VERSION "HNNBNNNYNNNNNNNNNNNNNNNNNNNNNNNNNNNNNNNNNN/4/%%%/4/'%**4NNN///"

NS_ :

BS_:

BU_: BAP_Tester CGS Gateway Gateway_PAG HUD Kombi Kombi_LB Kombi_PAG Waehlhebel_SB

BO_ 1607 Motor_09: 8 Gateway
 SG_ MO_ITM_Kuehlmittel_Temp : 0|8@1+ (0.75,-48) [-45.75|143.25] "Unit_DegreCelsi"  Kombi,Kombi_LB,Kombi_PAG
 SG_ MO_E85_Sensor : 8|4@1+ (10,0) [0|100] "Unit_PerCent"  Vector__XXX
 SG_ SCR_Anz_Motorstarts : 12|4@1+ (1.0,0.0) [0.0|15] ""  Vector__XXX
 SG_ SCR_Reichweite : 16|15@1+ (1,0) [0|32766] "Unit_KiloMeter"  Vector__XXX
 SG_ MO_Ethanol_Spuelhinweis : 31|1@1+ (1.0,0.0) [0.0|1] ""  Vector__XXX
 SG_ SCR_Warnstufe_1 : 32|1@1+ (1.0,0.0) [0.0|1] ""  Vector__XXX
 SG_ SCR_Warnstufe_2 : 33|1@1+ (1.0,0.0) [0.0|1] ""  Vector__XXX
 SG_ SCR_Text : 34|3@1+ (1.0,0.0) [0.0|7] ""  Kombi,Kombi_PAG
 SG_ SCR_Akustik : 37|2@1+ (1.0,0.0) [0.0|3] ""  Vector__XXX
 SG_ SCR_verbaut : 39|1@1+ (1.0,0.0) [0.0|1] ""  Kombi,Kombi_PAG
 SG_ MO_Kraftstofffilter_Wasser : 40|1@1+ (1.0,0.0) [0.0|1] ""  Kombi,Kombi_LB,Kombi_PAG
 SG_ SCR_Systemfehler : 41|1@1+ (1.0,0.0) [0.0|1] ""  Vector__XXX
 SG_ SCR_Inducement_Strategie : 42|2@1+ (1.0,0.0) [0.0|3] ""  Kombi,Kombi_PAG
 SG_ MO_CO2_Faktor : 44|12@1+ (1,0) [1|4094] "Unit_GramPerLiter"  Vector__XXX
 SG_ MO_MKB_MUX M  : 56|2@1+ (1.0,0.0) [0.0|3] ""  Kombi,Kombi_LB,Kombi_PAG
 SG_ MO_MKB_01 m0  : 59|5@1+ (1.0,0.0) [0.0|31] ""  Kombi,Kombi_LB,Kombi_PAG
 SG_ MO_MKB_02 m1  : 59|5@1+ (1.0,0.0) [0.0|31] ""  Kombi,Kombi_LB,Kombi_PAG
 SG_ MO_MKB_03 m2  : 59|5@1+ (1.0,0.0) [0.0|31] ""  Kombi,Kombi_LB,Kombi_PAG
 SG_ MO_MKB_04 m3  : 59|5@1+ (1.0,0.0) [0.0|31] ""  Kombi,Kombi_LB,Kombi_PAG

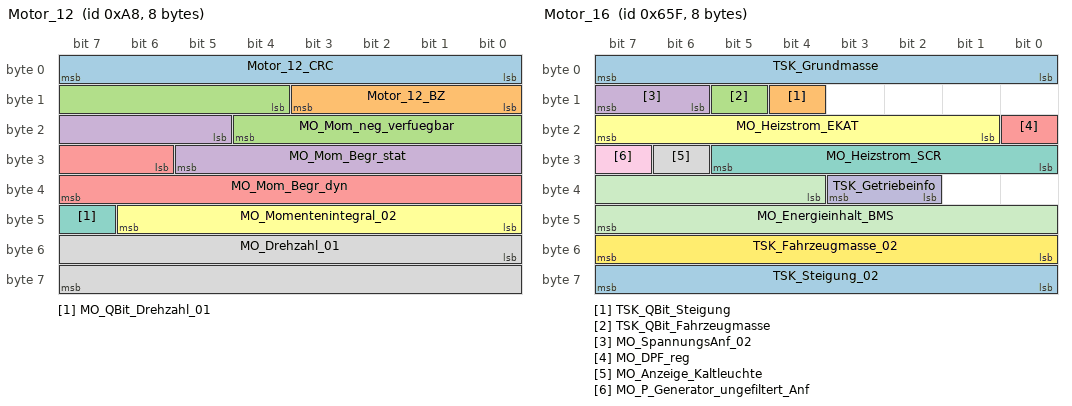
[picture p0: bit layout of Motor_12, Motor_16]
BO_ 168 Motor_12: 8 Gateway
 SG_ Motor_12_CRC : 0|8@1+ (1,0) [0|255] ""  Vector__XXX
 SG_ Motor_12_BZ : 8|4@1+ (1,0) [0|15] ""  Vector__XXX
 SG_ MO_Mom_neg_verfuegbar : 12|9@1+ (1,-509) [-509|0] ""  Vector__XXX
 SG_ MO_Mom_Begr_stat : 21|9@1+ (1,0) [0|509] ""  Vector__XXX
 SG_ MO_Mom_Begr_dyn : 30|10@1+ (1,-509) [-509|509] ""  Vector__XXX
 SG_ MO_Momentenintegral_02 : 40|7@1+ (1,0) [0|100] "Unit_PerCent"  Vector__XXX
 SG_ MO_QBit_Drehzahl_01 : 47|1@1+ (1.0,0.0) [0.0|1] ""  Vector__XXX
 SG_ MO_Drehzahl_01 : 48|16@1+ (0.25,0) [0.00|16383.00] "Unit_MinutInver"  Kombi,Kombi_LB,Kombi_PAG

BO_ 958 Motor_14: 8 Gateway
 SG_ Motor_14_CRC : 0|8@1+ (1,0) [0|255] ""  CGS,Kombi_PAG
 SG_ Motor_14_BZ : 8|4@1+ (1,0) [0|15] ""  CGS,Kombi_PAG
 SG_ MO_StartStopp_Status : 12|2@1+ (1.0,0.0) [0.0|3] ""  Vector__XXX
 SG_ MO_StartStopp_Wiederstart : 14|1@1+ (1.0,0.0) [0.0|1] ""  CGS,Kombi,Kombi_LB,Kombi_PAG,Waehlhebel_SB
 SG_ MO_StartStopp_Motorstopp : 15|1@1+ (1.0,0.0) [0.0|1] ""  Kombi,Kombi_LB,Kombi_PAG
 SG_ MO_Freig_Reku : 16|2@1+ (1.0,0.0) [0.0|3] ""  Vector__XXX
 SG_ MO_Kl_75 : 18|1@1+ (1.0,0.0) [0.0|1] ""  CGS,Kombi,Kombi_LB,Kombi_PAG,Waehlhebel_SB
 SG_ MO_Kl_50 : 19|1@1+ (1.0,0.0) [0.0|1] ""  Vector__XXX
 SG_ MO_Gangposition : 20|4@1+ (1.0,0.0) [0.0|15] ""  Kombi,Kombi_PAG
 SG_ MO_StartStopp_Fahrerwunsch : 24|2@1+ (1.0,0.0) [0.0|3] ""  Vector__XXX
 SG_ MO_HYB_Fahrbereitschaft : 26|1@1+ (1.0,0.0) [0.0|1] ""  Kombi,Kombi_LB,Kombi_PAG
 SG_ MO_Ext_E_Fahrt_aktiv : 27|1@1+ (1.0,0.0) [0.0|1] ""  Kombi,Kombi_LB,Kombi_PAG
 SG_ MO_Fahrer_bremst : 28|1@1+ (1.0,0.0) [0.0|1] ""  CGS
 SG_ MO_QBit_Fahrer_bremst : 29|1@1+ (1.0,0.0) [0.0|1] ""  CGS
 SG_ MO_BLS : 30|1@1+ (1.0,0.0) [0.0|1] ""  CGS
 SG_ MO_Konsistenz_Bremsped : 31|1@1+ (1.0,0.0) [0.0|1] ""  CGS
 SG_ MO_KomFehler_ESP : 32|1@1+ (1.0,0.0) [0.0|1] ""  Vector__XXX
 SG_ MO_Klima_Eingr : 33|2@1+ (1.0,0.0) [0.0|3] ""  Vector__XXX
 SG_ MO_Aussp_Anlass : 35|1@1+ (1.0,0.0) [0.0|1] ""  Vector__XXX
 SG_ MO_Freig_Anlass : 36|1@1+ (1.0,0.0) [0.0|1] ""  Vector__XXX
 SG_ MO_Kuppl_schalter : 37|1@1+ (1.0,0.0) [0.0|1] ""  Kombi,Kombi_LB
 SG_ MO_Interlock : 38|1@1+ (1.0,0.0) [0.0|1] ""  Vector__XXX
 SG_ MO_Motor_laeuft : 39|1@1+ (1.0,0.0) [0.0|1] ""  Kombi,Kombi_LB,Kombi_PAG
 SG_ MO_Kickdown : 40|1@1+ (1.0,0.0) [0.0|1] ""  Vector__XXX
 SG_ MO_QBit_KL_75 : 41|1@1+ (1.0,0.0) [0.0|1] ""  CGS,Waehlhebel_SB
 SG_ MO_EKlKomLeiRed : 42|2@1+ (1.0,0.0) [0.0|3] ""  Vector__XXX
 SG_ MO_Handshake_STH : 44|1@1+ (1.0,0.0) [0.0|1] ""  Vector__XXX
 SG_ MO_BKV_Unterdruckwarnung : 45|1@1+ (1.0,0.0) [0.0|1] ""  Vector__XXX
 SG_ MO_Freigabe_Segeln : 46|1@1+ (1.0,0.0) [0.0|1] ""  Vector__XXX
 SG_ MO_PTC_Status : 47|3@1+ (1.0,0.0) [0.0|7] ""  Vector__XXX
 SG_ MO_QBit_Gangposition : 50|1@1+ (1.0,0.0) [0.0|1] ""  Vector__XXX
 SG_ MO_Signalquelle_Gangposition : 51|1@1+ (1.0,0.0) [0.0|1] ""  Vector__XXX
 SG_ MO_Remotestart_Betrieb : 52|1@1+ (1.0,0.0) [0.0|1] ""  Vector__XXX
 SG_ MO_Remotestart_moeglich : 53|1@1+ (1.0,0.0) [0.0|1] ""  Vector__XXX
 SG_ MO_Text_Geschw_red : 54|1@1+ (1.0,0.0) [0.0|1] ""  Kombi,Kombi_LB,Kombi_PAG
 SG_ MO_FMAus_aktiv : 55|1@1+ (1.0,0.0) [0.0|1] ""  Vector__XXX
 SG_ MO_FMAus_Startvariante : 56|2@1+ (1.0,0.0) [0.0|3] ""  Vector__XXX
 SG_ MO_BMS_NV_Anf_stuetzen : 58|1@1+ (1.0,0.0) [0.0|1] ""  Vector__XXX
 SG_ MO_Zylinderabschaltung : 59|2@1+ (1.0,0.0) [0.0|3] ""  Vector__XXX
 SG_ MO_HYB_VM_aktiv : 61|1@1+ (1.0,0.0) [0.0|1] ""  Kombi,Kombi_LB,Kombi_PAG
 SG_ MO_StartVorauss_erfuellt : 62|2@1+ (1.0,0.0) [0.0|3] ""  Vector__XXX

BO_ 1631 Motor_16: 8 Gateway
 SG_ TSK_Grundmasse : 0|8@1+ (32,0) [0|8128] "Unit_KiloGram"  Vector__XXX
 SG_ TSK_QBit_Steigung : 12|1@1+ (1.0,0.0) [0.0|1] ""  Vector__XXX
 SG_ TSK_QBit_Fahrzeugmasse : 13|1@1+ (1.0,0.0) [0.0|1] ""  Vector__XXX
 SG_ MO_SpannungsAnf_02 : 14|2@1+ (1.0,0.0) [0.0|3] ""  Vector__XXX
 SG_ MO_DPF_reg : 16|1@1+ (1.0,0.0) [0.0|1] ""  Vector__XXX
 SG_ MO_Heizstrom_EKAT : 17|7@1+ (1,0) [0|126] "Unit_Amper"  Vector__XXX
 SG_ MO_Heizstrom_SCR : 24|6@1+ (1,0) [0|62] "Unit_Amper"  Vector__XXX
 SG_ MO_Anzeige_Kaltleuchte : 30|1@1+ (1.0,0.0) [0.0|1] ""  Kombi,Kombi_LB,Kombi_PAG
 SG_ MO_P_Generator_ungefiltert_Anf : 31|1@1+ (1.0,0.0) [0.0|1] ""  Vector__XXX
 SG_ TSK_Getriebeinfo : 34|2@1+ (1.0,0.0) [0.0|3] ""  Vector__XXX
 SG_ MO_Energieinhalt_BMS : 36|12@1+ (25,0) [0|102325] "Unit_WattHour"  Kombi,Kombi_LB,Kombi_PAG
 SG_ TSK_Fahrzeugmasse_02 : 48|8@1+ (32,0) [0|8128] "Unit_KiloGram"  Vector__XXX
 SG_ TSK_Steigung_02 : 56|8@1+ (0.8,-101.6) [-100.8|101.6] "Unit_PerCent"  Vector__XXX

BO_ 812 Motor_17: 8 Gateway
 SG_ MO_Sperrung_FahrPr_BZS : 0|8@1+ (1.0,0.0) [0.0|255] ""  Kombi_LB
 SG_ MO_Rampenzeit_Generator_Anf : 8|4@1+ (1.0,0.0) [0.0|15] ""  Vector__XXX
 SG_ MO_Prio_MAX_Wunschdrehzahl : 12|1@1+ (1.0,0.0) [0.0|1] ""  Kombi,Kombi_LB
 SG_ MO_Prio_MIN_Wunschdrehzahl : 13|1@1+ (1.0,0.0) [0.0|1] ""  Vector__XXX
 SG_ MO_Luftpfad_aktiv : 14|1@1+ (1.0,0.0) [0.0|1] ""  Vector__XXX
 SG_ MO_v_Begrenz_Aktivierbar : 15|1@1+ (1.0,0.0) [0.0|1] ""  Vector__XXX
 SG_ MO_Drehzahlbeeinflussung : 16|8@1+ (0.39,0) [0.00|99.45] "Unit_PerCent"  Vector__XXX
 SG_ MO_MIN_Wunschdrehzahl : 24|8@1+ (25,0) [0|6350] "Unit_MinutInver"  Vector__XXX
 SG_ MO_MAX_Wunschdrehzahl : 32|9@1+ (25,0) [0|12750] "Unit_MinutInver"  HUD,Kombi,Kombi_LB,Kombi_PAG
 SG_ MO_Charisma_FahrPr : 41|4@1+ (1.0,0.0) [0.0|15] ""  Vector__XXX
 SG_ MO_Charisma_Status : 45|2@1+ (1.0,0.0) [0.0|3] ""  Vector__XXX
 SG_ MO_StSt_Charisma_FahrPr : 47|4@1+ (1.0,0.0) [0.0|15] ""  Vector__XXX
 SG_ MO_StSt_Charisma_Status : 51|2@1+ (1.0,0.0) [0.0|3] ""  Vector__XXX
 SG_ MO_BZS_Charisma_FahrPr : 53|4@1+ (1.0,0.0) [0.0|15] ""  Vector__XXX
 SG_ MO_BZS_Charisma_Status : 57|2@1+ (1.0,0.0) [0.0|3] ""  Vector__XXX
 SG_ MO_NGS_Position : 59|1@1+ (1.0,0.0) [0.0|1] ""  Vector__XXX
 SG_ MO_NGS_Status : 60|2@1+ (1.0,0.0) [0.0|3] ""  Vector__XXX
 SG_ MO_v_Begrenzung_Niveau : 62|2@1+ (1.0,0.0) [0.0|3] ""  Vector__XXX

BO_ 1648 Motor_18: 8 Gateway
 SG_ MO_max_Ladedruck : 0|6@1+ (0.1,0) [0.0|6.3] "Unit_Bar"  Kombi,Kombi_PAG
 SG_ MO_ANC_Kennfeld_Anf : 6|2@1+ (1.0,0.0) [0.0|3] ""  Vector__XXX
 SG_ MO_Bremslicht_Reku : 8|1@1+ (1.0,0.0) [0.0|1] ""  Vector__XXX
 SG_ MO_StartStopp_PopUp : 9|2@1+ (1.0,0.0) [0.0|3] ""  Kombi,Kombi_LB,Kombi_PAG
 SG_ MO1_Sperr_Info_WFS : 11|1@1+ (1.0,0.0) [0.0|1] ""  Vector__XXX
 SG_ MO1_Freigabe_Info_WFS : 12|1@1+ (1.0,0.0) [0.0|1] ""  Vector__XXX
 SG_ MO_EPCL : 13|3@1+ (1.0,0.0) [0.0|7] ""  Kombi,Kombi_LB,Kombi_PAG
 SG_ MO_Zylabsch_Texte_02 : 16|4@1+ (1.0,0.0) [0.0|15] ""  Kombi,Kombi_LB
 SG_ MO_Fahrzeugtyp : 20|3@1+ (1.0,0.0) [0.0|7] ""  Kombi,Kombi_LB,Kombi_PAG
 SG_ MO_NMAX_Schaltanzeige : 23|9@1+ (25,0) [0|12775] "Unit_MinutInver"  Vector__XXX
 SG_ MO_Abstellzeit : 32|8@1+ (8,0) [0|2024] "Unit_Minut"  Vector__XXX
 SG_ MO_Abstellzeit_Status : 40|2@1+ (1.0,0.0) [0.0|3] ""  Vector__XXX
 SG_ MO1_Freigabe_Verfallsinfo_WFS : 42|1@1+ (1.0,0.0) [0.0|1] ""  Vector__XXX
 SG_ MO_Hybrid_StartStopp_LED : 43|2@1+ (1.0,0.0) [0.0|3] ""  Vector__XXX
 SG_ MO_Fehler_Zylabsch : 45|2@1+ (1.0,0.0) [0.0|3] ""  Vector__XXX
 SG_ MO_Anzahl_Abgesch_Zyl : 47|3@1+ (1.0,0.0) [0.0|7] ""  Vector__XXX
 SG_ MO_Zylabsch_Texte : 50|2@1+ (1.0,0.0) [0.0|3] ""  Vector__XXX
 SG_ MO_Ethanol_BS_Texte : 52|3@1+ (1.0,0.0) [0.0|7] ""  Kombi,Kombi_LB,Kombi_PAG
 SG_ MO_Drehzahl_Warnung : 55|1@1+ (1.0,0.0) [0.0|1] ""  Kombi,Kombi_LB,Kombi_PAG
 SG_ MO_obere_Drehzahlgrenze : 56|8@1+ (50,0) [50|12750] "Unit_MinutInver"  HUD,Kombi,Kombi_LB,Kombi_PAG

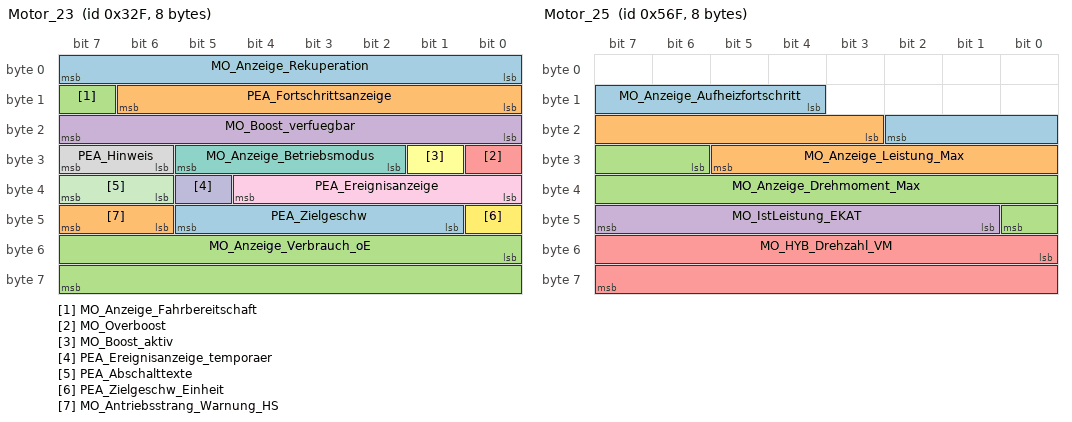
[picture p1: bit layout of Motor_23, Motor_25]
BO_ 815 Motor_23: 8 Gateway
 SG_ MO_Anzeige_Rekuperation : 0|8@1+ (0.5,-0.5) [0.0|100.0] "Unit_PerCent"  Kombi,Kombi_LB
 SG_ PEA_Fortschrittsanzeige : 8|7@1+ (1,0) [0|100] "Unit_PerCent"  HUD,Kombi,Kombi_LB
 SG_ MO_Anzeige_Fahrbereitschaft : 15|1@1+ (1.0,0.0) [0.0|1] ""  HUD,Kombi,Kombi_LB,Kombi_PAG
 SG_ MO_Boost_verfuegbar : 16|8@1+ (0.4,-0.4) [0.0|100.4] "Unit_PerCent"  HUD,Kombi,Kombi_LB,Kombi_PAG
 SG_ MO_Overboost : 24|1@1+ (1.0,0.0) [0.0|1] ""  Kombi,Kombi_LB,Kombi_PAG
 SG_ MO_Boost_aktiv : 25|1@1+ (1.0,0.0) [0.0|1] ""  HUD,Kombi,Kombi_LB,Kombi_PAG
 SG_ MO_Anzeige_Betriebsmodus : 26|4@1+ (1.0,0.0) [0.0|15] ""  Kombi,Kombi_LB,Kombi_PAG
 SG_ PEA_Hinweis : 30|2@1+ (1.0,0.0) [0.0|3] ""  HUD,Kombi,Kombi_LB,Kombi_PAG
 SG_ PEA_Ereignisanzeige : 32|5@1+ (1.0,0.0) [0.0|31] ""  HUD,Kombi,Kombi_LB,Kombi_PAG
 SG_ PEA_Ereignisanzeige_temporaer : 37|1@1+ (1.0,0.0) [0.0|1] ""  Kombi,Kombi_LB,Kombi_PAG
 SG_ PEA_Abschalttexte : 38|2@1+ (1.0,0.0) [0.0|3] ""  HUD,Kombi,Kombi_LB,Kombi_PAG
 SG_ PEA_Zielgeschw_Einheit : 40|1@1+ (1.0,0.0) [0.0|1] ""  HUD,Kombi,Kombi_LB,Kombi_PAG
 SG_ PEA_Zielgeschw : 41|5@1+ (1.0,0.0) [0.0|31] ""  HUD,Kombi,Kombi_LB,Kombi_PAG
 SG_ MO_Antriebsstrang_Warnung_HS : 46|2@1+ (1.0,0.0) [0.0|3] ""  Kombi,Kombi_LB,Kombi_PAG
 SG_ MO_Anzeige_Verbrauch_oE : 48|16@1+ (0.005,0) [0.000|327.675] "Unit_None"  Kombi,Kombi_LB,Kombi_PAG

BO_ 1391 Motor_25: 8 Gateway
 SG_ MO_Anzeige_Aufheizfortschritt : 12|7@1+ (1,0) [0|100] "Unit_PerCent"  Kombi_PAG
 SG_ MO_Anzeige_Leistung_Max : 19|11@1+ (0.6,0) [0.0|1227.0] "Unit_KiloWatt"  Kombi,Kombi_LB,Kombi_PAG
 SG_ MO_Anzeige_Drehmoment_Max : 30|11@1+ (1,0) [0|2045] "Unit_NewtoMeter"  Kombi,Kombi_LB,Kombi_PAG
 SG_ MO_IstLeistung_EKAT : 41|7@1+ (20,0) [0|2500] "Unit_Watt"  Vector__XXX
 SG_ MO_HYB_Drehzahl_VM : 48|16@1+ (0.25,0) [0.00|16256.00] "Unit_MinutInver"  Vector__XXX

BO_ 967 Motor_26: 8 Gateway
 SG_ MO_Kuehlerluefter_MUX M  : 0|1@1+ (1.0,0.0) [0.0|1] ""  Vector__XXX
 SG_ MO_Kuehlerluefter_1 m0  : 1|7@1+ (1,0) [0|100] "Unit_PerCent"  Vector__XXX
 SG_ MO_Kuehlerluefter_2 m1  : 1|7@1+ (1,0) [0|100] "Unit_PerCent"  Vector__XXX
 SG_ MO_EFLEX_Lampe : 8|2@1+ (1.0,0.0) [0.0|3] ""  Vector__XXX
 SG_ MO_KJS_nicht_bereit : 10|1@1+ (1.0,0.0) [0.0|1] ""  Kombi,Kombi_LB,Kombi_PAG
 SG_ MO_ITM_Warnung_Pumpe : 11|1@1+ (1.0,0.0) [0.0|1] ""  Kombi,Kombi_LB,Kombi_PAG
 SG_ WIV_Anzeige_aktiv : 12|1@1+ (1.0,0.0) [0.0|1] ""  Vector__XXX
 SG_ WIV_Oelmin_Warn : 13|1@1+ (1.0,0.0) [0.0|1] ""  Kombi,Kombi_LB,Kombi_PAG
 SG_ WIV_Sensorfehler : 14|1@1+ (1.0,0.0) [0.0|1] ""  Kombi,Kombi_LB,Kombi_PAG
 SG_ WIV_Schieflage : 15|1@1+ (1.0,0.0) [0.0|1] ""  Kombi,Kombi_PAG
 SG_ WIV_Oelstand : 16|4@1+ (12.5,0) [0.0|100.0] "Unit_PerCent"  Kombi,Kombi_LB,Kombi_PAG
 SG_ MO_Zustand_HWP : 20|2@1+ (1.0,0.0) [0.0|3] ""  Vector__XXX
 SG_ OLEV_Systemstoerung : 22|1@1+ (1.0,0.0) [0.0|1] ""  Kombi,Kombi_LB,Kombi_PAG
 SG_ MO_Oelwarnung_max : 23|1@1+ (1.0,0.0) [0.0|1] ""  Kombi,Kombi_LB,Kombi_PAG
 SG_ WIV_Oelsystem_aktiv : 24|1@1+ (1.0,0.0) [0.0|1] ""  Kombi,Kombi_LB,Kombi_PAG
 SG_ WIV_nicht_betriebswarm : 25|1@1+ (1.0,0.0) [0.0|1] ""  Kombi,Kombi_PAG
 SG_ WIV_Ueberfuell_Warn : 26|1@1+ (1.0,0.0) [0.0|1] ""  Kombi,Kombi_LB,Kombi_PAG
 SG_ WIV_laufender_Motor : 27|1@1+ (1.0,0.0) [0.0|1] ""  Vector__XXX
 SG_ MO_E_Warnungen : 28|4@1+ (1.0,0.0) [0.0|15] ""  Kombi,Kombi_LB,Kombi_PAG
 SG_ MO_Text_Motorstart : 32|4@1+ (1.0,0.0) [0.0|15] ""  Kombi,Kombi_LB,Kombi_PAG
 SG_ MO_E_Texte : 36|4@1+ (1.0,0.0) [0.0|15] ""  HUD,Kombi,Kombi_LB,Kombi_PAG
 SG_ WIV_Oeldyn_avl : 40|1@1+ (1.0,0.0) [0.0|1] ""  Vector__XXX
 SG_ MO_Text_Partikelfil_Reg : 41|1@1+ (1,0) [0|1] ""  Kombi,Kombi_LB,Kombi_PAG
 SG_ OLEV_Oelstand_nicht_vorhanden : 42|1@1+ (1.0,0.0) [0.0|1] ""  Kombi,Kombi_LB,Kombi_PAG
 SG_ WIV_Oelmenge : 43|5@1+ (125,0) [0|3875] "Unit_MilliLiter"  Kombi,Kombi_LB,Kombi_PAG
 SG_ MO_Systemlampe : 48|1@1+ (1.0,0.0) [0.0|1] ""  Vector__XXX
 SG_ MO_OBD2_Lampe : 49|1@1+ (1.0,0.0) [0.0|1] ""  Kombi,Kombi_LB,Kombi_PAG
 SG_ MO_Heissleuchte : 50|1@1+ (1.0,0.0) [0.0|1] ""  Kombi,Kombi_LB,Kombi_PAG
 SG_ MO_Partikel_Lampe : 51|1@1+ (1.0,0.0) [0.0|1] ""  Kombi,Kombi_LB,Kombi_PAG
 SG_ MO_RedFahrleistung_Lampe : 52|1@1+ (1.0,0.0) [0.0|1] ""  HUD,Kombi,Kombi_LB,Kombi_PAG
 SG_ WIV_Oelstand_nicht_vorhanden : 53|1@1+ (1.0,0.0) [0.0|1] ""  Kombi,Kombi_LB,Kombi_PAG
 SG_ WIV_nachfuellanzeige_ein : 54|1@1+ (1.0,0.0) [0.0|1] ""  Kombi,Kombi_LB,Kombi_PAG
 SG_ WIV_Ueberfuell_deaktiv : 55|1@1+ (1.0,0.0) [0.0|1] ""  Kombi,Kombi_LB,Kombi_PAG
 SG_ WIV_Unterfuell_Warn : 56|1@1+ (1.0,0.0) [0.0|1] ""  Kombi,Kombi_LB,Kombi_PAG
 SG_ MO_Tankdeckel_Lampe : 57|1@1+ (1.0,0.0) [0.0|1] ""  Vector__XXX
 SG_ MO_Text_Tankdeckelwarn : 58|1@1+ (1.0,0.0) [0.0|1] ""  Kombi,Kombi_LB
 SG_ MO_Vorglueh_Lampe : 59|1@1+ (1.0,0.0) [0.0|1] ""  Kombi,Kombi_LB,Kombi_PAG
 SG_ WIV_Oeldr_Warn_Motor : 60|1@1+ (1.0,0.0) [0.0|1] ""  Kombi,Kombi_LB,Kombi_PAG
 SG_ MO_E_Mode : 61|3@1+ (1.0,0.0) [0.0|7] ""  Kombi,Kombi_LB,Kombi_PAG

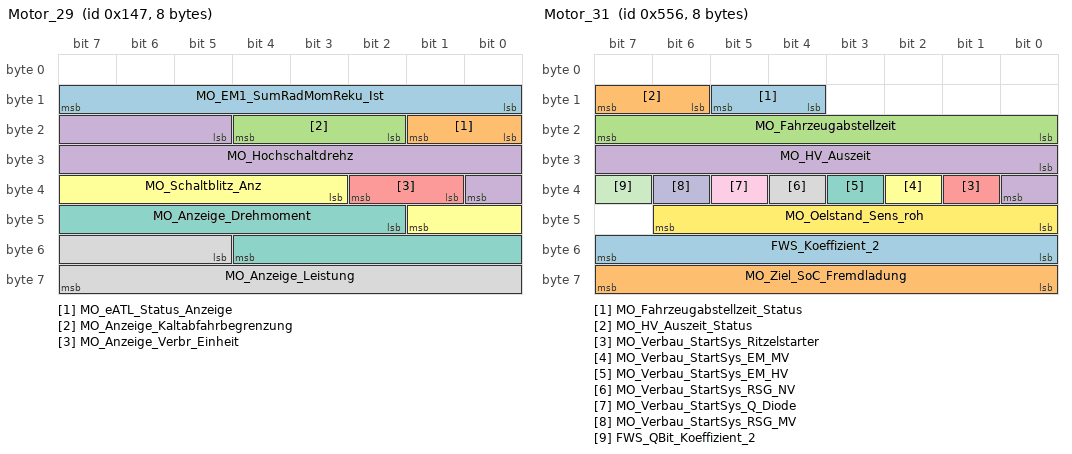
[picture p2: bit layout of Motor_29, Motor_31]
BO_ 327 Motor_29: 8 Gateway
 SG_ MO_EM1_SumRadMomReku_Ist : 8|8@1+ (10,0) [0|2530] "Unit_NewtoMeter"  Vector__XXX
 SG_ MO_eATL_Status_Anzeige : 16|2@1+ (1.0,0.0) [0.0|3] ""  Kombi_PAG
 SG_ MO_Anzeige_Kaltabfahrbegrenzung : 18|3@1+ (1.0,0.0) [0.0|7] ""  Kombi_PAG
 SG_ MO_Hochschaltdrehz : 21|12@1+ (3,0) [3|12282] "Unit_MinutInver"  HUD,Kombi,Kombi_LB
 SG_ MO_Anzeige_Verbr_Einheit : 33|2@1+ (1.0,0.0) [0.0|3] ""  Kombi,Kombi_LB
 SG_ MO_Schaltblitz_Anz : 35|7@1+ (1,0) [0|100] "Unit_PerCent"  HUD,Kombi,Kombi_LB,Kombi_PAG
 SG_ MO_Anzeige_Drehmoment : 42|11@1+ (1,0) [0|2045] "Unit_NewtoMeter"  Kombi,Kombi_LB,Kombi_PAG
 SG_ MO_Anzeige_Leistung : 53|11@1+ (0.6,0) [0.0|1227.0] "Unit_KiloWatt"  Kombi,Kombi_LB,Kombi_PAG

BO_ 1366 Motor_31: 8 Gateway
 SG_ MO_Fahrzeugabstellzeit_Status : 12|2@1+ (1.0,0.0) [0.0|3] ""  Vector__XXX
 SG_ MO_HV_Auszeit_Status : 14|2@1+ (1.0,0.0) [0.0|3] ""  Vector__XXX
 SG_ MO_Fahrzeugabstellzeit : 16|8@1+ (8,0) [0|2024] "Unit_Minut"  Vector__XXX
 SG_ MO_HV_Auszeit : 24|9@1+ (4,0) [0|2036] "Unit_Minut"  Vector__XXX
 SG_ MO_Verbau_StartSys_Ritzelstarter : 33|1@1+ (1.0,0.0) [0.0|1] ""  Kombi,Kombi_LB,Kombi_PAG
 SG_ MO_Verbau_StartSys_EM_MV : 34|1@1+ (1.0,0.0) [0.0|1] ""  Kombi,Kombi_LB,Kombi_PAG
 SG_ MO_Verbau_StartSys_EM_HV : 35|1@1+ (1.0,0.0) [0.0|1] ""  Kombi,Kombi_LB,Kombi_PAG
 SG_ MO_Verbau_StartSys_RSG_NV : 36|1@1+ (1.0,0.0) [0.0|1] ""  Kombi,Kombi_LB,Kombi_PAG
 SG_ MO_Verbau_StartSys_Q_Diode : 37|1@1+ (1.0,0.0) [0.0|1] ""  Kombi,Kombi_LB,Kombi_PAG
 SG_ MO_Verbau_StartSys_RSG_MV : 38|1@1+ (1.0,0.0) [0.0|1] ""  Kombi,Kombi_LB,Kombi_PAG
 SG_ FWS_QBit_Koeffizient_2 : 39|1@1+ (1.0,0.0) [0.0|1] ""  Vector__XXX
 SG_ MO_Oelstand_Sens_roh : 40|7@1+ (1,0) [0|127] "Unit_MilliMeter"  Kombi,Kombi_PAG
 SG_ FWS_Koeffizient_2 : 48|8@1+ (0.002,0) [0.000|0.506] "Unit_NewtonPer_Kmh_Squar"  Vector__XXX
 SG_ MO_Ziel_SoC_Fremdladung : 56|8@1+ (0.4,0) [0.0|100.0] "Unit_PerCent"  Vector__XXX

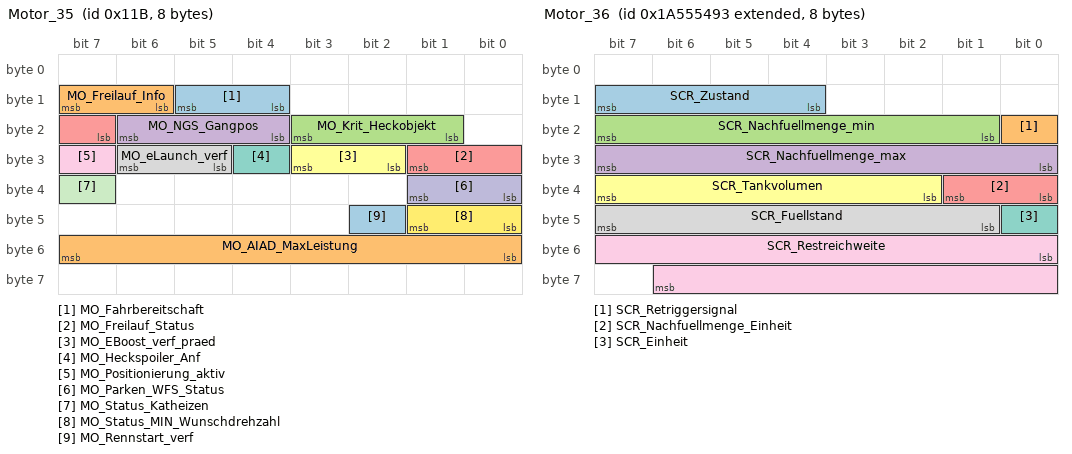
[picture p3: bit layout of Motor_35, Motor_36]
BO_ 283 Motor_35: 8 Gateway
 SG_ MO_Fahrbereitschaft : 12|2@1+ (1.0,0.0) [0.0|3] ""  Vector__XXX
 SG_ MO_Freilauf_Info : 14|2@1+ (1.0,0.0) [0.0|3] ""  Vector__XXX
 SG_ MO_Krit_Heckobjekt : 17|3@1+ (1.0,0.0) [0.0|7] ""  Vector__XXX
 SG_ MO_NGS_Gangpos : 20|3@1+ (1.0,0.0) [0.0|7] ""  Vector__XXX
 SG_ MO_Freilauf_Status : 23|3@1+ (1.0,0.0) [0.0|7] ""  Kombi,Kombi_LB
 SG_ MO_EBoost_verf_praed : 26|2@1+ (1.0,0.0) [0.0|3] ""  Vector__XXX
 SG_ MO_Heckspoiler_Anf : 28|1@1+ (1.0,0.0) [0.0|1] ""  Vector__XXX
 SG_ MO_eLaunch_verf : 29|2@1+ (1.0,0.0) [0.0|3] ""  Vector__XXX
 SG_ MO_Positionierung_aktiv : 31|1@1+ (1.0,0.0) [0.0|1] ""  Vector__XXX
 SG_ MO_Parken_WFS_Status : 32|2@1+ (1.0,0.0) [0.0|3] ""  Vector__XXX
 SG_ MO_Status_Katheizen : 39|1@1+ (1.0,0.0) [0.0|1] ""  Vector__XXX
 SG_ MO_Status_MIN_Wunschdrehzahl : 40|2@1+ (1.0,0.0) [0.0|3] ""  Vector__XXX
 SG_ MO_Rennstart_verf : 42|1@1+ (1.0,0.0) [0.0|1] ""  Kombi,Kombi_PAG
 SG_ MO_AIAD_MaxLeistung : 48|8@1+ (100,0) [0|25400] "Unit_Watt"  Vector__XXX

BO_ 2589283475 Motor_36: 8 Gateway
 SG_ SCR_Zustand : 12|4@1+ (1.0,0.0) [0.0|15] ""  Kombi,Kombi_LB,Kombi_PAG
 SG_ SCR_Retriggersignal : 16|1@1+ (1.0,0.0) [0.0|1] ""  Kombi,Kombi_PAG
 SG_ SCR_Nachfuellmenge_min : 17|7@1+ (0.25,0) [0.00|31.50] ""  Kombi,Kombi_PAG
 SG_ SCR_Nachfuellmenge_max : 24|8@1+ (0.25,0) [0.00|63.50] ""  Kombi,Kombi_PAG
 SG_ SCR_Nachfuellmenge_Einheit : 32|2@1+ (1.0,0.0) [0.0|3] ""  Kombi,Kombi_PAG
 SG_ SCR_Tankvolumen : 34|6@1+ (1,0) [0|63] ""  Kombi_PAG
 SG_ SCR_Einheit : 40|1@1+ (1.0,0.0) [0.0|1] ""  Kombi,Kombi_PAG
 SG_ SCR_Fuellstand : 41|7@1+ (1,0) [0|100] "Unit_PerCent"  Kombi_PAG
 SG_ SCR_Restreichweite : 48|15@1+ (1,0) [0|32767] ""  Kombi,Kombi_PAG

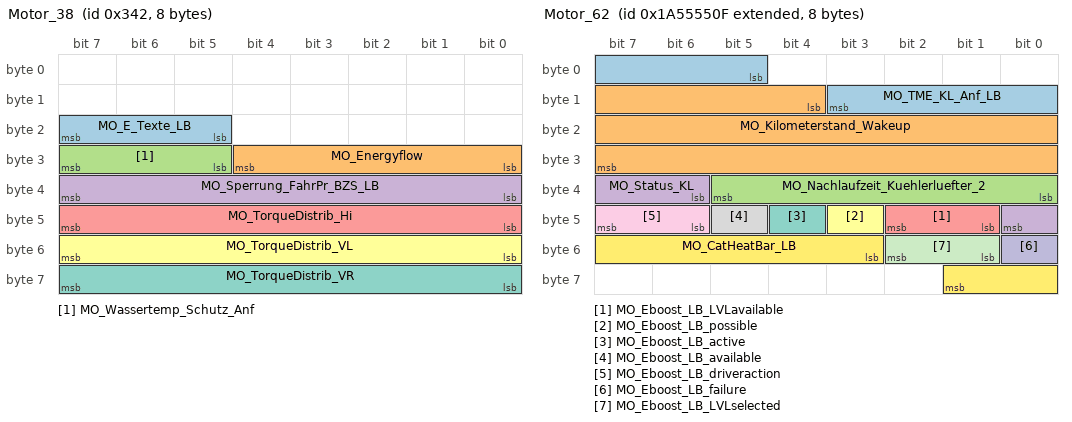
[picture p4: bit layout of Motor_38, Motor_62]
BO_ 834 Motor_38: 8 Gateway
 SG_ MO_E_Texte_LB : 21|3@1+ (1.0,0.0) [0.0|7] ""  Kombi_LB
 SG_ MO_Energyflow : 24|5@1+ (1.0,0.0) [0.0|31] ""  Kombi_LB
 SG_ MO_Wassertemp_Schutz_Anf : 29|3@1+ (1.0,0.0) [0.0|7] ""  Kombi_LB
 SG_ MO_Sperrung_FahrPr_BZS_LB : 32|8@1+ (1.0,0.0) [0.0|255] ""  Kombi_LB
 SG_ MO_TorqueDistrib_Hi : 40|8@1+ (1,-100) [-100|100] "Unit_PerCent"  Kombi_LB
 SG_ MO_TorqueDistrib_VL : 48|8@1+ (1,-100) [-100|100] "Unit_PerCent"  Kombi_LB
 SG_ MO_TorqueDistrib_VR : 56|8@1+ (1,-100) [-100|100] "Unit_PerCent"  Kombi_LB

BO_ 706 Motor_41: 8 Gateway
 SG_ MO_Anzeige_StSt_Text : 12|4@1+ (1.0,0.0) [0.0|15] ""  Kombi,Kombi_LB,Kombi_PAG
 SG_ MO_Anzeige_StSt_Symbol : 16|3@1+ (1.0,0.0) [0.0|7] ""  Kombi,Kombi_LB,Kombi_PAG
 SG_ MO_ADR_Status : 19|2@1+ (1.0,0.0) [0.0|3] ""  Vector__XXX
 SG_ MO_AGA_Sound_Texte : 21|2@1+ (1.0,0.0) [0.0|3] ""  Kombi,Kombi_LB
 SG_ MO_Anzeige_FMAus_Text : 23|1@1+ (1.0,0.0) [0.0|1] ""  Vector__XXX
 SG_ MO_Fehler_MSpG : 24|1@1+ (1.0,0.0) [0.0|1] ""  Kombi,Kombi_PAG
 SG_ PEA_Texte : 25|3@1+ (1.0,0.0) [0.0|7] ""  Kombi,Kombi_LB,Kombi_PAG
 SG_ TSK_Ueberstimmt_vMax_FahrerInfo : 28|2@1+ (1.0,0.0) [0.0|3] ""  Kombi,Kombi_LB,Kombi_PAG
 SG_ MO_Avus_Motorschutz : 30|2@1+ (1.0,0.0) [0.0|3] ""  Kombi,Kombi_PAG
 SG_ MO_Rekuperationsstufe : 32|3@1+ (1.0,0.0) [0.0|7] ""  Kombi,Kombi_LB,Kombi_PAG
 SG_ TSK_Einheit_vMax_FahrerInfo : 35|1@1+ (1.0,0.0) [0.0|1] ""  Kombi,Kombi_LB,Kombi_PAG
 SG_ TSK_Status_vMax_FahrerInfo : 36|2@1+ (1.0,0.0) [0.0|3] ""  Kombi,Kombi_LB,Kombi_PAG
 SG_ MO_Red_Fahrleistung : 38|3@1+ (1.0,0.0) [0.0|7] ""  Kombi,Kombi_LB,Kombi_PAG
 SG_ MO_Oel_Temp_Radsatz_Warn : 46|1@1+ (1.0,0.0) [0.0|1] ""  Kombi_PAG
 SG_ MO_Anz_Kuehlerluefter : 47|3@1+ (1.0,0.0) [0.0|7] ""  Vector__XXX
 SG_ MO_im_Leerlauf : 50|1@1+ (1.0,0.0) [0.0|1] ""  Kombi,Kombi_PAG
 SG_ WIV_Enable_Oeldr_Motor : 51|1@1+ (1.0,0.0) [0.0|1] ""  Kombi,Kombi_PAG
 SG_ MO_OelMessung_Dauer : 52|4@1+ (15,15) [15|225] "Unit_Secon"  Kombi,Kombi_PAG
 SG_ TSK_vMax_FahrerInfo : 56|8@1+ (1,15) [16|270] ""  Kombi,Kombi_LB,Kombi_PAG

BO_ 2589283599 Motor_62: 8 Gateway
 SG_ MO_TME_KL_Anf_LB : 5|7@1+ (1,0) [0|100] "Unit_PerCent"  Vector__XXX
 SG_ MO_Kilometerstand_Wakeup : 12|20@1+ (1,0) [0|1048573] "Unit_KiloMeter"  Kombi_LB
 SG_ MO_Nachlaufzeit_Kuehlerluefter_2 : 32|6@1+ (15,0) [0|945] "Unit_Secon"  Vector__XXX
 SG_ MO_Status_KL : 38|3@1+ (1.0,0.0) [0.0|7] ""  Vector__XXX
 SG_ MO_Eboost_LB_LVLavailable : 41|2@1+ (1.0,0.0) [0.0|3] ""  Kombi_LB
 SG_ MO_Eboost_LB_possible : 43|1@1+ (1.0,0.0) [0.0|1] ""  Kombi_LB
 SG_ MO_Eboost_LB_active : 44|1@1+ (1.0,0.0) [0.0|1] ""  Kombi_LB
 SG_ MO_Eboost_LB_available : 45|1@1+ (1.0,0.0) [0.0|1] ""  Kombi_LB
 SG_ MO_Eboost_LB_driveraction : 46|2@1+ (1.0,0.0) [0.0|3] ""  Kombi_LB
 SG_ MO_Eboost_LB_failure : 48|1@1+ (1.0,0.0) [0.0|1] ""  Kombi_LB
 SG_ MO_Eboost_LB_LVLselected : 49|2@1+ (1.0,0.0) [0.0|3] ""  Kombi_LB
 SG_ MO_CatHeatBar_LB : 51|7@1+ (1,0) [0|100] "Unit_PerCent"  Kombi_LB

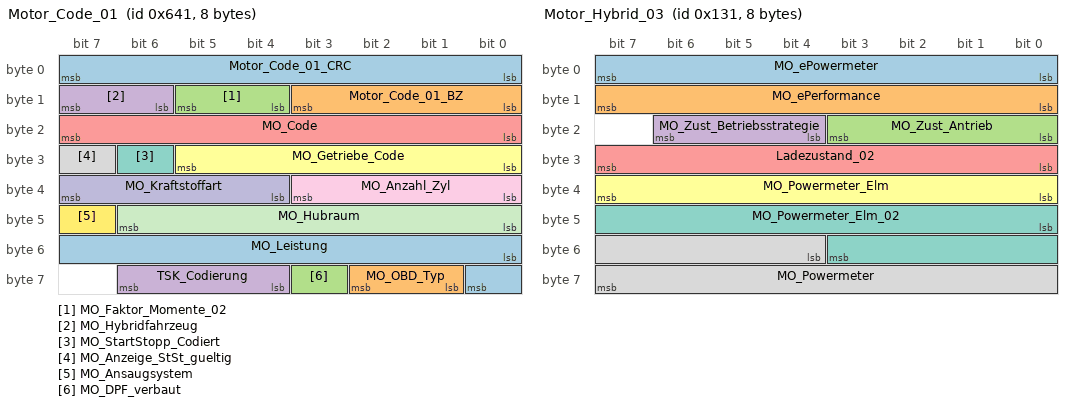
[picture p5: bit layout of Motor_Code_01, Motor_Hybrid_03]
BO_ 1601 Motor_Code_01: 8 Gateway
 SG_ Motor_Code_01_CRC : 0|8@1+ (1,0) [0|255] ""  Vector__XXX
 SG_ Motor_Code_01_BZ : 8|4@1+ (1,0) [0|15] ""  Vector__XXX
 SG_ MO_Faktor_Momente_02 : 12|2@1+ (1,0) [1|3] "Unit_NewtoMeter"  Vector__XXX
 SG_ MO_Hybridfahrzeug : 14|2@1+ (1.0,0.0) [0.0|3] ""  Kombi,Kombi_LB
 SG_ MO_Code : 16|8@1+ (1,0) [0|255] ""  Vector__XXX
 SG_ MO_Getriebe_Code : 24|6@1+ (1.0,0.0) [0.0|63] ""  Vector__XXX
 SG_ MO_StartStopp_Codiert : 30|1@1+ (1.0,0.0) [0.0|1] ""  Kombi,Kombi_LB,Kombi_PAG
 SG_ MO_Anzeige_StSt_gueltig : 31|1@1+ (1.0,0.0) [0.0|1] ""  Kombi,Kombi_LB,Kombi_PAG
 SG_ MO_Anzahl_Zyl : 32|4@1+ (1.0,0.0) [0.0|15] ""  Vector__XXX
 SG_ MO_Kraftstoffart : 36|4@1+ (1.0,0.0) [0.0|15] ""  Kombi,Kombi_LB,Kombi_PAG
 SG_ MO_Hubraum : 40|7@1+ (0.1,0) [0.0|12.7] "Unit_Liter"  Vector__XXX
 SG_ MO_Ansaugsystem : 47|1@1+ (1.0,0.0) [0.0|1] ""  Vector__XXX
 SG_ MO_Leistung : 48|9@1+ (1,0) [0|511] "Unit_KiloWatt"  Vector__XXX
 SG_ MO_OBD_Typ : 57|2@1+ (1.0,0.0) [0.0|3] ""  Vector__XXX
 SG_ MO_DPF_verbaut : 59|1@1+ (1.0,0.0) [0.0|1] ""  Vector__XXX
 SG_ TSK_Codierung : 60|3@1+ (1.0,0.0) [0.0|7] ""  Vector__XXX

BO_ 813 Motor_Gas_01: 8 Gateway
 SG_ MO_AnzeigeGasbetrieb : 0|4@1+ (1.0,0.0) [0.0|15] ""  Kombi
 SG_ MO_akt_Betrieb : 4|1@1+ (1.0,0.0) [0.0|1] ""  Kombi,Kombi_LB
 SG_ MO_Erdgasqualitaet : 5|3@1+ (1.0,0.0) [0.0|7] ""  Kombi,Kombi_LB
 SG_ MO_Verbrauchsaequivalent : 8|8@1+ (0.008,0) [0.008|2.000] "Unit_None"  Kombi,Kombi_LB
 SG_ MO_CNG_LPG M  : 16|1@1+ (1.0,0.0) [0.0|1] ""  Kombi
 SG_ MO_Fuellstand_LPG m1  : 21|10@1+ (0.125,0) [0.000|127.625] "Unit_Liter"  Kombi
 SG_ MO_CNG_Tankstopp m0  : 31|1@1+ (1.0,0.0) [0.0|1] ""  Kombi
 SG_ MO_LPG_Tankstopp m1  : 31|1@1+ (1.0,0.0) [0.0|1] ""  Kombi
 SG_ MO_Tankmasse_CNG m0  : 32|8@1+ (0.25,0) [0.25|63.50] "Unit_KiloGram"  Kombi
 SG_ MO_Tankvolumen_LPG m1  : 32|8@1+ (0.5,0) [0.5|127.0] "Unit_Liter"  Kombi
 SG_ MO_Fuellungsgrad_CNG m0  : 40|8@1+ (0.4,0) [0.0|101.2] "Unit_PerCent"  Kombi
 SG_ MO_Fuellungsgrad_LPG m1  : 40|8@1+ (0.4,0) [0.0|101.2] "Unit_PerCent"  Kombi
 SG_ MO_CNG_Ueberlauf m0  : 48|1@1+ (1.0,0.0) [0.0|1] ""  Kombi
 SG_ MO_LPG_Ueberlauf m1  : 48|1@1+ (1.0,0.0) [0.0|1] ""  Kombi
 SG_ MO_Verbrauch_CNG m0  : 49|15@1+ (1,0) [0|32767] "Unit_MilliGram"  Kombi
 SG_ MO_Verbrauch_LPG m1  : 49|15@1+ (1,0) [0|32767] "Unit_MicroLiter"  Kombi

BO_ 305 Motor_Hybrid_03: 8 Gateway
 SG_ MO_ePowermeter : 0|8@1+ (0.4,-0.4) [0.0|100.8] "Unit_PerCent"  Kombi,Kombi_LB,Kombi_PAG
 SG_ MO_ePerformance : 8|8@1+ (0.4,-0.4) [0.0|100.8] "Unit_PerCent"  Kombi,Kombi_LB,Kombi_PAG
 SG_ MO_Zust_Antrieb : 16|4@1+ (1.0,0.0) [0.0|15] ""  Kombi,Kombi_LB,Kombi_PAG
 SG_ MO_Zust_Betriebsstrategie : 20|3@1+ (1.0,0.0) [0.0|7] ""  Kombi,Kombi_LB,Kombi_PAG
 SG_ Ladezustand_02 : 24|8@1+ (0.5,0) [0.0|100.0] "Unit_PerCent"  Kombi,Kombi_LB,Kombi_PAG
 SG_ MO_Powermeter_Elm : 32|8@1+ (1,-128) [-100|100] "Unit_PerCent"  Kombi,Kombi_LB,Kombi_PAG
 SG_ MO_Powermeter_Elm_02 : 40|12@1+ (0.05,-102.4) [-100.00|100.00] "Unit_PerCent"  Kombi,Kombi_LB,Kombi_PAG
 SG_ MO_Powermeter : 52|12@1+ (1,0) [0|4092] ""  HUD,Kombi,Kombi_LB,Kombi_PAG

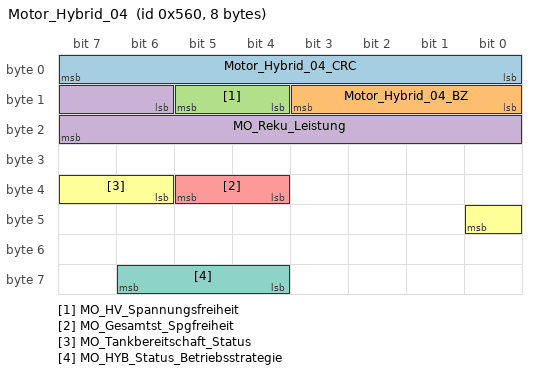
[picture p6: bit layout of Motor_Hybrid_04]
BO_ 1376 Motor_Hybrid_04: 8 Gateway
 SG_ Motor_Hybrid_04_CRC : 0|8@1+ (1,0) [0|255] ""  Vector__XXX
 SG_ Motor_Hybrid_04_BZ : 8|4@1+ (1,0) [0|15] ""  Vector__XXX
 SG_ MO_HV_Spannungsfreiheit : 12|2@1+ (1.0,0.0) [0.0|3] ""  Vector__XXX
 SG_ MO_Reku_Leistung : 14|10@1+ (10,0) [0|10230] "Unit_Watt"  Vector__XXX
 SG_ MO_Gesamtst_Spgfreiheit : 36|2@1+ (1.0,0.0) [0.0|3] ""  Vector__XXX
 SG_ MO_Tankbereitschaft_Status : 38|3@1+ (1.0,0.0) [0.0|7] ""  Kombi,Kombi_LB,Kombi_PAG
 SG_ MO_HYB_Status_Betriebsstrategie : 60|3@1+ (1.0,0.0) [0.0|7] ""  Vector__XXX

BO_TX_BU_ 1607 :Gateway,Gateway_PAG;
BO_TX_BU_ 168 :Gateway,Gateway_PAG;
BO_TX_BU_ 958 :Gateway,Gateway_PAG;
BO_TX_BU_ 1631 :Gateway,Gateway_PAG;
BO_TX_BU_ 812 :Gateway,Gateway_PAG;
BO_TX_BU_ 1648 :Gateway,Gateway_PAG;
BO_TX_BU_ 815 :Gateway,Gateway_PAG;
BO_TX_BU_ 1391 :Gateway,Gateway_PAG;
BO_TX_BU_ 967 :Gateway,Gateway_PAG;
BO_TX_BU_ 327 :Gateway,Gateway_PAG;
BO_TX_BU_ 1366 :Gateway,Gateway_PAG;
BO_TX_BU_ 283 :Gateway,Gateway_PAG;
BO_TX_BU_ 2589283475 :Gateway,Gateway_PAG;
BO_TX_BU_ 706 :Gateway,Gateway_PAG;
BO_TX_BU_ 1601 :Gateway,Gateway_PAG;
BO_TX_BU_ 813 :Gateway,Gateway_PAG;
BO_TX_BU_ 305 :Gateway,Gateway_PAG;
BO_TX_BU_ 1376 :Gateway,Gateway_PAG;
CM_ BO_ 168 "Teil 2 neue Momentenschnittstelle MLB";
CM_ BO_ 1648 "Kombischnittstelle";
CM_ BO_ 967 "MQB - vorher Motor_06 / Umbenennung wg. ID-Wechsel";
CM_ BO_ 1601 "ab MQB mit CRC-8";
CM_ BO_ 813 "AUTOSAR kompatible MLBevo Botschaft
Gesendet nur bei CNG/LPG-Motorprojekten";

CM_ SG_ 1607 MO_CO2_Faktor "dynamischer Umrechnungsfaktor von l in CO2";
CM_ SG_ 1607 MO_E85_Sensor "Information über den E85 Gehalt (%-mass.) im Ottokraftstoff";
CM_ SG_ 1607 MO_Ethanol_Spuelhinweis "Hinweis das der Fahrer beim nächsten Tanken Ethanol armen Sprit tanken soll.";
CM_ SG_ 1607 MO_ITM_Kuehlmittel_Temp "Kuehlmitteltemperatur: Ersatzkühlmitteltemperatur für Motoren mit ITM (Thermomanagement)

ACHTUNG: Ab MQB wird in diesem Signal das Anzeigeplateau durch das MSG dargestellt!";
CM_ SG_ 1607 MO_Kraftstofffilter_Wasser "Für Schlechtkraftstoffländer wird das Wasserabscheidevolumen im Dieselkraftstofffilter mit einem  Wassersensor überwacht. Ist das Volumen erschöpft, erfolgt im Kombi eine entsprechende Anzeige.";
CM_ SG_ 1607 MO_MKB_01 "Motorkennbuchstabe 1";
CM_ SG_ 1607 MO_MKB_02 "Motorkennbuchstabe 2";
CM_ SG_ 1607 MO_MKB_03 "Motorkennbuchstabe 3";
CM_ SG_ 1607 MO_MKB_04 "Motorkennbuchstabe 4";
CM_ SG_ 1607 MO_MKB_MUX "Die vier Motorkennbuchstaben werden gemultiplext in MO_MKB übertragen. Das Signal MO_MKB_MUX stellt das Steuersignal für diesen Multiplexer dar.";
CM_ SG_ 1607 SCR_Akustik "Ansteuerung von Summer/Gong bei Aktivieren der SCR-Warnungen.
Bedienung des Signals nur bei Dieseln mit SCR-System. Andere senden Initwert.";
CM_ SG_ 1607 SCR_Anz_Motorstarts "Anzahl noch möglicher Motorstarts, wenn Reichweite = 0 ist
0..13 = Anzeige 'x mögliche Restarts'
14 = Eingeschränkte Fahrfunktion (z. Zt. Audi)
15 = keine Einschränkung (Anzeige Reichweite)
Bedienung des Signals nur bei Dieseln mit SCR-System.";
CM_ SG_ 1607 SCR_Inducement_Strategie "Art des Motor-Inducement-Konzepts. Abhängig von diesem Signal sind die Warntexte zwischen 'Kein Motorstart (in...km)' und 'eingeschränkte Fahrbarkeit (in ...km)' auszuwählen.";
CM_ SG_ 1607 SCR_Reichweite "Gesamtreichweite in km der aktuellen SCR-Tankfüllung, sofern die Reichweite kleiner 2400 km ist. Bei einer Reichweite größer 2400 km wird grundsätzlich der Initwert (32767) übertragen. Bedienung des Signals nur bei Dieseln mit SCR-System.";
CM_ SG_ 1607 SCR_Systemfehler "Ansteuerung Anzeige für SCR-Systemfehler";
CM_ SG_ 1607 SCR_Text "Warntext (z. B. in Kombination mit SCR Warnstufe und SCR-Systemfehler).
Bedienung des Signals nur bei Dieseln mit SCR-System. Andere senden Initwert.";
CM_ SG_ 1607 SCR_verbaut "Die SCR-Signale deren Initwert ungleich 0 sind, werden nur dann ausgewertet, wenn SCR_verbaut == 1 den Verbau des SCR Systems zeigt.";
CM_ SG_ 1607 SCR_Warnstufe_1 "Ansteuerung der SCR Füllstandswarnlampe (Stufe 1) (gelbe Lampe) SCR_Warnstufe_1 (Prio 2).
Bedienung des Signals nur bei Dieseln mit SCR-System. Andere senden Initwert.";
CM_ SG_ 1607 SCR_Warnstufe_2 "Ansteuerung der SCR Füllstandswarnlampe (Stufe 2) (Blinkbit für gelbe Lampe oder rote Lampe) SCR_Warnstufe_2 (Prio 1).
Bedienung des Signals nur bei Dieseln mit SCR-System. Andere senden Initwert.";

CM_ SG_ 168 MO_Drehzahl_01 "Im Fehlerfall wird die Motordrehzahl über die Nockenwellendrehzahl als Ersatzgrösse ausgegeben

Bei Parallelhybrid: Getriebeeingangsdrehzahl (=E-Maschinen Drehzahl)

Hinweis: 
Ehemaliger Fehlerwert 0xFFFF wird senderseitig nicht unterstützt. 
Diesen";
CM_ SG_ 168 MO_Mom_Begr_dyn "Einheitenloser Wert! Faktor in MO_Faktor_Momente (CAN V6.x) bzw. MO_Faktor_Momente_02 (CAN V7.x/V8.x) in Motor_Code_01 beachten!

Bei aktueller Drehzahl kurzfristig (ca. 100..200 ms) max. mögliches Moment (Summe aus Verbrennungsmotor und E-Motor), wird ";
CM_ SG_ 168 MO_Mom_Begr_stat "Einheitenloser Wert! Faktor in MO_Faktor_Momente (CAN V6.x) bzw. MO_Faktor_Momente_02 (CAN V7.x) in Motor_Code_01 beachten!

Bei aktueller Drehzahl quasistationär (nach ca. 3..5 s) max. mögliches Moment (Summe aus max. Moment des Verbrennungsmotors aus ";
CM_ SG_ 168 MO_Mom_neg_verfuegbar "Einheitenloser Wert! Faktor in MO_Faktor_Momente (CAN V6.x) bzw. MO_Faktor_Momente_02 (CAN V7.x) in Motor_Code_01 beachten!

Bei aktueller Drehzahl im nächsten Task (bei CAN-Übertragung z.B. 10ms) tatsächlich verfügbares negatives Moment (Summe aus Verl";
CM_ SG_ 168 MO_Momentenintegral_02 "100  %  entspricht volle Verfügbarkeit aktuell vorhanden. 0 % entspricht Integral bis Limit gefüllt, erhöhender Eingriff kann aktuell nicht berücksichtigt werden oder aufgrund eines Fehlers nicht verfügbar
";
CM_ SG_ 168 MO_QBit_Drehzahl_01 "AUDI D4: Zykluszeit: 10ms (siehe Zykluszeit schnell/Cycletime Fast)

Achtung:
Reduktion der Zykluszeit Motor_03 auf 10ms geplant.
Projektabhängig soll künftig mit 10ms gesendet werden.
Empfänger die in weiteren Konzern-Projekten eingesetzt werden müs";
CM_ SG_ 168 Motor_12_BZ "Botschaft asynchron geroutet. Zählerwert kann springen.";
CM_ SG_ 168 Motor_12_CRC "Für MLB:
'Berechnung siehe Lastenheft 'Kommunikationsabsicherung für FlexRay und CAN''

Ab MQB und MLBevo:
'Berechnung siehe Lastenheft 'End-to-End Kommunikationsabsicherung'

Endwerte siehe Begleitdokument 'S-PDU Kennungsfolgen'";

CM_ SG_ 958 MO_Aussp_Anlass "Das Signal zeigt an, ob die Wiederholstartsperre aktiv ist. D. h. eine Ansteuerung des Anlassers wird auch bei erfüllten Startvoraussetzungen (HS: Interlock betätigt bzw. AT: P/N eingelegt und Bremse betätigt) nicht erfolgen.";
CM_ SG_ 958 MO_BKV_Unterdruckwarnung "Über die Unterdruckwarnung signalisiert das MSG dem ESP, dass kein ausreichender Unterdruck für den BKV zur Verfügung gestellt werden kann.";
CM_ SG_ 958 MO_BLS "Ungefiltertes Rohsignal des Bremslichtschalters, nur wenn HW-Eingang bestückt und ausgewertet wird. Bei Motoren ohne genutzten HW-Eingang wird kein Ersatzwert (bspw. SW-Signal über CAN) ausgegeben!
Bei AUDI muss das Signal wg. Bremslichtfunktion immer be";
CM_ SG_ 958 MO_BMS_NV_Anf_stuetzen "Garantierte Unterstützung des Zusatzspeichers ist erforderlich. Zusatzspeicher muss an das Versorgungsnezt angebunden werden. ";
CM_ SG_ 958 MO_EKlKomLeiRed "Anforderung an die Klimasteuerung, die Leistungsaufnahme des E-Kompressors bei schlechtem SOC und in bestimmten Fahrsituationen zu begrenzen. (Das bereits bestehende Signal 'Klimakompressor aus' als stets umzusetzende Anforderung bleibt unverändert besteh";
CM_ SG_ 958 MO_Ext_E_Fahrt_aktiv "Funktionsrückmeldung zum erw. E-Fahr-Betrieb über Lampe/LED im E-Mode-Taster";
CM_ SG_ 958 MO_Fahrer_bremst "Redundante Bremsinformation vom Motor.

MLB:
AUDI D4: Zykluszeit: 10ms (siehe Zykluszeit schnell/Cycletime Fast)
Im AUDI B8 wird in diesem Bit der Wert der ESP-CAN-Information 'ESP_Fahrer_bremst' ausgegeben.

Achtung:
Reduktion der Zykluszeit Motor";
CM_ SG_ 958 MO_FMAus_aktiv "Das Signal gibt Rückmeldung ob Freilauf Motor aus aktiv ist. Beleibt auch 0km/h (unterhalb der StartStopp Schwelle) weiterhin aktiv.";
CM_ SG_ 958 MO_FMAus_Startvariante "Startvariante beim Motorstart aus der Freilauf-Motor-AUS Phase";
CM_ SG_ 958 MO_Freig_Anlass "Bit wird gesetzt, wenn der Motor beim Automatikstart gestartet werden darf (Motorstillstand, Emissionsmaßnahmen sind erfüllt).";
CM_ SG_ 958 MO_Freig_Reku "Empfehlung des Motor-SG's zur Spannungsabsenkung/-anhebung für den Rekuperationsbetrieb";
CM_ SG_ 958 MO_Freigabe_Segeln "Freigabebit des Segelbetriebs im Getriebe. Bedingt durch bestimmte Diagnosen und Adaptionen des MSGs, die nur im Schub möglich sind, darf nicht jede Schubphase für einen Segelbetrieb genutzt werden. Eine Freigabe bleibt auch außerhalb einer Schubphase bes";
CM_ SG_ 958 MO_Gangposition "MLB:
Stellung des Wählhebels in der Schaltgasse des Handschaltgetriebes.
MLBevo: 
Ausweitung der Bedienung auch auf Automatikgetriebe;
Routing des Signals GE_Fahrstufe: 
1. Position_R (dez. 6) auf MO_Gangposition: Gang_R (dez. 13) wegen Entfall Signa";
CM_ SG_ 958 MO_Handshake_STH "Es gilt: Signalspec MO_Handshake v1.0

Handshake zwischen MSG und STH. Wenn das MSG die EKP aufgrund einer STH-Anforderung ansteuert und kein Fehlereintrag bzgl. EKP/KPE/NDR vorliegt, wird das Bit gesetzt.";
CM_ SG_ 958 MO_HYB_Fahrbereitschaft "Signal steuert u.a. in der Lenkhilfe zusammen mit weiteren Informationen den Modewechsel in den 'Drivemode'
Grüne Anzeige im Kombiinstrument zur Signalisierung der Bereitschaft des Hybridsystems.";
CM_ SG_ 958 MO_HYB_VM_aktiv "0 = VMotor wird nicht aktiv gehalten (nVM < n_min und keine LL-Regelung aktiv)
1 = VMotor aktiv (ab der ersten Einspritzung; gilt auch für Schubbetrieb, wenn VMotor spätestens durch LLRegelung befeuert würde)
Verwendet zur Bestimmung des Ist-Zustandes";
CM_ SG_ 958 MO_Interlock "Das Motorsteuergerät gibt die Information aus, ab wann der Kupplungsschalter durch das Motorsteuergerät als getreten gesehen wird.
Bei Systemen für Start Stopp muss das Interlocksignal für einen Start durch das MSG generiert werden, sobald der Schalthebe";
CM_ SG_ 958 MO_Kickdown "Es gilt: Signalspec MO_Kickdown v1.0";
CM_ SG_ 958 MO_Kl_50 "Klemme 50: Startausführung durch Ritzelstarter

MLB: nicht von allen Motoren gesendet
MQB/MLBevo: gesendet von allen Motoren";
CM_ SG_ 958 MO_Kl_75 "Klemme X
";
CM_ SG_ 958 MO_Klima_Eingr "Eingriffe des Motor bei der Klima";
CM_ SG_ 958 MO_KomFehler_ESP "Anzeige Kommunikationsfehler bei Empfang vom ESP";
CM_ SG_ 958 MO_Konsistenz_Bremsped "MLB:

AUDI D4: Zykluszeit: 10ms (siehe Zykluszeit schnell/Cycletime Fast)
Siehe 'Funktionsspezifikation Bremslichtinfo B8'

Achtung:
Reduktion der Zykluszeit Motor_03 auf 10ms geplant.
Projektabhängig soll künftig mit 10ms gesendet werden.
Empfäng";
CM_ SG_ 958 MO_Kuppl_schalter "MLB:
Das Motorsteuergerät gibt die Information aus, ab wann der Kupplungsschalter durch das Motorsteuergerät als getreten gesehen wird
0x0: Schalter sagt betätigt (Ausgekuppelt)
0x1: Schalter sagt nicht betätigt (Eingekuppelt)

MQB:
Nur Handschalter";
CM_ SG_ 958 MO_Motor_laeuft "Das Motorsteuergerät gibt die Information aus, ab wann der Motor verbrennungsbedingt autark läuft und durch zuschaltbare Nebenaggregate mechanisch belastbar ist (z.B. durch Generator, Klimakompressor, etc.).

Die 'Motor läuft' Information wird ausgegebe";
CM_ SG_ 958 MO_PTC_Status "Status-Rückmeldung vom MSG zum aktuellen PTC-Status (stufiges PTC, Relais am MSG). Bei Ansteuerung eines stufigen PTC durch ein anderes SG beschreibt das Signal die vom MSG freigegebene PTC-Stufe.";
CM_ SG_ 958 MO_QBit_Fahrer_bremst "MLB:
AUDI D4: Zykluszeit: 10ms (siehe Zykluszeit schnell/Cycletime Fast)

Achtung:
Reduktion der Zykluszeit Motor_03 auf 10ms geplant.
Projektabhängig soll künftig mit 10ms gesendet werden.
Empfänger die in weiteren Konzern-Projekten eingesetzt werd";
CM_ SG_ 958 MO_QBit_Gangposition "Qualitätsbit zum Signal MO_Gangposition";
CM_ SG_ 958 MO_QBit_KL_75 "Q - Bit für das KL 75 Signal zur Vermeidung der fehlerhaften Erkennung von Motorstarts. 
Wird auf 1 gesetzt, solange das Motorsteuergerät KL15 = AUS erkannt hat.";
CM_ SG_ 958 MO_Remotestart_Betrieb "Das MSG ist für den Remotestart-Betrieb bereit. Nach Empfang der Motorstartanforderung für RSt-Betrieb durch BCM wird der Fahrzeugmotor gestartet und solange der Motor läuft, bleibt dieses Bit aktiv. Dieses Signal ist nur zur Verwendung durch das BCM zur ";
CM_ SG_ 958 MO_Remotestart_moeglich "Wenn Bit gesetzt, würde das MSG bei entsprechender Anforderung durch das BCM den Remotestartbetrieb einleiten, d.h. das MSG ist remotestartfähig und es liegen aktuell keine relevanten Fehler oder andere Abbruchgründe vor.";
CM_ SG_ 958 MO_Signalquelle_Gangposition "Signalquelle des Signals MO_Gangposition
0: Signalquelle Gangpositionssensor
1: Signalquelle Modellwert (v/n)";
CM_ SG_ 958 MO_StartStopp_Fahrerwunsch "Fahreraktivität Start/Stop";
CM_ SG_ 958 MO_StartStopp_Motorstopp "Motor-Stopp durch Start/Stopp-Koordinator
HYBRID:
Wenn MO_Hybridfahrzeug = 1 gilt:
Verbrennungsmotor durch Hybrid-Koordinator im MSG ausgeschaltet. 
Die definierten Start/Stopp-Signale beziehen sich nur auf den Verbrennungsmotor!";
CM_ SG_ 958 MO_StartStopp_Status "Aktivitätsstatus Start/Stopp-Koordinator
HYBRID:
Wenn MO_Hybridfahrzeug = 1 gilt:
Signal bezieht sich nur auf den Verbrennungsmotor, nicht auf den Hybridantrieb
";
CM_ SG_ 958 MO_StartStopp_Wiederstart "Motorwiederstart durch Start/Stopp-Koordinator
HYBRID:
Wenn MO_Hybridfahrzeug =1 gilt:
Warnung vor Spannungseinbruch beim Zustart des Verbrennungsmotors. 
-nicht relevant, da derzeit kein Start über 12V-Starter geplant-
Dieses Signal wird nur vom Hyb";
CM_ SG_ 958 MO_StartVorauss_erfuellt "Dient der Fallunterscheidung bei ZAT-Betätigung im Zustand 'KL15 ein' (bei nicht gesetztem Signal folgt KL15 aus, bei gesetztem Signal folgt setzen KL50-Anf.)

0: Signal nicht bedient 
1: Voraussetzungen zur Antriebsstrangaktivierung / Startvoraussetzu";
CM_ SG_ 958 MO_Text_Geschw_red "Anforderung an das Kombi die Textmeldung 'Geschwindigkeitsreduzierung' anzuzeigen";
CM_ SG_ 958 MO_Zylinderabschaltung "Status Zylinderabschaltung Motor";
CM_ SG_ 958 Motor_14_CRC "Ab MQB und MLBevo:
'Berechnung siehe Lastenheft 'End-to-End Kommunikationsabsicherung'

Endwerte siehe Begleitdokument 'S-PDU Kennungsfolgen'";

CM_ SG_ 1631 MO_Anzeige_Kaltleuchte "Fahrleistungseinschänkungen aus dem Motor-Abgasmanagement zur Anzeige als Lampe ohne Hinweistext im Kombiinstrument";
CM_ SG_ 1631 MO_DPF_reg "Regeneration Diesel-Partikel-Filter";
CM_ SG_ 1631 MO_Energieinhalt_BMS "Restenergieinhalt der Traktionsbatterie, beeinflusst durch Fahrstrategie und weiteren Faktoren der Antriebssteuerung.";
CM_ SG_ 1631 MO_Heizstrom_EKAT "Aktuelle Gesamtstromaufnahme des E-Katalysators";
CM_ SG_ 1631 MO_Heizstrom_SCR "Aktuelle Gesamtstromaufnahme der Tank-, Fördermodul- und Leitungsheizung des SCR-Systems";
CM_ SG_ 1631 MO_P_Generator_ungefiltert_Anf "Bei Empfang der Anforderung soll der Sender BEM_P_Generator ungefiltert befüllen.";
CM_ SG_ 1631 MO_SpannungsAnf_02 "Forderung des Motor-SG's zur Spannungsanhebung";
CM_ SG_ 1631 TSK_Fahrzeugmasse_02 "Neue Definition ab D4
Fahrzeugmasse in kg. Das Signal dient der Anpassung der Sollbeschleunigung vom ACC


";
CM_ SG_ 1631 TSK_Grundmasse "Fahrzeuggrundmasse in kg. Das Signal dient der Anpassung der Sollbeschleunigung vom ACC

Hinweis: Ehemaliger Fehlerwert 0x7F wird senderseitig nicht unterstützt. Diesen Wert aus Kompatibilitätsgründen nicht neu belegen!";
CM_ SG_ 1631 TSK_Steigung_02 "Steigung in % Berg. Das Signal dient der Anpassung der Sollbeschleunigung vom ACC

Positive Werte > bergauf; 
Negative Werte < bergab

Fehler: Die Steigung aufgrund eines Fehlers (mit KD-Fehlereintrag) nicht mehr berechnet werden";

CM_ SG_ 812 MO_BZS_Charisma_FahrPr "Rückmeldung des aktuellen Charisma-Fahrprogramms der MSG Betriebsstrategie

MLBevo: Aktuelles Fahrprogramm des Charisma-Teilnehmers (siehe Systemlastenheft Drive Select)
MQB: Istwert der Kennlinie (siehe Systemlastenheft MQB FPA)";
CM_ SG_ 812 MO_BZS_Charisma_Status "Charisma Systemstatus des Charisma-Teilnehmers MSG (Betriebszustände)

Wert 0x3 ist nur für Fahrzeuge ab MQB relevant";
CM_ SG_ 812 MO_Charisma_FahrPr "MLBevo: Aktuelles Fahrprogramm des Charisma-Teilnehmers (siehe Systemlastenheft Drive Select)
MQB: Istwert der Kennlinie (siehe Systemlastenheft MQB FPA)";
CM_ SG_ 812 MO_Charisma_Status "Charisma Systemstatus des Charisma-Teilnehmers

Wert 0x3 ist nur für Fahrzeuge ab MQB relevant";
CM_ SG_ 812 MO_Drehzahlbeeinflussung "Faktor zur Anhebung der Fahrdrehzahl im Warmlauf";
CM_ SG_ 812 MO_Luftpfad_aktiv "Getriebeeingriff wird zusätzlich zum Zündungspfad auch über den Luftpfad umgesetzt, kommt zu MLB neu in die PL48-Getriebe";
CM_ SG_ 812 MO_MAX_Wunschdrehzahl "maximale Motorwunschdrehzahl, die vom Getriebe nicht überschritten werden darf

Signal darf GE_Synchro_Wunschdrehzahl nicht spiegeln";
CM_ SG_ 812 MO_MIN_Wunschdrehzahl "minimale Motorwunschdrehzahl aufgrund Regeneration, die vom Getriebe nicht unterschritten werden darf

Hinweis: 
Ehemaliger Fehlerwert 0xFF wird senderseitig nicht unterstützt. 
Diesen Wert aus Kompatibilitätsgründen nicht neu belegen!";
CM_ SG_ 812 MO_NGS_Position "Messwert des Neutralgangsensors
(nur Handschalter)";
CM_ SG_ 812 MO_NGS_Status "Status des Signals MO_NGS_Position. Das MSG prüft die Plausibilität nur hinsichtlich sicher geöffnetem Triebstrang.";
CM_ SG_ 812 MO_Prio_MAX_Wunschdrehzahl "Prioritätsbit der Motorwunschdrehzahl  als MAX";
CM_ SG_ 812 MO_Prio_MIN_Wunschdrehzahl "Prioritätsbit der Motorwunschdrehzahl als MIN";
CM_ SG_ 812 MO_Rampenzeit_Generator_Anf "Das Motorsteuergerät kann eine Load-Response-Zeit des Generators vom Niedervoltenergiemanagement (NVEM) anfordern. Die Load-Response-Zeit wird vom NVEM umgesetzt, wenn dies bordnetzverträglich möglich ist.";
CM_ SG_ 812 MO_Sperrung_FahrPr_BZS "Sperrung einzelner Betriebszustände bzgl. Kommunikation zwischen Motor-SG und Charisma-SG (Gateway)";
CM_ SG_ 812 MO_StSt_Charisma_FahrPr "MLBevo: Aktuelles Fahrprogramm des Charisma-Teilnehmers (siehe Systemlastenheft Drive Select)
MQB: Istwert der Kennlinie (siehe Systemlastenheft MQB FPA)";
CM_ SG_ 812 MO_StSt_Charisma_Status "Charisma Systemstatus des Charisma-Teilnehmers

Wert 0x3 ist nur für Fahrzeuge ab MQB relevant";
CM_ SG_ 812 MO_v_Begrenz_Aktivierbar "Fehlerbit wird vom Motor-SG gesetzt, wenn dieses nicht in dieGeschwindigkeits-begrenzung gehen kann, ein Fehler während der v-Begrenzung auftritt oder v > v_Begrenzung - v_Delta";
CM_ SG_ 812 MO_v_Begrenzung_Niveau "Zeigt an, ob eine v-Begrenzung aufgrund Anforderung der Niveauregelung  im MSG aktiv ist oder nicht (Signal für Niveau zum Steuern der Kombianzeige).";

CM_ SG_ 1648 MO1_Freigabe_Info_WFS "WFS-Freigabeinformation";
CM_ SG_ 1648 MO1_Freigabe_Verfallsinfo_WFS "WFS-Freigabeverfallsinformation";
CM_ SG_ 1648 MO1_Sperr_Info_WFS "WFS-Sperrinformation";
CM_ SG_ 1648 MO_Abstellzeit "Abstelldauer nach letztem KL15 aus

Hinweis: 
Ehemaliger Fehlerwert 0xFF wird senderseitig nicht unterstützt. 
Diesen Wert aus Kompatibilitätsgründen nicht neu belegen!";
CM_ SG_ 1648 MO_Abstellzeit_Status "Statusinformation zur Abstellzeit
0: Die dem Status zugeordnete Variable konnte noch nicht berechnet werden. 
1: Die dem Status zugehörige Variable wurde korrekt berechnet. 
2: Der Wert der zugehörigen Variablen ist nur ein Minimalwert. 
3: Der Wert d";
CM_ SG_ 1648 MO_ANC_Kennfeld_Anf "Anforderung ANC Kennfeldumschaltung";
CM_ SG_ 1648 MO_Anzahl_Abgesch_Zyl "Gibt die Anzahl der abgeschalteten Zylinder an. In Übergangszuständen wird der Zielbetriebszustand angezeigt.";
CM_ SG_ 1648 MO_Bremslicht_Reku "Bremslicht (ggf. bei Rekuperation durch E-Motor) wird angesteuert";
CM_ SG_ 1648 MO_Drehzahl_Warnung "Warnhinweis zum Kombi im Fall einer fehlerbehafteten Drehzahlbegrenzung";
CM_ SG_ 1648 MO_EPCL "Die Anforderung der EPC-Lampe vom MSG ans Kombi soll durch das Bus-Signal MO_EPCL gemäß folgender Logik erfolgen:
MO_EPCL = 0 dez -> EPC Lampe aus, kein Text
MO_EPCL = 1 dez -> gelbe EPC-Symbolik, Text „Antrieb: Störung! Bitte Service aufsuchen“
MO_EPC";
CM_ SG_ 1648 MO_Ethanol_BS_Texte "Ethanol Brennstoff-Texte im Kombi

0 = kein Text
1 = E85 Warm_Up
2 = FlexFuel Warnung 3.Stufe (Too cold for ethanol)
3 = Warmfahrempfehlung MQB / FlexFuel Warnung 1.Stufe (Refuel with gasoline)
4 = FlexFuel Warnung 2. Stufe (Refuel with gasoline)
5";
CM_ SG_ 1648 MO_Fahrzeugtyp "Unterscheidet die Fahrzeugtypen bzgl. der Antriebsart";
CM_ SG_ 1648 MO_Fehler_Zylabsch "Fehlerstatus der Funktion Zylinderabschaltung ";
CM_ SG_ 1648 MO_Hybrid_StartStopp_LED "Ansteuerung der Funktions-LED der Hybrid Taste bzw. Start/Stop Deaktivierungstaste.
Der Start/Stopp-Master (derzeit im MSG) (oder ein künftiger Hybrid-Master) soll die Ansteuerung senden.";
CM_ SG_ 1648 MO_max_Ladedruck "maximal möglicher Ladedruck (zur Anpassung des Anzeigebereichs bei absoluter Ladedruckanzeige)";
CM_ SG_ 1648 MO_NMAX_Schaltanzeige "Maximaldrehzahl für Schaltanzeige";
CM_ SG_ 1648 MO_obere_Drehzahlgrenze "obere Drehzahlgrenze des Motors";
CM_ SG_ 1648 MO_StartStopp_PopUp "Das Signal zeigt an, ob der StSt-Status mittels Deaktivierungstaster geändert wurde. Ein Wechsel auf die Werte 01 oder 10 löst im Kombi ein entsprechendes PopUp aus. Bei einem Statuswechsel durch andere Signalquellen (z.B. Charisma, fehlerbedingte Abschal";
CM_ SG_ 1648 MO_Zylabsch_Texte "Zylinderabschaltung mode in Kombi, fuer Zylinderabschaltung";
CM_ SG_ 1648 MO_Zylabsch_Texte_02 "ZAS-Anzeige für den Fahrer im Kombi
0: kein ZAS (generell keinerlei ZAS-Anzeigen)  (Init für nicht ZAS-Motor)
1: ZAS im Vollmotorbetrieb  (Init für ZAS-Motor)
2: ZAS im Abschaltbetrieb: 1 Zyl aktiv
3: ZAS im Abschaltbetrieb: 2 Zyl aktiv
4: ZAS im Abs";

CM_ SG_ 815 MO_Antriebsstrang_Warnung_HS "Status der Fehlerlampen-Ansteuerung und Textausgabe für Fehlerspeichereinträge aus der Kupplungsschutz-Funktion für Handschaltgetriebe.";
CM_ SG_ 815 MO_Anzeige_Betriebsmodus "Info an das Kombi zur Anzeige verschiedener Betriebsmodi";
CM_ SG_ 815 MO_Anzeige_Fahrbereitschaft "Signalisiert dauerhaft an das Kombi, ob die Fahrbereitschaft vorhanden ist (Drehzahlmesser auf READY)";
CM_ SG_ 815 MO_Anzeige_Rekuperation "Signal steht im Kontext zu MO_Anzeige_Verbrauch und wird für die Anzeige des Reku-Bereiches im grafischen Momentanverbrauch verwendet";
CM_ SG_ 815 MO_Anzeige_Verbrauch_oE "Anzeige Verbrauchssignal fürs Kombi. Im Bezug auf Verbrennerbeteiligung. Das Signal ist einheitenlos. Die zugehörige Einheit wird in MO_Anzeige_Verbr_Einheit übertragen.";
CM_ SG_ 815 MO_Boost_aktiv "Anzeige im Kombi ob Boost aktiv ist.
Die Anzeige wird zusätzlich über das Signal MO_Boost_verfuegbar gesteuert.
";
CM_ SG_ 815 MO_Boost_verfuegbar "Anzeige des aktuell verfügbaren Boostpotentials im Kombiinstrument.";
CM_ SG_ 815 MO_Overboost "Nur Turbo. Anzeige eines Overboostpfeils im Kombi während Overboostzustand der Ladedruckregelung.";
CM_ SG_ 815 PEA_Abschalttexte "Das Signal dient dem Anzeigen von Abschalttexten, wenn PEA nicht verfügbar ist";
CM_ SG_ 815 PEA_Ereignisanzeige "Das Signal dient der Anzeige des Hinweisgrundes";
CM_ SG_ 815 PEA_Ereignisanzeige_temporaer "Signal dient zur Steuerung einer TPA Anzeige im Kombi";
CM_ SG_ 815 PEA_Fortschrittsanzeige "Ablaufbalken für PEA-Hinweise";
CM_ SG_ 815 PEA_Hinweis "Aufforderung für Fahrerhandlung durch PEA";
CM_ SG_ 815 PEA_Zielgeschw "Das Signal dient der Anzeige einer Geschwindigkeit eines Geschwindigkeitsereignisses für PEA";
CM_ SG_ 815 PEA_Zielgeschw_Einheit "Einheit der anzuzeigenden Zielgeschwindigkeit für PEA (Prädiktiver Effizienz Assistent)";

CM_ SG_ 1391 MO_Anzeige_Aufheizfortschritt "Anzeigesignal des Aufheizfortschritts des Abgastrakts im Rahmen der Kaltabfahrbegrenzung";
CM_ SG_ 1391 MO_Anzeige_Drehmoment_Max "Signal gibt das max. verfügbare Drehmoment wieder. Bedient die Drehmomentanzeige im Kombiinstrument. ";
CM_ SG_ 1391 MO_Anzeige_Leistung_Max "Signal gibt die max. verfügbare Motorleistung wieder. Bedient die Leistungsanzeige im Kombiinstrument. ";
CM_ SG_ 1391 MO_HYB_Drehzahl_VM "für OBD freeze frame";
CM_ SG_ 1391 MO_IstLeistung_EKAT "Gesamt IST-Leistung der elektrischen Heizscheibe(n)";

CM_ SG_ 967 MO_E_Mode "Anforderung der E-Mode Statusanzeige";
CM_ SG_ 967 MO_E_Texte "Anforderung von Hinweistexten des E-Systems separat für HEV/BEV bzw. erweiterbar für PHEV";
CM_ SG_ 967 MO_E_Warnungen "Anforderung von Warnanzeigen des E-Systems separat für HEV/BEV bzw. erweiterbar für PHEV";
CM_ SG_ 967 MO_EFLEX_Lampe "Um ein Starten mit E100 zu ermöglichen, wird Kraftstoff ggf. vorgeheizt. Das Signal dient der Anzeige des Heizungsstatus.

Heizung aus -> Lampe aus
Heizung ein -> Lampe ein
Heizung ein und Startversuch -> Lampe blinkend
Heizung nicht möglich -> Lampe";
CM_ SG_ 967 MO_Heissleuchte "Ansteuerung der Kühlwassertemperatur-Heißleuchte (Sensor nur noch am Motorsteuergerät): Temperaturschaltschwellen mit Hysterese (bei VW D1/Colorado Kombi derzeit noch nicht genutzt).";
CM_ SG_ 967 MO_ITM_Warnung_Pumpe "Textanzeige: 'Motor sofort abstellen, geschaltete Wasserpumpe defekt / klemmt'";
CM_ SG_ 967 MO_KJS_nicht_bereit "Dieses Signal zeigen einen Fehler der Kühlerjalousie mit unbekannter Stellung der Lamellen. ";
CM_ SG_ 967 MO_Kuehlerluefter_1 "Ansteuertastverhaeltnis (PWM) der Kuehlerluefterendstufe 1";
CM_ SG_ 967 MO_Kuehlerluefter_2 "Ansteuertastverhaeltnis (PWM) der Kuehlerluefterendstufe 2";
CM_ SG_ 967 MO_Kuehlerluefter_MUX "Multiplexer für das Signal 'MO_Kuehlerlüfter'";
CM_ SG_ 967 MO_OBD2_Lampe "OBD bzw. MIL-Lampe wird vom Motorsteuergerät angesteuert, die Information im Signal GE_OBD_Status wird vom Motorsteuergerät an das Kombi weitergereicht";
CM_ SG_ 967 MO_Oelwarnung_max "Ölstandswarnung mit der Aufforderung zum Ölwechsel.
Hintergrund: Bei Kraftstoffeintrag (B20) ins Öl verbleibt der RME-Anteil irreversibel im Öl.";
CM_ SG_ 967 MO_Partikel_Lampe "Partikelfilter-Lampe wird eingeschaltet";
CM_ SG_ 967 MO_RedFahrleistung_Lampe "Ansteuerung der Turtle-Mode Lampe für E-Traktion Fahrzeuge";
CM_ SG_ 967 MO_Systemlampe "EGas Systemlampe (EPC) oder Vorglühlampe im Kombi, Kombi steuert immer gleiche
LED an, nur über Ziffernblatt wird die EPC von der Vorglühlampe differenziert";
CM_ SG_ 967 MO_Tankdeckel_Lampe "Ansteuerung Tankdeckel-Warnlampe Kombiinstrument (nur Ottomotoren) z.Zt. Vorhalt VW";
CM_ SG_ 967 MO_Text_Motorstart "Anzeigetexte für Start/Stopp und Motor-Start
0xB Fehler_Kupplungsschalter nur für PAG-MLB";
CM_ SG_ 967 MO_Text_Partikelfil_Reg "Über dieses Bit im Kombi wird ein Klartextanzeige erzeugt werden: 'Partikelfilter benötigt Regeneration'.
";
CM_ SG_ 967 MO_Text_Tankdeckelwarn "Textbit der Tankdeckelwarnung, z.Zt. Vorhalt VW";
CM_ SG_ 967 MO_Vorglueh_Lampe "Vorglühlampe im Kombi, Kombi steuert immer gleiche LED an. 
Mit Einführung des Einheits-Kombis sind getrennte Signalwege für Vorglühlampe und EPCL notwendig.";
CM_ SG_ 967 MO_Zustand_HWP "Rückmeldung des  Ansteuerzustand der Hauptwasserpumpe an das Klima-SG .
Der Zustand 'HWP fördert' wird übermittelt, wenn die Schaufeln der Hauptwasserpumpe frei drehen können und die Motordrehzahl und damit die Wasserpumpendrehzahl größer als Null ist. B";
CM_ SG_ 967 OLEV_Oelstand_nicht_vorhanden "Kein aktueller Ölstand vorhanden";
CM_ SG_ 967 OLEV_Systemstoerung "Systemstörung im Ölsystem";
CM_ SG_ 967 WIV_Anzeige_aktiv "Peilstabsanzeigefunktion aktiv";
CM_ SG_ 967 WIV_laufender_Motor "Messung bei laufendem Motor nicht möglich";
CM_ SG_ 967 WIV_nachfuellanzeige_ein "Steuert das Aufblenden der Nachfüllanzeige im Kombi, nach Klemme 15 ein und geöffneter Motorhaube";
CM_ SG_ 967 WIV_nicht_betriebswarm "Motor nicht betriebswarm, Messung ungenau";
CM_ SG_ 967 WIV_Oeldr_Warn_Motor "Löst im Kombiinstrument die rote Prio1-Öldruckwarnung (inkl. 3xBeep) aus.
nur MLB: die Warnauslösung erfolgt nur bei gleichzeitig gesetztem 'WIV_Enable_Oeldr_Motor'";
CM_ SG_ 967 WIV_Oeldyn_avl "Ölstand aus dynamischer Messung vorhanden";
CM_ SG_ 967 WIV_Oelmenge "Ölmenge zwischen Min und Max";
CM_ SG_ 967 WIV_Oelmin_Warn "Signal gibt an wenn der Ölstand die Min-Schwelle unterschritten hat";
CM_ SG_ 967 WIV_Oelstand "8 Segmente zur Balkenanzeige des Ölstands";
CM_ SG_ 967 WIV_Oelstand_nicht_vorhanden "Kein aktueller Ölstand vorhanden";
CM_ SG_ 967 WIV_Oelsystem_aktiv "Gesamtölsystem aktiv (entspricht Ölsensor verbaut) und das Ölstand-Untermenu im MMI aktiv";
CM_ SG_ 967 WIV_Schieflage "Fahrzeug steht nicht waagerecht, Messung ungenau";
CM_ SG_ 967 WIV_Sensorfehler "Ölstand/Öltemperatursensor (TOG) defekt";
CM_ SG_ 967 WIV_Ueberfuell_deaktiv "Unterdrückung der Warnung im Kombi die durch Signal WIV_Ueberfuel_Warn ausgelöst wird";
CM_ SG_ 967 WIV_Ueberfuell_Warn "Ölstand hat die Überfüllschwelle überschritten";
CM_ SG_ 967 WIV_Unterfuell_Warn "Ölstand hat die Unterfüllschwelle unterschritten";

CM_ SG_ 327 MO_Anzeige_Drehmoment "Drehmomentssignal für Sport-HMI im Kombi.";
CM_ SG_ 327 MO_Anzeige_Kaltabfahrbegrenzung "Anzeigesignal der Kaltabfahrbegrenzung";
CM_ SG_ 327 MO_Anzeige_Leistung "Leistungssignal für Sport-HMI im Kombi.";
CM_ SG_ 327 MO_Anzeige_Verbr_Einheit "Signal steht im Kontext MO_Anzeige_Verbrauch und überträgt die Verbrauchseinheit der aktuellen Antriebsart. Signal muss in der gleichen Botschaft wie MO_Anzeige_Verbrauch übertragen werden";
CM_ SG_ 327 MO_eATL_Status_Anzeige "Signal zur Anzeige des aktuellen Betriebszustandes vom elektrischen Turbolader";
CM_ SG_ 327 MO_EM1_SumRadMomReku_Ist "Gibt die Summe der Radbremsmomente an, die von der E-Maschine gestellt werden (Rekuperationsmomente).";
CM_ SG_ 327 MO_Hochschaltdrehz "Hochschaltdrehzahl bei manuellem Gangwechsel über Lenkrad Tip-Up oder Gangwahlhebel falls dieser in Tippgasse.
Nur AUDI RS-Modelle!";
CM_ SG_ 327 MO_Schaltblitz_Anz "Signalisierung der drehzahlabhängigen Schaltblitzanzeige im Kombiinstrument (0-100%)";

CM_ SG_ 1366 FWS_Koeffizient_2 "Von der quadratischen Geschwindigkeit abhängiger Fahrwiderstandsanteil. Details zum Signal siehe Dokument zur Signalbeschreibung";
CM_ SG_ 1366 FWS_QBit_Koeffizient_2 "Qualitätsbit zu FWS_Koeffizient_2.
Nähere Beschreibung siehe Dokument zur Signalbeschreibung";
CM_ SG_ 1366 MO_Fahrzeugabstellzeit "Zeit seit letzter Fahrbereitschaft.";
CM_ SG_ 1366 MO_Fahrzeugabstellzeit_Status "Status Fahrzeugabstellzeit";
CM_ SG_ 1366 MO_HV_Auszeit "Zeit seit letzter Hochvoltaktivität.";
CM_ SG_ 1366 MO_HV_Auszeit_Status "Status HV-Auszeit.";
CM_ SG_ 1366 MO_Oelstand_Sens_roh "Rohwert des Ölstands-Sensors in mm";
CM_ SG_ 1366 MO_Verbau_StartSys_EM_HV "Signal zeigt an, welche Komponenten des Startsystemes verbaut sind.
Verbau E-Maschine HV";
CM_ SG_ 1366 MO_Verbau_StartSys_EM_MV "Signal zeigt an, welche Komponenten des Startsystemes verbaut sind.
Verbau E-Maschine MV z.B. 48V";
CM_ SG_ 1366 MO_Verbau_StartSys_Q_Diode "Signal zeigt an, welche Komponenten des Startsystemes verbaut sind.
Verbau Q_Diode";
CM_ SG_ 1366 MO_Verbau_StartSys_Ritzelstarter "Signal zeigt an, welche Komponenten des Startsystemes verbaut sind.
Verbau Ritzel Starter";
CM_ SG_ 1366 MO_Verbau_StartSys_RSG_MV "Signal zeigt an, welche Komponenten des Startsystemes verbaut sind.
Verbau Riemen Starter Generator MV z.B. 48V";
CM_ SG_ 1366 MO_Verbau_StartSys_RSG_NV "Signal zeigt an, welche Komponenten des Startsystemes verbaut sind.
Verbau Riemen Starter Generator NV z.B. 12V";
CM_ SG_ 1366 MO_Ziel_SoC_Fremdladung "Auf diesen SoC soll MHEV-Speicher geladen werden, wenn ein Ladegerät erkannt ist.";

CM_ SG_ 283 MO_AIAD_MaxLeistung "Maximal zulässige Leistung, die das PDCC einzustellen hat.";
CM_ SG_ 283 MO_EBoost_verf_praed "Zeigt an, ob für eine im Projekt definierte Zeit (max. 10s) E-Boost in Höhe von EM1_maxPred_Moment verfügbar sein wird.

0 - Init_oder_nicht_verfügbar
1 - EBoost_kurzzeit_verfügbar (~3Sek.)
2 - EBoost_langzeit_verfügbar (~10Sek)";
CM_ SG_ 283 MO_eLaunch_verf "Zeigt an, ob aus Antriebssicht E-Launch verfügbar ist.";
CM_ SG_ 283 MO_Fahrbereitschaft "Das Signal MO_Fahrbereitschaft zeigt in mehreren Stufen an, ob der Motor in einem anfahrbereiten Zustand ist.";
CM_ SG_ 283 MO_Freilauf_Info "Freilauf Informationssignal vom Motorsteuergerät zum Getriebesteuergerät. Das Motorsteuergerät kann über dieses Signal den Freilauf freigeben, verhindern bzw. explizit anfordern.";
CM_ SG_ 283 MO_Freilauf_Status "Freilauf-Status-Signal vom Frailauf-Master an aktive Freilauf-Teilnehmer. In diesem Signal zeigt der Freilauf-Master an, welchen aktuellen Status die Freilauf-Betriebsstrategie hat.";
CM_ SG_ 283 MO_Heckspoiler_Anf "Anforderung den Heckspoiler zur Ladeluft- bzw. Motorraumkühlung auszufahren.";
CM_ SG_ 283 MO_Krit_Heckobjekt "Beschreibt die Kritikalität des hinter einem in der Spur fahrenden Fahrzeuges";
CM_ SG_ 283 MO_NGS_Gangpos "Gang- bzw. Neutralinformation des erweiterten Neutralgangsensors. Bedingt durch den eingeschränkten Erfassungssbereich des Sensors sind die Ganginformationen als eingelegt bzw. fast eingelegt/vorausgewählt zu interpretieren (nur Handschalter)";
CM_ SG_ 283 MO_Parken_WFS_Status "Gesammelte Rückmeldung des Limitierungsstatus aller EM in einem vom ZFAS angeforderten Parkvorgang.";
CM_ SG_ 283 MO_Positionierung_aktiv "Zeigt an, dass die Motorpositionierung mit Hilfe des Riemenstartergenerator momentan aktiv ist.";
CM_ SG_ 283 MO_Rennstart_verf "Zeigt an, ob aus Antriebssicht ein Rennstart verfügbar ist.";
CM_ SG_ 283 MO_Status_Katheizen "Status des Katheizen.

0 = Katheizen nicht aktiv
1 = Katheizen aktiv";
CM_ SG_ 283 MO_Status_MIN_Wunschdrehzahl "In 2.0 TFSI Motorprojekten EA888 Gen3 und EA888 EVO4 im MLBevo (AU536 und AU49x, in allen anderen Projekten ist das Signal nicht zu implementieren) wird das Bus Signal MO_MIN_Wunschdrehzahl verwendet, um durch eine damit angepasste Gangwahl des Getriebes ";

CM_ SG_ 2589283475 SCR_Einheit "Länderspezifische Einheit der Restreichweite (km oder mi)";
CM_ SG_ 2589283475 SCR_Fuellstand "Füllstand des SCR-Tanks in % bezogen auf das tatsächliche Tankvolumen";
CM_ SG_ 2589283475 SCR_Nachfuellmenge_Einheit "Länderspezifische Einheit der min/max Nachfüllmenge (Liter/Gallone US/Gallone UK)";
CM_ SG_ 2589283475 SCR_Nachfuellmenge_max "Maximales Volumen, mit dem der SCR Tank nachbefüllt werden kann.";
CM_ SG_ 2589283475 SCR_Nachfuellmenge_min "Minimal erforderliche Nachfüllmenge, damit eine Betankung erkannt wird";
CM_ SG_ 2589283475 SCR_Restreichweite "Verbleibende Restreichweite mit aktuellem SCR-Tankinhalt (ohne Dimension)";
CM_ SG_ 2589283475 SCR_Retriggersignal "Trigger zur Erneuerung der SCR Kombibotschaft";
CM_ SG_ 2589283475 SCR_Tankvolumen "Volumen des verbauten SCR Tanks. Dimension abhängig von Signal SCR_Nachfüllmenge_Einheit.";
CM_ SG_ 2589283475 SCR_Zustand "Zustand des SCR Systems, der an das Kombi/MMI übermittelt wird";

CM_ SG_ 834 MO_E_Texte_LB "Add-on text information LB PHEV";
CM_ SG_ 834 MO_Energyflow "Energy flow among HV battery, ICE and EMs";
CM_ SG_ 834 MO_Sperrung_FahrPr_BZS_LB "LB Performance Strategies allowed";
CM_ SG_ 834 MO_TorqueDistrib_Hi "Torque distribution Rear Left/Rear Right";
CM_ SG_ 834 MO_TorqueDistrib_VL "Torque distribution Front Left";
CM_ SG_ 834 MO_TorqueDistrib_VR "Torque distribution Front Right";
CM_ SG_ 834 MO_Wassertemp_Schutz_Anf "Level of the TH2O protection functionality";

CM_ SG_ 706 MO_ADR_Status "Status der Arbeitsdrehzahlregelung";
CM_ SG_ 706 MO_AGA_Sound_Texte "Textausgabe des aktuellen Sound-Zustandes der Abgasklappensteuerung";
CM_ SG_ 706 MO_Anz_Kuehlerluefter "Signal bei aktivem Kühlerlüfternachlauf (Motor aus) im Allgemeinen für die Anzeige im Kombi-Instument zur Information des Kunden über diesen Lüfterlauf";
CM_ SG_ 706 MO_Anzeige_FMAus_Text "Fehlerstatus des FMAus-Systems (z.B. Fehler im Zusatzspeicher)";
CM_ SG_ 706 MO_Anzeige_StSt_Symbol "Steuert die Anzeige der StSt-Symbolik im Kombi";
CM_ SG_ 706 MO_Anzeige_StSt_Text "Steuert die Anzeige der StSt-Texte im Kombi";
CM_ SG_ 706 MO_Avus_Motorschutz "Warntexten zum Kombi für den Fall des Avus-Notlauf. Priowarnung, kann parallel mit anderen Warnungen 
im Mitteldisplay angezeigt werden.";
CM_ SG_ 706 MO_Fehler_MSpG "Wenn das Motorraumspülgebläse defekt ist, oder die Motorraumtemperatur zu hoch sendet die DME Info ans Kombiinstrument. Dieses gibt Textmeldung aus. Und blinkende Heissleuchte.";
CM_ SG_ 706 MO_im_Leerlauf "Motor ist im Leerlauf";
CM_ SG_ 706 MO_Oel_Temp_Radsatz_Warn "Öltemperatur im Getriebe Radsatz Warnung";
CM_ SG_ 706 MO_OelMessung_Dauer "Ölstandsmessung deaktiv/ Restdauer der Messung";
CM_ SG_ 706 MO_Red_Fahrleistung "Signal zur Anzeige von den verschiedenen Leistungsreduzierungsstufen.";
CM_ SG_ 706 MO_Rekuperationsstufe "In Projekten mit variablen oder anwählbaren Rekuperationsstufen soll dem Fahrer die aktuell ausgewählte Stufe über ein Icon in den Anzeigeinstrumenten visualisiert werden können. Dies dient der Nachvollziehbarkeit für den Kunden in Bezug auf eine zukünfti";
CM_ SG_ 706 PEA_Texte "Status der Funktion PEA";
CM_ SG_ 706 TSK_Einheit_vMax_FahrerInfo "Einheit zu TSK_vMax_FahrerInfo. Das MSG spiegelt hier KBI_MFA_v_Einheit und stellt den Anzeigewert in dieser Einheit zur Verfügung (kein zyklisches Mux)";
CM_ SG_ 706 TSK_Status_vMax_FahrerInfo "Status der TSK_vMax_FahrerInfo zur Steuerung von PopUps, Fahrzeugstatus und ggf. einer LED. Bei Wert 0 in TSK_vMax_Fahrerinfo soll auf eine unspezifische Begrenzung hingewiesen werden (z.B. wegen Momentenbegrenzung), bei allen anderen Werten soll dieser a";
CM_ SG_ 706 TSK_Ueberstimmt_vMax_FahrerInfo "Information ueber den Zustand wann die vMax-Limitierung vom Fahrer ueberstimmt wird.";
CM_ SG_ 706 TSK_vMax_FahrerInfo "anzuzeigende Begrenzungsgeschwindigkeit bei aktiver HGB";
CM_ SG_ 706 WIV_Enable_Oeldr_Motor "Schaltet die interne Öldruckauswertung im Kombiinstrument ab und aktiviert die Auswertung des Bits 'WIV_Oeldr_Warn_Motor'";

CM_ SG_ 2589283599 MO_CatHeatBar_LB "Cat heating progress bar";
CM_ SG_ 2589283599 MO_Eboost_LB_active "LB eboost activation status";
CM_ SG_ 2589283599 MO_Eboost_LB_available "LB eboost is available in the actual DM/PS";
CM_ SG_ 2589283599 MO_Eboost_LB_driveraction "LB eboost driver advice";
CM_ SG_ 2589283599 MO_Eboost_LB_failure "LB eboost functionality failure";
CM_ SG_ 2589283599 MO_Eboost_LB_LVLavailable "LB eboost levels available";
CM_ SG_ 2589283599 MO_Eboost_LB_LVLselected "LB eboost level selected";
CM_ SG_ 2589283599 MO_Eboost_LB_possible "LB eboost is avaialbe in the actual DM/PS and possible based on system status";
CM_ SG_ 2589283599 MO_Kilometerstand_Wakeup "Odometer value sent at wake-up";
CM_ SG_ 2589283599 MO_Nachlaufzeit_Kuehlerluefter_2 "Nachlaufzeit Kühlerlüfter 2 MSG für Verwendung im TME SG";
CM_ SG_ 2589283599 MO_Status_KL "Diagnose_nicht_durchgefuehrt
Lüfter_iO
Diagnose_laeuft
Lüfter_iO_Diagnose_laeuft
Lüfter_Notlauf
Lüfter_Fehler";
CM_ SG_ 2589283599 MO_TME_KL_Anf_LB "Intercooler cooling request";

CM_ SG_ 1601 MO_Ansaugsystem "Art des Ansaugsystems des Verbrennungsmotors";
CM_ SG_ 1601 MO_Anzahl_Zyl "Zylinderzahl des Verbrennungsmotors";
CM_ SG_ 1601 MO_Anzeige_StSt_gueltig "Zeigt die Gültigkeit der neuen StSt-Anzeigesignale an, MO_Anzeige_StSt_Text und  MO_Anzeige_Symbol. Mo_Text_Motorstart 1..5 sind zu ignorieren.";
CM_ SG_ 1601 MO_Code "Motorcodierinformation Version 16 (Details siehe Anhang)";
CM_ SG_ 1601 MO_DPF_verbaut "Verbauinformation Diesel-Partikel-Filter
";
CM_ SG_ 1601 MO_Faktor_Momente_02 "Dieses Signal schaltet den Wertebereich aller Momente vom Motor, Getriebe, TSK, Bremse ... um! Die Momente besitzen somit einen variablen Wertebereich, weil sich durch den Faktor die Momente sowohl in Auflösung als auch Maximalwerten ändert.

0x0 nicht ";
CM_ SG_ 1601 MO_Getriebe_Code "Getriebecodierung des Motors";
CM_ SG_ 1601 MO_Hubraum "Hubraum des Verbrennungsmotors";
CM_ SG_ 1601 MO_Hybridfahrzeug "Anhand dieses Signals plausibilisiert die Lenkhilfe das Bit Fahrbereitschaft.

Im Projekt Cayenne PHEV (und ggf. auch VW526 PHEV) ist aus Gründen der Abwärtskompatibilität der Wert '2' zu senden.";
CM_ SG_ 1601 MO_Kraftstoffart "Primärkraftstoff zum Antrieb des Fahrzeugs";
CM_ SG_ 1601 MO_Leistung "Nennleistung des Verbrennungsmotors

Im reinen E-Fahrzeug (BEV): Ausgabe der elektrischen Systemleistung";
CM_ SG_ 1601 MO_OBD_Typ "Abgastyp OBD
Hinweis: In Fahrzeugen mit dem Zielmarkt China und einer Zertifizierung ab China 6 muss auf dem Signal 'MO_OBD_Typ' der Wert 'US_OBD' gesendet werden.";
CM_ SG_ 1601 MO_StartStopp_Codiert "Funktion StartStopp im aktuellen Klemmenzyklus verbaut";
CM_ SG_ 1601 Motor_Code_01_CRC "Für MLB:
'Berechnung siehe Lastenheft 'Kommunikationsabsicherung für FlexRay und CAN''

Ab MQB und MLBevo:
'Berechnung siehe Lastenheft 'End-to-End Kommunikationsabsicherung''

Endwerte siehe Begleitdokument 'S-PDU Kennungsfolgen'";
CM_ SG_ 1601 TSK_Codierung "Information über den plausibilisierten Codierungszustand des Triebstrangskoordinators auf ACC oder GRA.";

CM_ SG_ 813 MO_akt_Betrieb "Motor läuft aktuell im Benzin- oder Gasbetrieb";
CM_ SG_ 813 MO_AnzeigeGasbetrieb "Anzeige des Betriebszustands bei Umschaltung zwischen Gas- und Benzinbetrieb";
CM_ SG_ 813 MO_CNG_Tankstopp "Der CNG-Tankalgorithmus hat einen Tankstopp (CNG-Tank) erkannt.
Bei separatem CNG-SG gatet das MSG die Information.";
CM_ SG_ 813 MO_CNG_Ueberlauf "Der motorsteuergeräteinterne Verbrauchszähler ist mindestens einmal übergelaufen. Dieses Bit wird genutzt, um erkennen zu können, dass das Motorsteuergerät aus dem Reset-Zustand hochläuft.";
CM_ SG_ 813 MO_Erdgasqualitaet "Erdgas-Qualität abgestuft in 70%, 80%, 90% und 100% (bei CNG bezogen auf 100% Methan). Berechnung erfolgt einmalig nach jeder Betankungserkennung.";
CM_ SG_ 813 MO_Fuellstand_LPG "Tankfüllstand LPG (Sensor am MSG/LPG-SG)";
CM_ SG_ 813 MO_Fuellungsgrad_CNG "Gefilterter temperaturkompensierter Gasdruckwert als Prozentwert vom Maximalwert wird im Kombi als Zeiger dargestellt.";
CM_ SG_ 813 MO_Fuellungsgrad_LPG "Füllungsgrad des LPG-Tanks in %";
CM_ SG_ 813 MO_LPG_Tankstopp "Der LPG-Tankalgorithmus hat einen Tankstopp (LPG-Tank) erkannt.
Bei separatem LPG-SG gatet das MSG die Information.";
CM_ SG_ 813 MO_LPG_Ueberlauf "Der motorsteuergeräteinterne Verbrauchszähler ist mindestens einmal übergelaufen. Dieses Bit wird genutzt, um erkennen zu können, dass das Motorsteuergerät aus dem Reset-Zustand hochläuft.";
CM_ SG_ 813 MO_Tankmasse_CNG "Max. Tankmasse in kg bei einem Tankdruck von 200bar, in Abhängigkeit vom max. Tankvolumen und der CNG-Tanktemperatur beim Befüllen (Verwendung im Kombi zur Reichweitenberechnung)";
CM_ SG_ 813 MO_Tankvolumen_LPG "Volumen des LPG-Tanks";
CM_ SG_ 813 MO_Verbrauch_CNG "Motorsteuergeräteinterner Verbrauchszähler, der vom Kombi zyklisch ausgelesen wird, um die Gasmenge zur Verbrauchsberechnung aufzusummieren; aus diesem Zählerstand werden Momentan- und Durchschnittsverbrauch berechnet; das Überlauf-Bit ist zu berücksichti";
CM_ SG_ 813 MO_Verbrauch_LPG "Motorsteuergeräteinterner Verbrauchszähler, der vom Kombi zyklisch ausgelesen wird, um die Gasmenge zur Verbrauchsberechnung aufzusummieren; aus diesem Zählerstand werden Momentan- und Durchschnittsverbrauch berechnet; das Überlauf-Bit ist zu berücksichti";
CM_ SG_ 813 MO_Verbrauchsaequivalent "Faktor zur Umrechnung des aktuellen/letzten Verbrauchs im LPG/CNG-Betrieb auf einen äquivalenten Benzin-Verbrauch (zur Ermittlung der Gesamtreichweite)";

CM_ SG_ 305 Ladezustand_02 "Aktueller relativer Ladezustand der HV-Batterie
";
CM_ SG_ 305 MO_ePerformance "Zeigt die elektrische Leistungreserve bei BEV und PHEV Projekten an.
Bei Init und Fehler soll keine Anzeige erfolgen. ";
CM_ SG_ 305 MO_ePowermeter "Anzeige ePowermeter (Fahrreserve elektrisch bis Start Verbrennungsmotor (Verbrenner startet bei 100%))";
CM_ SG_ 305 MO_Powermeter "Anzeigewerte im Kombi
0       = Unteres Ende Bremsen/grau;
340   = Unteres Ende CHARGE;
1020 = READY;
1870 = Oberes Ende EFFICIENCY;
3400 = 100%;
4080 = MAX;";
CM_ SG_ 305 MO_Powermeter_Elm "Die Prozentwerte ergeben sich aus dem momentanen Moment der E-Maschine bezogen auf das im aktuellen Arbeitspunkt maximal mögliche Moment der E-Maschine (generatorisch = negativ / motorisch = positiv )";
CM_ SG_ 305 MO_Powermeter_Elm_02 "relatives Moment / relative Leistung der elektrischen Maschine";
CM_ SG_ 305 MO_Zust_Antrieb "Signalisiert die Zuordnung der Antriebsverbräuche zu den Antriebsmaschinen für die Restreichweitenberechnung, nicht gleichbedeutend mit Motorlauf EM oder VM bzw. Brennstoffzelle";
CM_ SG_ 305 MO_Zust_Betriebsstrategie "Signalisiert den aktuellen Zustand der Betriebsstrategie";

CM_ SG_ 1376 MO_Gesamtst_Spgfreiheit "0x0 (00)   Funktion Init (ohne Funktion)
0x1 (01)   HV-System spannungsfrei 
0x2 (10)   HV-System nicht spannungsfrei 
0x3 (11)   Fehler";
CM_ SG_ 1376 MO_HV_Spannungsfreiheit "Anzeige der Spannungsfreiheit des HV-Systems im Kombi (Service und Produktion). 

Abhängigkeiten zu anderen Signalen:
BMS_Status_Spannungsfreiheit und EM_Status_Spannungsfreiheit und BMS_Status_ServiceDisconnect";
CM_ SG_ 1376 MO_HYB_Status_Betriebsstrategie "Zustände der Betriebsstrategie im MSG";
CM_ SG_ 1376 MO_Reku_Leistung "Durchschnittliche Rekuperationsleistung zur Umrechnung im Kombi";
CM_ SG_ 1376 MO_Tankbereitschaft_Status "Meldung der Tankbereitschaft";
CM_ SG_ 1376 Motor_Hybrid_04_BZ "4bit-Botschaftszaehler, wird in jeder Sendebotschaft inkrementiert";
CM_ SG_ 1376 Motor_Hybrid_04_CRC "'Berechnung siehe Lastenheft 'End-to-End Kommunikationsabsicherung'

Endwerte siehe Begleitdokument 'S-PDU Kennungsfolgen'";
BA_DEF_REL_ BU_SG_REL_  "GenSigTimeoutTime" INT 0 65535;
BA_DEF_ BO_  "DiagRequest" ENUM "No", "Yes";
BA_DEF_ BO_  "DiagResponse" ENUM "No", "Yes";
BA_DEF_ BO_  "DiagState" ENUM "No", "Yes";
BA_DEF_ BO_  "GenMsgChkConstant" HEX 0 4095;
BA_DEF_ BO_  "GenMsgCycleTime" INT 0 65535;
BA_DEF_ BO_  "GenMsgCycleTimeFast" INT 0 65535;
BA_DEF_ BO_  "GenMsgDelayTime" INT 0 100000;
BA_DEF_ BO_  "GenMsgILSupport" ENUM "No", "Yes";
BA_DEF_ BO_  "GenMsgNrOfRepetition" INT 0 100;
BA_DEF_ BO_  "GenMsgPDUConstants" STRING;
BA_DEF_ BO_  "GenMsgSendType" ENUM "Cyclic", "not_used", "not_used", "not_used", "not_used", "not_used", "not_used", "IfActive", "NoMsgSendType";
BA_DEF_ BO_  "GenMsgStartDelayTime" INT 0 100000;
BA_DEF_ BO_  "NmMessage" ENUM "No", "Yes";
BA_DEF_ BO_  "NmhMessage" ENUM "No", "Yes";
BA_DEF_ BO_  "MsgType" ENUM "Application", "NM ", "NMH", "TP2.0", "ISO-TP ", "BAP", "EID", "KS", "XCP_PRE_CONFIGURED", "XCP_RUNTIME_CONFIGURED";
BA_DEF_ BO_  "VAGTP20_API" HEX 0 255;
BA_DEF_ BO_  "VAGTP20_DynConnection" ENUM "No", "Yes";
BA_DEF_ BO_  "VAGTP20_DynSetup" ENUM "No", "Yes";
BA_DEF_ BO_  "VAGTP20_StatConnection" ENUM "No", "Yes";
BA_DEF_ SG_  "GenSigActiveRepetitions" INT -2147483648 2147483647;
BA_DEF_ SG_  "GenSigInactiveValue" INT -2147483648 2147483647;
BA_DEF_ SG_  "GenSigSendType" ENUM "Cyclic", "OnWrite", "OnWriteWithRepetition", "OnChange", "OnChangeWithRepetition", "IfActive", "IfActiveWithRepetition", "NoSigSendType", "OnChangeAndIfActive", "OnChangeAndIfActiveWithRepetition";
BA_DEF_ SG_  "GenSigStartValue" INT -2147483648 2147483647;
BA_DEF_ SG_  "NWM-WakeupAllowed" ENUM "No", "Yes";
BA_DEF_ SG_  "GenSigFuncType" ENUM "NoFunction", "MsgCounter", "CRC-8", "XOR", "XOR-2", "DatedBit", "SW-Kl15", "CHK", "Constant", "Protocol", "CRC-8-SAE_J1850", "CRC-32", "DataLength", "DataID", "MsgCounter16", "SOK-Signatur", "Cluster";
BA_DEF_ SG_  "GenSigSwitchedByIgnition" ENUM "No", "Yes";
BA_DEF_ SG_  "Fehlerwert" HEX 0 2147483647;
BA_DEF_ SG_  "GenSigMissingSourceValue" HEX 0 2147483647;
BA_DEF_DEF_REL_  "GenSigTimeoutTime" 0;
BA_DEF_DEF_  "DiagRequest" "No";
BA_DEF_DEF_  "DiagResponse" "No";
BA_DEF_DEF_  "DiagState" "No";
BA_DEF_DEF_  "GenMsgChkConstant" 0;
BA_DEF_DEF_  "GenMsgCycleTime" 0;
BA_DEF_DEF_  "GenMsgCycleTimeFast" 0;
BA_DEF_DEF_  "GenMsgDelayTime" 0;
BA_DEF_DEF_  "GenMsgILSupport" "No";
BA_DEF_DEF_  "GenMsgNrOfRepetition" 0;
BA_DEF_DEF_  "GenMsgPDUConstants" "";
BA_DEF_DEF_  "GenMsgSendType" "NoMsgSendType";
BA_DEF_DEF_  "GenMsgStartDelayTime" 0;
BA_DEF_DEF_  "NmMessage" "No";
BA_DEF_DEF_  "NmhMessage" "No";
BA_DEF_DEF_  "MsgType" "Application";
BA_DEF_DEF_  "VAGTP20_API" 0;
BA_DEF_DEF_  "VAGTP20_DynConnection" "No";
BA_DEF_DEF_  "VAGTP20_DynSetup" "No";
BA_DEF_DEF_  "VAGTP20_StatConnection" "No";
BA_DEF_DEF_  "GenSigActiveRepetitions" 0;
BA_DEF_DEF_  "GenSigInactiveValue" 0;
BA_DEF_DEF_  "GenSigSendType" "NoSigSendType";
BA_DEF_DEF_  "GenSigStartValue" 0;
BA_DEF_DEF_  "NWM-WakeupAllowed" "No";
BA_DEF_DEF_  "GenSigFuncType" "NoFunction";
BA_DEF_DEF_  "GenSigSwitchedByIgnition" "Yes";
BA_DEF_DEF_  "Fehlerwert" 0;
BA_DEF_DEF_  "GenSigMissingSourceValue" 0;
BA_ "GenMsgCycleTime" BO_ 1607 320;
BA_ "GenMsgILSupport" BO_ 1607 1;
BA_ "GenMsgSendType" BO_ 1607 0;
BA_ "GenMsgCycleTime" BO_ 168 50;
BA_ "GenMsgILSupport" BO_ 168 1;
BA_ "GenMsgPDUConstants" BO_ 168 "0x52,0x8c,0x50,0xee,0x4f,0xa6,0xcc,0xcf,0x7d,0x2f,0x98,0x6b,0x27,0x41,0x9f,0x93";
BA_ "GenMsgSendType" BO_ 168 0;
BA_ "GenMsgCycleTime" BO_ 958 100;
BA_ "GenMsgDelayTime" BO_ 958 10;
BA_ "GenMsgILSupport" BO_ 958 1;
BA_ "GenMsgPDUConstants" BO_ 958 "0x1f,0x28,0xc6,0x85,0xe6,0xf8,0xb0,0x19,0x5b,0x64,0x35,0x21,0xe4,0xf7,0x9c,0x24";
BA_ "GenMsgSendType" BO_ 958 0;
BA_ "GenMsgCycleTime" BO_ 1631 320;
BA_ "GenMsgILSupport" BO_ 1631 1;
BA_ "GenMsgSendType" BO_ 1631 0;
BA_ "GenMsgCycleTime" BO_ 812 200;
BA_ "GenMsgDelayTime" BO_ 812 40;
BA_ "GenMsgILSupport" BO_ 812 1;
BA_ "GenMsgSendType" BO_ 812 0;
BA_ "GenMsgCycleTime" BO_ 1648 500;
BA_ "GenMsgDelayTime" BO_ 1648 20;
BA_ "GenMsgILSupport" BO_ 1648 1;
BA_ "GenMsgSendType" BO_ 1648 0;
BA_ "GenMsgCycleTime" BO_ 815 40;
BA_ "GenMsgILSupport" BO_ 815 1;
BA_ "GenMsgSendType" BO_ 815 0;
BA_ "GenMsgCycleTime" BO_ 1391 500;
BA_ "GenMsgILSupport" BO_ 1391 1;
BA_ "GenMsgSendType" BO_ 1391 0;
BA_ "GenMsgCycleTime" BO_ 967 80;
BA_ "GenMsgILSupport" BO_ 967 1;
BA_ "GenMsgSendType" BO_ 967 0;
BA_ "GenMsgCycleTime" BO_ 327 50;
BA_ "GenMsgILSupport" BO_ 327 1;
BA_ "GenMsgSendType" BO_ 327 0;
BA_ "GenMsgCycleTime" BO_ 1366 960;
BA_ "GenMsgILSupport" BO_ 1366 1;
BA_ "GenMsgSendType" BO_ 1366 0;
BA_ "GenMsgCycleTime" BO_ 283 500;
BA_ "GenMsgDelayTime" BO_ 283 10;
BA_ "GenMsgILSupport" BO_ 283 1;
BA_ "GenMsgSendType" BO_ 283 0;
BA_ "GenMsgCycleTime" BO_ 2589283475 960;
BA_ "GenMsgILSupport" BO_ 2589283475 1;
BA_ "GenMsgSendType" BO_ 2589283475 0;
BA_ "GenMsgCycleTime" BO_ 834 80;
BA_ "GenMsgILSupport" BO_ 834 1;
BA_ "GenMsgSendType" BO_ 834 0;
BA_ "GenMsgCycleTime" BO_ 706 400;
BA_ "GenMsgDelayTime" BO_ 706 80;
BA_ "GenMsgILSupport" BO_ 706 1;
BA_ "GenMsgSendType" BO_ 706 0;
BA_ "GenMsgCycleTime" BO_ 2589283599 960;
BA_ "GenMsgDelayTime" BO_ 2589283599 160;
BA_ "GenMsgILSupport" BO_ 2589283599 1;
BA_ "GenMsgSendType" BO_ 2589283599 0;
BA_ "GenMsgChkConstant" BO_ 1601 71;
BA_ "GenMsgCycleTime" BO_ 1601 960;
BA_ "GenMsgILSupport" BO_ 1601 1;
BA_ "GenMsgPDUConstants" BO_ 1601 "0x47,0x47,0x47,0x47,0x47,0x47,0x47,0x47,0x47,0x47,0x47,0x47,0x47,0x47,0x47,0x47";
BA_ "GenMsgSendType" BO_ 1601 0;
BA_ "GenMsgCycleTime" BO_ 813 40;
BA_ "GenMsgILSupport" BO_ 813 1;
BA_ "GenMsgSendType" BO_ 813 0;
BA_ "GenMsgCycleTime" BO_ 305 20;
BA_ "GenMsgILSupport" BO_ 305 1;
BA_ "GenMsgSendType" BO_ 305 0;
BA_ "GenMsgChkConstant" BO_ 1376 101;
BA_ "GenMsgCycleTime" BO_ 1376 160;
BA_ "GenMsgILSupport" BO_ 1376 1;
BA_ "GenMsgPDUConstants" BO_ 1376 "0x65,0x65,0x65,0x65,0x65,0x65,0x65,0x65,0x65,0x65,0x65,0x65,0x65,0x65,0x65,0x65";
BA_ "GenMsgSendType" BO_ 1376 0;
BA_ "GenSigSendType" SG_ 1607 MO_CO2_Faktor 0;
BA_ "GenSigSwitchedByIgnition" SG_ 1607 MO_CO2_Faktor 0;
BA_ "Fehlerwert" SG_ 1607 MO_CO2_Faktor 4095;
BA_ "GenSigSendType" SG_ 1607 MO_E85_Sensor 0;
BA_ "GenSigStartValue" SG_ 1607 MO_E85_Sensor 14;
BA_ "GenSigSwitchedByIgnition" SG_ 1607 MO_E85_Sensor 0;
BA_ "Fehlerwert" SG_ 1607 MO_E85_Sensor 15;
BA_ "GenSigSendType" SG_ 1607 MO_Ethanol_Spuelhinweis 0;
BA_ "GenSigSwitchedByIgnition" SG_ 1607 MO_Ethanol_Spuelhinweis 0;
BA_ "GenSigSendType" SG_ 1607 MO_ITM_Kuehlmittel_Temp 0;
BA_ "GenSigStartValue" SG_ 1607 MO_ITM_Kuehlmittel_Temp 1;
BA_ "GenSigSwitchedByIgnition" SG_ 1607 MO_ITM_Kuehlmittel_Temp 0;
BA_ "Fehlerwert" SG_ 1607 MO_ITM_Kuehlmittel_Temp 2;
BA_ "GenSigSendType" SG_ 1607 MO_Kraftstofffilter_Wasser 0;
BA_ "GenSigSwitchedByIgnition" SG_ 1607 MO_Kraftstofffilter_Wasser 0;
BA_ "GenSigSwitchedByIgnition" SG_ 1607 MO_MKB_01 0;
BA_ "GenSigSwitchedByIgnition" SG_ 1607 MO_MKB_02 0;
BA_ "GenSigSwitchedByIgnition" SG_ 1607 MO_MKB_03 0;
BA_ "GenSigSwitchedByIgnition" SG_ 1607 MO_MKB_04 0;
BA_ "GenSigSendType" SG_ 1607 MO_MKB_MUX 0;
BA_ "GenSigSwitchedByIgnition" SG_ 1607 MO_MKB_MUX 0;
BA_ "GenSigSendType" SG_ 1607 SCR_Akustik 0;
BA_ "GenSigSwitchedByIgnition" SG_ 1607 SCR_Akustik 0;
BA_ "GenSigSendType" SG_ 1607 SCR_Anz_Motorstarts 0;
BA_ "GenSigStartValue" SG_ 1607 SCR_Anz_Motorstarts 15;
BA_ "GenSigSwitchedByIgnition" SG_ 1607 SCR_Anz_Motorstarts 0;
BA_ "GenSigSendType" SG_ 1607 SCR_Inducement_Strategie 0;
BA_ "GenSigSwitchedByIgnition" SG_ 1607 SCR_Inducement_Strategie 0;
BA_ "GenSigSendType" SG_ 1607 SCR_Reichweite 0;
BA_ "GenSigStartValue" SG_ 1607 SCR_Reichweite 32767;
BA_ "GenSigSwitchedByIgnition" SG_ 1607 SCR_Reichweite 0;
BA_ "GenSigSendType" SG_ 1607 SCR_Systemfehler 0;
BA_ "GenSigSwitchedByIgnition" SG_ 1607 SCR_Systemfehler 0;
BA_ "GenSigSendType" SG_ 1607 SCR_Text 0;
BA_ "GenSigSwitchedByIgnition" SG_ 1607 SCR_Text 0;
BA_ "GenSigSendType" SG_ 1607 SCR_verbaut 0;
BA_ "GenSigFuncType" SG_ 1607 SCR_verbaut 8;
BA_ "GenSigSwitchedByIgnition" SG_ 1607 SCR_verbaut 0;
BA_ "GenSigSendType" SG_ 1607 SCR_Warnstufe_1 0;
BA_ "GenSigSwitchedByIgnition" SG_ 1607 SCR_Warnstufe_1 0;
BA_ "GenSigSendType" SG_ 1607 SCR_Warnstufe_2 0;
BA_ "GenSigSwitchedByIgnition" SG_ 1607 SCR_Warnstufe_2 0;
BA_ "GenSigSendType" SG_ 168 MO_Drehzahl_01 0;
BA_ "GenSigSwitchedByIgnition" SG_ 168 MO_Drehzahl_01 0;
BA_ "GenSigSendType" SG_ 168 MO_Mom_Begr_dyn 0;
BA_ "GenSigStartValue" SG_ 168 MO_Mom_Begr_dyn 1022;
BA_ "GenSigSwitchedByIgnition" SG_ 168 MO_Mom_Begr_dyn 0;
BA_ "GenSigSendType" SG_ 168 MO_Mom_Begr_stat 0;
BA_ "GenSigStartValue" SG_ 168 MO_Mom_Begr_stat 510;
BA_ "GenSigSwitchedByIgnition" SG_ 168 MO_Mom_Begr_stat 0;
BA_ "GenSigSendType" SG_ 168 MO_Mom_neg_verfuegbar 0;
BA_ "GenSigStartValue" SG_ 168 MO_Mom_neg_verfuegbar 510;
BA_ "GenSigSwitchedByIgnition" SG_ 168 MO_Mom_neg_verfuegbar 0;
BA_ "Fehlerwert" SG_ 168 MO_Mom_neg_verfuegbar 511;
BA_ "GenSigSendType" SG_ 168 MO_Momentenintegral_02 0;
BA_ "GenSigSwitchedByIgnition" SG_ 168 MO_Momentenintegral_02 0;
BA_ "GenSigSendType" SG_ 168 MO_QBit_Drehzahl_01 0;
BA_ "GenSigStartValue" SG_ 168 MO_QBit_Drehzahl_01 1;
BA_ "GenSigSwitchedByIgnition" SG_ 168 MO_QBit_Drehzahl_01 0;
BA_ "GenSigSendType" SG_ 168 Motor_12_BZ 0;
BA_ "GenSigFuncType" SG_ 168 Motor_12_BZ 1;
BA_ "GenSigSwitchedByIgnition" SG_ 168 Motor_12_BZ 0;
BA_ "GenSigSendType" SG_ 168 Motor_12_CRC 0;
BA_ "GenSigFuncType" SG_ 168 Motor_12_CRC 2;
BA_ "GenSigSwitchedByIgnition" SG_ 168 Motor_12_CRC 0;
BA_ "GenSigSendType" SG_ 958 MO_Aussp_Anlass 3;
BA_ "GenSigSwitchedByIgnition" SG_ 958 MO_Aussp_Anlass 0;
BA_ "GenSigSendType" SG_ 958 MO_BKV_Unterdruckwarnung 0;
BA_ "GenSigSwitchedByIgnition" SG_ 958 MO_BKV_Unterdruckwarnung 0;
BA_ "GenSigSendType" SG_ 958 MO_BLS 3;
BA_ "GenSigSwitchedByIgnition" SG_ 958 MO_BLS 0;
BA_ "GenSigSendType" SG_ 958 MO_BMS_NV_Anf_stuetzen 3;
BA_ "GenSigSwitchedByIgnition" SG_ 958 MO_BMS_NV_Anf_stuetzen 0;
BA_ "GenSigSendType" SG_ 958 MO_EKlKomLeiRed 0;
BA_ "GenSigSwitchedByIgnition" SG_ 958 MO_EKlKomLeiRed 0;
BA_ "GenSigSendType" SG_ 958 MO_Ext_E_Fahrt_aktiv 3;
BA_ "NWM-WakeupAllowed" SG_ 958 MO_Ext_E_Fahrt_aktiv 1;
BA_ "GenSigSwitchedByIgnition" SG_ 958 MO_Ext_E_Fahrt_aktiv 0;
BA_ "GenSigSendType" SG_ 958 MO_Fahrer_bremst 3;
BA_ "GenSigSwitchedByIgnition" SG_ 958 MO_Fahrer_bremst 0;
BA_ "GenSigSendType" SG_ 958 MO_FMAus_aktiv 3;
BA_ "GenSigSwitchedByIgnition" SG_ 958 MO_FMAus_aktiv 0;
BA_ "GenSigSendType" SG_ 958 MO_FMAus_Startvariante 3;
BA_ "GenSigSwitchedByIgnition" SG_ 958 MO_FMAus_Startvariante 0;
BA_ "GenSigSendType" SG_ 958 MO_Freig_Anlass 3;
BA_ "GenSigSwitchedByIgnition" SG_ 958 MO_Freig_Anlass 0;
BA_ "GenSigSendType" SG_ 958 MO_Freig_Reku 0;
BA_ "GenSigSwitchedByIgnition" SG_ 958 MO_Freig_Reku 0;
BA_ "GenSigSendType" SG_ 958 MO_Freigabe_Segeln 0;
BA_ "GenSigSwitchedByIgnition" SG_ 958 MO_Freigabe_Segeln 0;
BA_ "GenSigSendType" SG_ 958 MO_Gangposition 3;
BA_ "GenSigStartValue" SG_ 958 MO_Gangposition 14;
BA_ "GenSigSwitchedByIgnition" SG_ 958 MO_Gangposition 0;
BA_ "Fehlerwert" SG_ 958 MO_Gangposition 15;
BA_ "GenSigSendType" SG_ 958 MO_Handshake_STH 0;
BA_ "GenSigSwitchedByIgnition" SG_ 958 MO_Handshake_STH 0;
BA_ "GenSigSendType" SG_ 958 MO_HYB_Fahrbereitschaft 0;
BA_ "GenSigSwitchedByIgnition" SG_ 958 MO_HYB_Fahrbereitschaft 0;
BA_ "GenSigSendType" SG_ 958 MO_HYB_VM_aktiv 3;
BA_ "GenSigSwitchedByIgnition" SG_ 958 MO_HYB_VM_aktiv 0;
BA_ "GenSigSendType" SG_ 958 MO_Interlock 3;
BA_ "GenSigSwitchedByIgnition" SG_ 958 MO_Interlock 0;
BA_ "GenSigSendType" SG_ 958 MO_Kickdown 3;
BA_ "GenSigSwitchedByIgnition" SG_ 958 MO_Kickdown 0;
BA_ "GenSigSendType" SG_ 958 MO_Kl_50 3;
BA_ "GenSigSwitchedByIgnition" SG_ 958 MO_Kl_50 0;
BA_ "GenSigSendType" SG_ 958 MO_Kl_75 3;
BA_ "GenSigSwitchedByIgnition" SG_ 958 MO_Kl_75 0;
BA_ "GenSigSendType" SG_ 958 MO_Klima_Eingr 0;
BA_ "GenSigSwitchedByIgnition" SG_ 958 MO_Klima_Eingr 0;
BA_ "GenSigSendType" SG_ 958 MO_KomFehler_ESP 3;
BA_ "GenSigSwitchedByIgnition" SG_ 958 MO_KomFehler_ESP 0;
BA_ "Fehlerwert" SG_ 958 MO_KomFehler_ESP 1;
BA_ "GenSigSendType" SG_ 958 MO_Konsistenz_Bremsped 3;
BA_ "GenSigSwitchedByIgnition" SG_ 958 MO_Konsistenz_Bremsped 0;
BA_ "GenSigSendType" SG_ 958 MO_Kuppl_schalter 3;
BA_ "GenSigSwitchedByIgnition" SG_ 958 MO_Kuppl_schalter 0;
BA_ "GenSigSendType" SG_ 958 MO_Motor_laeuft 3;
BA_ "GenSigSwitchedByIgnition" SG_ 958 MO_Motor_laeuft 0;
BA_ "GenSigSendType" SG_ 958 MO_PTC_Status 0;
BA_ "GenSigSwitchedByIgnition" SG_ 958 MO_PTC_Status 0;
BA_ "GenSigSendType" SG_ 958 MO_QBit_Fahrer_bremst 3;
BA_ "GenSigStartValue" SG_ 958 MO_QBit_Fahrer_bremst 1;
BA_ "GenSigSwitchedByIgnition" SG_ 958 MO_QBit_Fahrer_bremst 0;
BA_ "GenSigSendType" SG_ 958 MO_QBit_Gangposition 3;
BA_ "GenSigStartValue" SG_ 958 MO_QBit_Gangposition 1;
BA_ "GenSigSwitchedByIgnition" SG_ 958 MO_QBit_Gangposition 0;
BA_ "GenSigSendType" SG_ 958 MO_QBit_KL_75 3;
BA_ "GenSigStartValue" SG_ 958 MO_QBit_KL_75 1;
BA_ "GenSigSwitchedByIgnition" SG_ 958 MO_QBit_KL_75 0;
BA_ "GenSigSendType" SG_ 958 MO_Remotestart_Betrieb 3;
BA_ "GenSigSwitchedByIgnition" SG_ 958 MO_Remotestart_Betrieb 0;
BA_ "GenSigSendType" SG_ 958 MO_Remotestart_moeglich 0;
BA_ "GenSigSwitchedByIgnition" SG_ 958 MO_Remotestart_moeglich 0;
BA_ "GenSigSendType" SG_ 958 MO_Signalquelle_Gangposition 0;
BA_ "GenSigSwitchedByIgnition" SG_ 958 MO_Signalquelle_Gangposition 0;
BA_ "GenSigSendType" SG_ 958 MO_StartStopp_Fahrerwunsch 0;
BA_ "GenSigSwitchedByIgnition" SG_ 958 MO_StartStopp_Fahrerwunsch 0;
BA_ "GenSigSendType" SG_ 958 MO_StartStopp_Motorstopp 3;
BA_ "GenSigSwitchedByIgnition" SG_ 958 MO_StartStopp_Motorstopp 0;
BA_ "GenSigSendType" SG_ 958 MO_StartStopp_Status 3;
BA_ "GenSigSwitchedByIgnition" SG_ 958 MO_StartStopp_Status 0;
BA_ "GenSigSendType" SG_ 958 MO_StartStopp_Wiederstart 3;
BA_ "GenSigSwitchedByIgnition" SG_ 958 MO_StartStopp_Wiederstart 0;
BA_ "GenSigSendType" SG_ 958 MO_StartVorauss_erfuellt 3;
BA_ "GenSigStartValue" SG_ 958 MO_StartVorauss_erfuellt 1;
BA_ "GenSigSwitchedByIgnition" SG_ 958 MO_StartVorauss_erfuellt 0;
BA_ "GenSigSendType" SG_ 958 MO_Text_Geschw_red 0;
BA_ "GenSigSwitchedByIgnition" SG_ 958 MO_Text_Geschw_red 0;
BA_ "GenSigSendType" SG_ 958 MO_Zylinderabschaltung 3;
BA_ "GenSigSwitchedByIgnition" SG_ 958 MO_Zylinderabschaltung 0;
BA_ "GenSigSendType" SG_ 958 Motor_14_BZ 0;
BA_ "GenSigFuncType" SG_ 958 Motor_14_BZ 1;
BA_ "GenSigSwitchedByIgnition" SG_ 958 Motor_14_BZ 0;
BA_ "GenSigSendType" SG_ 958 Motor_14_CRC 0;
BA_ "GenSigFuncType" SG_ 958 Motor_14_CRC 2;
BA_ "GenSigSwitchedByIgnition" SG_ 958 Motor_14_CRC 0;
BA_ "GenSigSendType" SG_ 1631 MO_Anzeige_Kaltleuchte 0;
BA_ "GenSigSwitchedByIgnition" SG_ 1631 MO_Anzeige_Kaltleuchte 0;
BA_ "GenSigSendType" SG_ 1631 MO_DPF_reg 0;
BA_ "GenSigSwitchedByIgnition" SG_ 1631 MO_DPF_reg 0;
BA_ "GenSigSendType" SG_ 1631 MO_Energieinhalt_BMS 0;
BA_ "GenSigStartValue" SG_ 1631 MO_Energieinhalt_BMS 4094;
BA_ "GenSigSwitchedByIgnition" SG_ 1631 MO_Energieinhalt_BMS 0;
BA_ "Fehlerwert" SG_ 1631 MO_Energieinhalt_BMS 4095;
BA_ "GenSigSendType" SG_ 1631 MO_Heizstrom_EKAT 0;
BA_ "GenSigSwitchedByIgnition" SG_ 1631 MO_Heizstrom_EKAT 0;
BA_ "Fehlerwert" SG_ 1631 MO_Heizstrom_EKAT 127;
BA_ "GenSigSendType" SG_ 1631 MO_Heizstrom_SCR 0;
BA_ "GenSigSwitchedByIgnition" SG_ 1631 MO_Heizstrom_SCR 0;
BA_ "Fehlerwert" SG_ 1631 MO_Heizstrom_SCR 63;
BA_ "GenSigSendType" SG_ 1631 MO_P_Generator_ungefiltert_Anf 0;
BA_ "GenSigSwitchedByIgnition" SG_ 1631 MO_P_Generator_ungefiltert_Anf 0;
BA_ "GenSigSendType" SG_ 1631 MO_SpannungsAnf_02 0;
BA_ "GenSigSwitchedByIgnition" SG_ 1631 MO_SpannungsAnf_02 0;
BA_ "GenSigSendType" SG_ 1631 TSK_Fahrzeugmasse_02 0;
BA_ "GenSigSwitchedByIgnition" SG_ 1631 TSK_Fahrzeugmasse_02 0;
BA_ "Fehlerwert" SG_ 1631 TSK_Fahrzeugmasse_02 255;
BA_ "GenSigSendType" SG_ 1631 TSK_Getriebeinfo 0;
BA_ "GenSigSwitchedByIgnition" SG_ 1631 TSK_Getriebeinfo 0;
BA_ "GenSigSendType" SG_ 1631 TSK_Grundmasse 0;
BA_ "GenSigSwitchedByIgnition" SG_ 1631 TSK_Grundmasse 0;
BA_ "GenSigSendType" SG_ 1631 TSK_QBit_Fahrzeugmasse 0;
BA_ "GenSigStartValue" SG_ 1631 TSK_QBit_Fahrzeugmasse 1;
BA_ "GenSigSwitchedByIgnition" SG_ 1631 TSK_QBit_Fahrzeugmasse 0;
BA_ "GenSigSendType" SG_ 1631 TSK_QBit_Steigung 0;
BA_ "GenSigStartValue" SG_ 1631 TSK_QBit_Steigung 1;
BA_ "GenSigSwitchedByIgnition" SG_ 1631 TSK_QBit_Steigung 0;
BA_ "GenSigSendType" SG_ 1631 TSK_Steigung_02 0;
BA_ "GenSigSwitchedByIgnition" SG_ 1631 TSK_Steigung_02 0;
BA_ "Fehlerwert" SG_ 1631 TSK_Steigung_02 255;
BA_ "GenSigSendType" SG_ 812 MO_BZS_Charisma_FahrPr 3;
BA_ "GenSigSwitchedByIgnition" SG_ 812 MO_BZS_Charisma_FahrPr 0;
BA_ "GenSigSendType" SG_ 812 MO_BZS_Charisma_Status 0;
BA_ "GenSigSwitchedByIgnition" SG_ 812 MO_BZS_Charisma_Status 0;
BA_ "GenSigSendType" SG_ 812 MO_Charisma_FahrPr 0;
BA_ "GenSigSwitchedByIgnition" SG_ 812 MO_Charisma_FahrPr 0;
BA_ "GenSigSendType" SG_ 812 MO_Charisma_Status 0;
BA_ "GenSigSwitchedByIgnition" SG_ 812 MO_Charisma_Status 0;
BA_ "GenSigSendType" SG_ 812 MO_Drehzahlbeeinflussung 0;
BA_ "GenSigSwitchedByIgnition" SG_ 812 MO_Drehzahlbeeinflussung 0;
BA_ "GenSigSendType" SG_ 812 MO_Luftpfad_aktiv 0;
BA_ "GenSigSwitchedByIgnition" SG_ 812 MO_Luftpfad_aktiv 0;
BA_ "GenSigSendType" SG_ 812 MO_MAX_Wunschdrehzahl 3;
BA_ "GenSigSwitchedByIgnition" SG_ 812 MO_MAX_Wunschdrehzahl 0;
BA_ "GenSigSendType" SG_ 812 MO_MIN_Wunschdrehzahl 0;
BA_ "GenSigSwitchedByIgnition" SG_ 812 MO_MIN_Wunschdrehzahl 0;
BA_ "GenSigSendType" SG_ 812 MO_NGS_Position 0;
BA_ "GenSigSwitchedByIgnition" SG_ 812 MO_NGS_Position 0;
BA_ "GenSigSendType" SG_ 812 MO_NGS_Status 0;
BA_ "GenSigSwitchedByIgnition" SG_ 812 MO_NGS_Status 0;
BA_ "Fehlerwert" SG_ 812 MO_NGS_Status 3;
BA_ "GenSigSendType" SG_ 812 MO_Prio_MAX_Wunschdrehzahl 3;
BA_ "GenSigSwitchedByIgnition" SG_ 812 MO_Prio_MAX_Wunschdrehzahl 0;
BA_ "GenSigSendType" SG_ 812 MO_Prio_MIN_Wunschdrehzahl 0;
BA_ "GenSigSwitchedByIgnition" SG_ 812 MO_Prio_MIN_Wunschdrehzahl 0;
BA_ "GenSigSendType" SG_ 812 MO_Rampenzeit_Generator_Anf 0;
BA_ "GenSigStartValue" SG_ 812 MO_Rampenzeit_Generator_Anf 15;
BA_ "GenSigSwitchedByIgnition" SG_ 812 MO_Rampenzeit_Generator_Anf 0;
BA_ "GenSigSendType" SG_ 812 MO_Sperrung_FahrPr_BZS 0;
BA_ "GenSigSwitchedByIgnition" SG_ 812 MO_Sperrung_FahrPr_BZS 0;
BA_ "GenSigSendType" SG_ 812 MO_StSt_Charisma_FahrPr 0;
BA_ "GenSigSwitchedByIgnition" SG_ 812 MO_StSt_Charisma_FahrPr 0;
BA_ "GenSigSendType" SG_ 812 MO_StSt_Charisma_Status 0;
BA_ "GenSigSwitchedByIgnition" SG_ 812 MO_StSt_Charisma_Status 0;
BA_ "GenSigSendType" SG_ 812 MO_v_Begrenz_Aktivierbar 0;
BA_ "GenSigSwitchedByIgnition" SG_ 812 MO_v_Begrenz_Aktivierbar 0;
BA_ "GenSigSendType" SG_ 812 MO_v_Begrenzung_Niveau 0;
BA_ "GenSigSwitchedByIgnition" SG_ 812 MO_v_Begrenzung_Niveau 0;
BA_ "GenSigSendType" SG_ 1648 MO1_Freigabe_Info_WFS 3;
BA_ "GenSigSwitchedByIgnition" SG_ 1648 MO1_Freigabe_Info_WFS 0;
BA_ "GenSigSendType" SG_ 1648 MO1_Freigabe_Verfallsinfo_WFS 3;
BA_ "GenSigSwitchedByIgnition" SG_ 1648 MO1_Freigabe_Verfallsinfo_WFS 0;
BA_ "GenSigSendType" SG_ 1648 MO1_Sperr_Info_WFS 3;
BA_ "GenSigSwitchedByIgnition" SG_ 1648 MO1_Sperr_Info_WFS 0;
BA_ "GenSigSendType" SG_ 1648 MO_Abstellzeit 0;
BA_ "GenSigStartValue" SG_ 1648 MO_Abstellzeit 254;
BA_ "GenSigSwitchedByIgnition" SG_ 1648 MO_Abstellzeit 0;
BA_ "GenSigSendType" SG_ 1648 MO_Abstellzeit_Status 0;
BA_ "GenSigSwitchedByIgnition" SG_ 1648 MO_Abstellzeit_Status 0;
BA_ "GenSigSendType" SG_ 1648 MO_ANC_Kennfeld_Anf 3;
BA_ "GenSigSwitchedByIgnition" SG_ 1648 MO_ANC_Kennfeld_Anf 0;
BA_ "GenSigSendType" SG_ 1648 MO_Anzahl_Abgesch_Zyl 3;
BA_ "GenSigSwitchedByIgnition" SG_ 1648 MO_Anzahl_Abgesch_Zyl 0;
BA_ "GenSigSendType" SG_ 1648 MO_Bremslicht_Reku 3;
BA_ "GenSigSwitchedByIgnition" SG_ 1648 MO_Bremslicht_Reku 0;
BA_ "GenSigSendType" SG_ 1648 MO_Drehzahl_Warnung 0;
BA_ "GenSigSwitchedByIgnition" SG_ 1648 MO_Drehzahl_Warnung 0;
BA_ "GenSigSendType" SG_ 1648 MO_EPCL 0;
BA_ "GenSigSwitchedByIgnition" SG_ 1648 MO_EPCL 0;
BA_ "GenSigSendType" SG_ 1648 MO_Ethanol_BS_Texte 0;
BA_ "GenSigSwitchedByIgnition" SG_ 1648 MO_Ethanol_BS_Texte 0;
BA_ "GenSigSendType" SG_ 1648 MO_Fahrzeugtyp 0;
BA_ "GenSigFuncType" SG_ 1648 MO_Fahrzeugtyp 8;
BA_ "GenSigSwitchedByIgnition" SG_ 1648 MO_Fahrzeugtyp 0;
BA_ "GenSigSendType" SG_ 1648 MO_Fehler_Zylabsch 0;
BA_ "GenSigSwitchedByIgnition" SG_ 1648 MO_Fehler_Zylabsch 0;
BA_ "GenSigSendType" SG_ 1648 MO_Hybrid_StartStopp_LED 3;
BA_ "GenSigSwitchedByIgnition" SG_ 1648 MO_Hybrid_StartStopp_LED 0;
BA_ "GenSigSendType" SG_ 1648 MO_max_Ladedruck 0;
BA_ "GenSigFuncType" SG_ 1648 MO_max_Ladedruck 8;
BA_ "GenSigSwitchedByIgnition" SG_ 1648 MO_max_Ladedruck 0;
BA_ "GenSigSendType" SG_ 1648 MO_NMAX_Schaltanzeige 3;
BA_ "GenSigSwitchedByIgnition" SG_ 1648 MO_NMAX_Schaltanzeige 0;
BA_ "GenSigSendType" SG_ 1648 MO_obere_Drehzahlgrenze 0;
BA_ "GenSigSwitchedByIgnition" SG_ 1648 MO_obere_Drehzahlgrenze 0;
BA_ "GenSigSendType" SG_ 1648 MO_StartStopp_PopUp 3;
BA_ "GenSigSwitchedByIgnition" SG_ 1648 MO_StartStopp_PopUp 0;
BA_ "GenSigSendType" SG_ 1648 MO_Zylabsch_Texte 0;
BA_ "GenSigSwitchedByIgnition" SG_ 1648 MO_Zylabsch_Texte 0;
BA_ "GenSigSendType" SG_ 1648 MO_Zylabsch_Texte_02 3;
BA_ "GenSigSwitchedByIgnition" SG_ 1648 MO_Zylabsch_Texte_02 0;
BA_ "GenSigSendType" SG_ 815 MO_Antriebsstrang_Warnung_HS 0;
BA_ "GenSigSwitchedByIgnition" SG_ 815 MO_Antriebsstrang_Warnung_HS 0;
BA_ "GenSigSendType" SG_ 815 MO_Anzeige_Betriebsmodus 0;
BA_ "GenSigSwitchedByIgnition" SG_ 815 MO_Anzeige_Betriebsmodus 0;
BA_ "GenSigSendType" SG_ 815 MO_Anzeige_Fahrbereitschaft 0;
BA_ "GenSigSwitchedByIgnition" SG_ 815 MO_Anzeige_Fahrbereitschaft 0;
BA_ "GenSigSendType" SG_ 815 MO_Anzeige_Rekuperation 0;
BA_ "GenSigSwitchedByIgnition" SG_ 815 MO_Anzeige_Rekuperation 0;
BA_ "GenSigSendType" SG_ 815 MO_Anzeige_Verbrauch_oE 0;
BA_ "GenSigSwitchedByIgnition" SG_ 815 MO_Anzeige_Verbrauch_oE 0;
BA_ "GenSigSendType" SG_ 815 MO_Boost_aktiv 0;
BA_ "GenSigSwitchedByIgnition" SG_ 815 MO_Boost_aktiv 0;
BA_ "GenSigSendType" SG_ 815 MO_Boost_verfuegbar 0;
BA_ "GenSigSwitchedByIgnition" SG_ 815 MO_Boost_verfuegbar 0;
BA_ "Fehlerwert" SG_ 815 MO_Boost_verfuegbar 255;
BA_ "GenSigSendType" SG_ 815 MO_Overboost 0;
BA_ "GenSigSwitchedByIgnition" SG_ 815 MO_Overboost 0;
BA_ "GenSigSendType" SG_ 815 PEA_Abschalttexte 0;
BA_ "GenSigSwitchedByIgnition" SG_ 815 PEA_Abschalttexte 0;
BA_ "GenSigSendType" SG_ 815 PEA_Ereignisanzeige 0;
BA_ "GenSigSwitchedByIgnition" SG_ 815 PEA_Ereignisanzeige 0;
BA_ "GenSigSendType" SG_ 815 PEA_Ereignisanzeige_temporaer 0;
BA_ "GenSigSwitchedByIgnition" SG_ 815 PEA_Ereignisanzeige_temporaer 0;
BA_ "GenSigSendType" SG_ 815 PEA_Fortschrittsanzeige 0;
BA_ "GenSigStartValue" SG_ 815 PEA_Fortschrittsanzeige 127;
BA_ "GenSigSwitchedByIgnition" SG_ 815 PEA_Fortschrittsanzeige 0;
BA_ "GenSigSendType" SG_ 815 PEA_Hinweis 0;
BA_ "GenSigSwitchedByIgnition" SG_ 815 PEA_Hinweis 0;
BA_ "GenSigSendType" SG_ 815 PEA_Zielgeschw 0;
BA_ "GenSigSwitchedByIgnition" SG_ 815 PEA_Zielgeschw 0;
BA_ "GenSigSendType" SG_ 815 PEA_Zielgeschw_Einheit 0;
BA_ "GenSigSwitchedByIgnition" SG_ 815 PEA_Zielgeschw_Einheit 0;
BA_ "GenSigSendType" SG_ 1391 MO_Anzeige_Aufheizfortschritt 0;
BA_ "GenSigStartValue" SG_ 1391 MO_Anzeige_Aufheizfortschritt 126;
BA_ "GenSigSwitchedByIgnition" SG_ 1391 MO_Anzeige_Aufheizfortschritt 0;
BA_ "Fehlerwert" SG_ 1391 MO_Anzeige_Aufheizfortschritt 127;
BA_ "GenSigSendType" SG_ 1391 MO_Anzeige_Drehmoment_Max 0;
BA_ "GenSigSwitchedByIgnition" SG_ 1391 MO_Anzeige_Drehmoment_Max 0;
BA_ "GenSigSendType" SG_ 1391 MO_Anzeige_Leistung_Max 0;
BA_ "GenSigSwitchedByIgnition" SG_ 1391 MO_Anzeige_Leistung_Max 0;
BA_ "GenSigSendType" SG_ 1391 MO_HYB_Drehzahl_VM 0;
BA_ "GenSigSwitchedByIgnition" SG_ 1391 MO_HYB_Drehzahl_VM 0;
BA_ "Fehlerwert" SG_ 1391 MO_HYB_Drehzahl_VM 65280;
BA_ "GenSigSendType" SG_ 1391 MO_IstLeistung_EKAT 0;
BA_ "GenSigStartValue" SG_ 1391 MO_IstLeistung_EKAT 126;
BA_ "GenSigSwitchedByIgnition" SG_ 1391 MO_IstLeistung_EKAT 0;
BA_ "Fehlerwert" SG_ 1391 MO_IstLeistung_EKAT 127;
BA_ "GenSigSendType" SG_ 967 MO_E_Mode 0;
BA_ "GenSigSwitchedByIgnition" SG_ 967 MO_E_Mode 0;
BA_ "GenSigSendType" SG_ 967 MO_E_Texte 0;
BA_ "GenSigSwitchedByIgnition" SG_ 967 MO_E_Texte 0;
BA_ "GenSigSendType" SG_ 967 MO_E_Warnungen 0;
BA_ "GenSigSwitchedByIgnition" SG_ 967 MO_E_Warnungen 0;
BA_ "GenSigSendType" SG_ 967 MO_EFLEX_Lampe 0;
BA_ "GenSigSwitchedByIgnition" SG_ 967 MO_EFLEX_Lampe 0;
BA_ "GenSigSendType" SG_ 967 MO_Heissleuchte 0;
BA_ "GenSigSwitchedByIgnition" SG_ 967 MO_Heissleuchte 0;
BA_ "GenSigSendType" SG_ 967 MO_ITM_Warnung_Pumpe 0;
BA_ "GenSigSwitchedByIgnition" SG_ 967 MO_ITM_Warnung_Pumpe 0;
BA_ "GenSigSendType" SG_ 967 MO_KJS_nicht_bereit 0;
BA_ "GenSigSwitchedByIgnition" SG_ 967 MO_KJS_nicht_bereit 0;
BA_ "Fehlerwert" SG_ 967 MO_KJS_nicht_bereit 1;
BA_ "GenSigStartValue" SG_ 967 MO_Kuehlerluefter_1 126;
BA_ "GenSigSwitchedByIgnition" SG_ 967 MO_Kuehlerluefter_1 0;
BA_ "Fehlerwert" SG_ 967 MO_Kuehlerluefter_1 127;
BA_ "GenSigStartValue" SG_ 967 MO_Kuehlerluefter_2 126;
BA_ "GenSigSwitchedByIgnition" SG_ 967 MO_Kuehlerluefter_2 0;
BA_ "Fehlerwert" SG_ 967 MO_Kuehlerluefter_2 127;
BA_ "GenSigSendType" SG_ 967 MO_Kuehlerluefter_MUX 0;
BA_ "GenSigSwitchedByIgnition" SG_ 967 MO_Kuehlerluefter_MUX 0;
BA_ "GenSigSendType" SG_ 967 MO_OBD2_Lampe 0;
BA_ "GenSigSwitchedByIgnition" SG_ 967 MO_OBD2_Lampe 0;
BA_ "GenSigSendType" SG_ 967 MO_Oelwarnung_max 0;
BA_ "GenSigSwitchedByIgnition" SG_ 967 MO_Oelwarnung_max 0;
BA_ "GenSigSendType" SG_ 967 MO_Partikel_Lampe 0;
BA_ "GenSigSwitchedByIgnition" SG_ 967 MO_Partikel_Lampe 0;
BA_ "GenSigSendType" SG_ 967 MO_RedFahrleistung_Lampe 0;
BA_ "GenSigSwitchedByIgnition" SG_ 967 MO_RedFahrleistung_Lampe 0;
BA_ "GenSigSendType" SG_ 967 MO_Systemlampe 0;
BA_ "GenSigSwitchedByIgnition" SG_ 967 MO_Systemlampe 0;
BA_ "GenSigSendType" SG_ 967 MO_Tankdeckel_Lampe 0;
BA_ "GenSigSwitchedByIgnition" SG_ 967 MO_Tankdeckel_Lampe 0;
BA_ "GenSigSendType" SG_ 967 MO_Text_Motorstart 0;
BA_ "GenSigSwitchedByIgnition" SG_ 967 MO_Text_Motorstart 0;
BA_ "GenSigSendType" SG_ 967 MO_Text_Partikelfil_Reg 0;
BA_ "GenSigSwitchedByIgnition" SG_ 967 MO_Text_Partikelfil_Reg 0;
BA_ "GenSigSendType" SG_ 967 MO_Text_Tankdeckelwarn 0;
BA_ "GenSigSwitchedByIgnition" SG_ 967 MO_Text_Tankdeckelwarn 0;
BA_ "GenSigSendType" SG_ 967 MO_Vorglueh_Lampe 0;
BA_ "GenSigSwitchedByIgnition" SG_ 967 MO_Vorglueh_Lampe 0;
BA_ "GenSigSendType" SG_ 967 MO_Zustand_HWP 0;
BA_ "GenSigStartValue" SG_ 967 MO_Zustand_HWP 1;
BA_ "GenSigSwitchedByIgnition" SG_ 967 MO_Zustand_HWP 0;
BA_ "GenSigSendType" SG_ 967 OLEV_Oelstand_nicht_vorhanden 0;
BA_ "GenSigSwitchedByIgnition" SG_ 967 OLEV_Oelstand_nicht_vorhanden 0;
BA_ "GenSigSendType" SG_ 967 OLEV_Systemstoerung 0;
BA_ "GenSigSwitchedByIgnition" SG_ 967 OLEV_Systemstoerung 0;
BA_ "GenSigSendType" SG_ 967 WIV_Anzeige_aktiv 0;
BA_ "GenSigSwitchedByIgnition" SG_ 967 WIV_Anzeige_aktiv 0;
BA_ "GenSigSendType" SG_ 967 WIV_laufender_Motor 0;
BA_ "GenSigSwitchedByIgnition" SG_ 967 WIV_laufender_Motor 0;
BA_ "GenSigSendType" SG_ 967 WIV_nachfuellanzeige_ein 0;
BA_ "GenSigSwitchedByIgnition" SG_ 967 WIV_nachfuellanzeige_ein 0;
BA_ "GenSigSendType" SG_ 967 WIV_nicht_betriebswarm 0;
BA_ "GenSigSwitchedByIgnition" SG_ 967 WIV_nicht_betriebswarm 0;
BA_ "GenSigSendType" SG_ 967 WIV_Oeldr_Warn_Motor 0;
BA_ "GenSigSwitchedByIgnition" SG_ 967 WIV_Oeldr_Warn_Motor 0;
BA_ "GenSigSendType" SG_ 967 WIV_Oeldyn_avl 0;
BA_ "GenSigSwitchedByIgnition" SG_ 967 WIV_Oeldyn_avl 0;
BA_ "GenSigSendType" SG_ 967 WIV_Oelmenge 0;
BA_ "GenSigSwitchedByIgnition" SG_ 967 WIV_Oelmenge 0;
BA_ "GenSigSendType" SG_ 967 WIV_Oelmin_Warn 0;
BA_ "GenSigSwitchedByIgnition" SG_ 967 WIV_Oelmin_Warn 0;
BA_ "GenSigSendType" SG_ 967 WIV_Oelstand 0;
BA_ "GenSigSwitchedByIgnition" SG_ 967 WIV_Oelstand 0;
BA_ "GenSigSendType" SG_ 967 WIV_Oelstand_nicht_vorhanden 0;
BA_ "GenSigSwitchedByIgnition" SG_ 967 WIV_Oelstand_nicht_vorhanden 0;
BA_ "GenSigSendType" SG_ 967 WIV_Oelsystem_aktiv 0;
BA_ "GenSigSwitchedByIgnition" SG_ 967 WIV_Oelsystem_aktiv 0;
BA_ "GenSigSendType" SG_ 967 WIV_Schieflage 0;
BA_ "GenSigSwitchedByIgnition" SG_ 967 WIV_Schieflage 0;
BA_ "GenSigSendType" SG_ 967 WIV_Sensorfehler 0;
BA_ "GenSigSwitchedByIgnition" SG_ 967 WIV_Sensorfehler 0;
BA_ "GenSigSendType" SG_ 967 WIV_Ueberfuell_deaktiv 0;
BA_ "GenSigSwitchedByIgnition" SG_ 967 WIV_Ueberfuell_deaktiv 0;
BA_ "GenSigSendType" SG_ 967 WIV_Ueberfuell_Warn 0;
BA_ "GenSigSwitchedByIgnition" SG_ 967 WIV_Ueberfuell_Warn 0;
BA_ "GenSigSendType" SG_ 967 WIV_Unterfuell_Warn 0;
BA_ "GenSigSwitchedByIgnition" SG_ 967 WIV_Unterfuell_Warn 0;
BA_ "GenSigSendType" SG_ 327 MO_Anzeige_Drehmoment 0;
BA_ "GenSigSwitchedByIgnition" SG_ 327 MO_Anzeige_Drehmoment 0;
BA_ "Fehlerwert" SG_ 327 MO_Anzeige_Drehmoment 2047;
BA_ "GenSigSendType" SG_ 327 MO_Anzeige_Kaltabfahrbegrenzung 0;
BA_ "GenSigStartValue" SG_ 327 MO_Anzeige_Kaltabfahrbegrenzung 6;
BA_ "GenSigSwitchedByIgnition" SG_ 327 MO_Anzeige_Kaltabfahrbegrenzung 0;
BA_ "GenSigSendType" SG_ 327 MO_Anzeige_Leistung 0;
BA_ "GenSigSwitchedByIgnition" SG_ 327 MO_Anzeige_Leistung 0;
BA_ "Fehlerwert" SG_ 327 MO_Anzeige_Leistung 2047;
BA_ "GenSigSendType" SG_ 327 MO_Anzeige_Verbr_Einheit 0;
BA_ "GenSigSwitchedByIgnition" SG_ 327 MO_Anzeige_Verbr_Einheit 0;
BA_ "GenSigSendType" SG_ 327 MO_eATL_Status_Anzeige 0;
BA_ "GenSigSwitchedByIgnition" SG_ 327 MO_eATL_Status_Anzeige 0;
BA_ "Fehlerwert" SG_ 327 MO_eATL_Status_Anzeige 3;
BA_ "GenSigSendType" SG_ 327 MO_EM1_SumRadMomReku_Ist 0;
BA_ "GenSigSwitchedByIgnition" SG_ 327 MO_EM1_SumRadMomReku_Ist 0;
BA_ "Fehlerwert" SG_ 327 MO_EM1_SumRadMomReku_Ist 255;
BA_ "GenSigSendType" SG_ 327 MO_Hochschaltdrehz 0;
BA_ "GenSigSwitchedByIgnition" SG_ 327 MO_Hochschaltdrehz 0;
BA_ "Fehlerwert" SG_ 327 MO_Hochschaltdrehz 4095;
BA_ "GenSigSendType" SG_ 327 MO_Schaltblitz_Anz 0;
BA_ "GenSigStartValue" SG_ 327 MO_Schaltblitz_Anz 126;
BA_ "GenSigSwitchedByIgnition" SG_ 327 MO_Schaltblitz_Anz 0;
BA_ "Fehlerwert" SG_ 327 MO_Schaltblitz_Anz 127;
BA_ "GenSigSendType" SG_ 1366 FWS_Koeffizient_2 0;
BA_ "GenSigStartValue" SG_ 1366 FWS_Koeffizient_2 254;
BA_ "GenSigSwitchedByIgnition" SG_ 1366 FWS_Koeffizient_2 0;
BA_ "Fehlerwert" SG_ 1366 FWS_Koeffizient_2 255;
BA_ "GenSigSendType" SG_ 1366 FWS_QBit_Koeffizient_2 0;
BA_ "GenSigStartValue" SG_ 1366 FWS_QBit_Koeffizient_2 1;
BA_ "GenSigSwitchedByIgnition" SG_ 1366 FWS_QBit_Koeffizient_2 0;
BA_ "GenSigSendType" SG_ 1366 MO_Fahrzeugabstellzeit 0;
BA_ "GenSigStartValue" SG_ 1366 MO_Fahrzeugabstellzeit 254;
BA_ "GenSigSwitchedByIgnition" SG_ 1366 MO_Fahrzeugabstellzeit 0;
BA_ "Fehlerwert" SG_ 1366 MO_Fahrzeugabstellzeit 255;
BA_ "GenSigSendType" SG_ 1366 MO_Fahrzeugabstellzeit_Status 0;
BA_ "GenSigSwitchedByIgnition" SG_ 1366 MO_Fahrzeugabstellzeit_Status 0;
BA_ "GenSigSendType" SG_ 1366 MO_HV_Auszeit 0;
BA_ "GenSigStartValue" SG_ 1366 MO_HV_Auszeit 510;
BA_ "GenSigSwitchedByIgnition" SG_ 1366 MO_HV_Auszeit 0;
BA_ "Fehlerwert" SG_ 1366 MO_HV_Auszeit 511;
BA_ "GenSigSendType" SG_ 1366 MO_HV_Auszeit_Status 0;
BA_ "GenSigSwitchedByIgnition" SG_ 1366 MO_HV_Auszeit_Status 0;
BA_ "GenSigSendType" SG_ 1366 MO_Oelstand_Sens_roh 0;
BA_ "GenSigSwitchedByIgnition" SG_ 1366 MO_Oelstand_Sens_roh 0;
BA_ "GenSigSendType" SG_ 1366 MO_Verbau_StartSys_EM_HV 0;
BA_ "GenSigSwitchedByIgnition" SG_ 1366 MO_Verbau_StartSys_EM_HV 0;
BA_ "GenSigSendType" SG_ 1366 MO_Verbau_StartSys_EM_MV 0;
BA_ "GenSigSwitchedByIgnition" SG_ 1366 MO_Verbau_StartSys_EM_MV 0;
BA_ "GenSigSendType" SG_ 1366 MO_Verbau_StartSys_Q_Diode 0;
BA_ "GenSigSwitchedByIgnition" SG_ 1366 MO_Verbau_StartSys_Q_Diode 0;
BA_ "GenSigSendType" SG_ 1366 MO_Verbau_StartSys_Ritzelstarter 0;
BA_ "GenSigSwitchedByIgnition" SG_ 1366 MO_Verbau_StartSys_Ritzelstarter 0;
BA_ "GenSigSendType" SG_ 1366 MO_Verbau_StartSys_RSG_MV 0;
BA_ "GenSigSwitchedByIgnition" SG_ 1366 MO_Verbau_StartSys_RSG_MV 0;
BA_ "GenSigSendType" SG_ 1366 MO_Verbau_StartSys_RSG_NV 0;
BA_ "GenSigSwitchedByIgnition" SG_ 1366 MO_Verbau_StartSys_RSG_NV 0;
BA_ "GenSigSendType" SG_ 1366 MO_Ziel_SoC_Fremdladung 0;
BA_ "GenSigStartValue" SG_ 1366 MO_Ziel_SoC_Fremdladung 254;
BA_ "GenSigSwitchedByIgnition" SG_ 1366 MO_Ziel_SoC_Fremdladung 0;
BA_ "GenSigSendType" SG_ 283 MO_AIAD_MaxLeistung 0;
BA_ "GenSigStartValue" SG_ 283 MO_AIAD_MaxLeistung 255;
BA_ "GenSigSwitchedByIgnition" SG_ 283 MO_AIAD_MaxLeistung 0;
BA_ "GenSigSendType" SG_ 283 MO_EBoost_verf_praed 0;
BA_ "GenSigSwitchedByIgnition" SG_ 283 MO_EBoost_verf_praed 0;
BA_ "GenSigSendType" SG_ 283 MO_eLaunch_verf 0;
BA_ "GenSigSwitchedByIgnition" SG_ 283 MO_eLaunch_verf 0;
BA_ "GenSigSendType" SG_ 283 MO_Fahrbereitschaft 3;
BA_ "GenSigSwitchedByIgnition" SG_ 283 MO_Fahrbereitschaft 0;
BA_ "GenSigSendType" SG_ 283 MO_Freilauf_Info 0;
BA_ "GenSigSwitchedByIgnition" SG_ 283 MO_Freilauf_Info 0;
BA_ "GenSigSendType" SG_ 283 MO_Freilauf_Status 3;
BA_ "GenSigSwitchedByIgnition" SG_ 283 MO_Freilauf_Status 0;
BA_ "Fehlerwert" SG_ 283 MO_Freilauf_Status 7;
BA_ "GenSigSendType" SG_ 283 MO_Heckspoiler_Anf 3;
BA_ "GenSigSwitchedByIgnition" SG_ 283 MO_Heckspoiler_Anf 0;
BA_ "GenSigSendType" SG_ 283 MO_Krit_Heckobjekt 0;
BA_ "GenSigSwitchedByIgnition" SG_ 283 MO_Krit_Heckobjekt 0;
BA_ "Fehlerwert" SG_ 283 MO_Krit_Heckobjekt 7;
BA_ "GenSigSendType" SG_ 283 MO_NGS_Gangpos 0;
BA_ "GenSigSwitchedByIgnition" SG_ 283 MO_NGS_Gangpos 0;
BA_ "Fehlerwert" SG_ 283 MO_NGS_Gangpos 7;
BA_ "GenSigSendType" SG_ 283 MO_Parken_WFS_Status 0;
BA_ "GenSigSwitchedByIgnition" SG_ 283 MO_Parken_WFS_Status 0;
BA_ "GenSigSendType" SG_ 283 MO_Positionierung_aktiv 0;
BA_ "GenSigSwitchedByIgnition" SG_ 283 MO_Positionierung_aktiv 0;
BA_ "GenSigSendType" SG_ 283 MO_Rennstart_verf 3;
BA_ "GenSigSwitchedByIgnition" SG_ 283 MO_Rennstart_verf 0;
BA_ "GenSigSendType" SG_ 283 MO_Status_Katheizen 0;
BA_ "GenSigSwitchedByIgnition" SG_ 283 MO_Status_Katheizen 0;
BA_ "GenSigSendType" SG_ 283 MO_Status_MIN_Wunschdrehzahl 3;
BA_ "GenSigSwitchedByIgnition" SG_ 283 MO_Status_MIN_Wunschdrehzahl 0;
BA_ "GenSigSendType" SG_ 2589283475 SCR_Einheit 0;
BA_ "GenSigSwitchedByIgnition" SG_ 2589283475 SCR_Einheit 0;
BA_ "GenSigSendType" SG_ 2589283475 SCR_Fuellstand 0;
BA_ "GenSigStartValue" SG_ 2589283475 SCR_Fuellstand 127;
BA_ "GenSigSwitchedByIgnition" SG_ 2589283475 SCR_Fuellstand 0;
BA_ "GenSigSendType" SG_ 2589283475 SCR_Nachfuellmenge_Einheit 0;
BA_ "GenSigSwitchedByIgnition" SG_ 2589283475 SCR_Nachfuellmenge_Einheit 0;
BA_ "GenSigSendType" SG_ 2589283475 SCR_Nachfuellmenge_max 0;
BA_ "GenSigStartValue" SG_ 2589283475 SCR_Nachfuellmenge_max 255;
BA_ "GenSigSwitchedByIgnition" SG_ 2589283475 SCR_Nachfuellmenge_max 0;
BA_ "GenSigSendType" SG_ 2589283475 SCR_Nachfuellmenge_min 0;
BA_ "GenSigStartValue" SG_ 2589283475 SCR_Nachfuellmenge_min 127;
BA_ "GenSigSwitchedByIgnition" SG_ 2589283475 SCR_Nachfuellmenge_min 0;
BA_ "GenSigSendType" SG_ 2589283475 SCR_Restreichweite 0;
BA_ "GenSigStartValue" SG_ 2589283475 SCR_Restreichweite 32767;
BA_ "GenSigSwitchedByIgnition" SG_ 2589283475 SCR_Restreichweite 0;
BA_ "GenSigSendType" SG_ 2589283475 SCR_Retriggersignal 0;
BA_ "GenSigSwitchedByIgnition" SG_ 2589283475 SCR_Retriggersignal 0;
BA_ "GenSigSendType" SG_ 2589283475 SCR_Tankvolumen 0;
BA_ "GenSigStartValue" SG_ 2589283475 SCR_Tankvolumen 63;
BA_ "GenSigSwitchedByIgnition" SG_ 2589283475 SCR_Tankvolumen 0;
BA_ "GenSigSendType" SG_ 2589283475 SCR_Zustand 0;
BA_ "GenSigSwitchedByIgnition" SG_ 2589283475 SCR_Zustand 0;
BA_ "GenSigSendType" SG_ 834 MO_E_Texte_LB 0;
BA_ "GenSigSwitchedByIgnition" SG_ 834 MO_E_Texte_LB 0;
BA_ "GenSigSendType" SG_ 834 MO_Energyflow 0;
BA_ "GenSigSwitchedByIgnition" SG_ 834 MO_Energyflow 0;
BA_ "GenSigSendType" SG_ 834 MO_Sperrung_FahrPr_BZS_LB 0;
BA_ "GenSigSwitchedByIgnition" SG_ 834 MO_Sperrung_FahrPr_BZS_LB 0;
BA_ "GenSigSendType" SG_ 834 MO_TorqueDistrib_Hi 0;
BA_ "GenSigStartValue" SG_ 834 MO_TorqueDistrib_Hi 100;
BA_ "GenSigSwitchedByIgnition" SG_ 834 MO_TorqueDistrib_Hi 0;
BA_ "Fehlerwert" SG_ 834 MO_TorqueDistrib_Hi 255;
BA_ "GenSigSendType" SG_ 834 MO_TorqueDistrib_VL 0;
BA_ "GenSigStartValue" SG_ 834 MO_TorqueDistrib_VL 100;
BA_ "GenSigSwitchedByIgnition" SG_ 834 MO_TorqueDistrib_VL 0;
BA_ "Fehlerwert" SG_ 834 MO_TorqueDistrib_VL 255;
BA_ "GenSigSendType" SG_ 834 MO_TorqueDistrib_VR 0;
BA_ "GenSigStartValue" SG_ 834 MO_TorqueDistrib_VR 100;
BA_ "GenSigSwitchedByIgnition" SG_ 834 MO_TorqueDistrib_VR 0;
BA_ "Fehlerwert" SG_ 834 MO_TorqueDistrib_VR 255;
BA_ "GenSigSendType" SG_ 834 MO_Wassertemp_Schutz_Anf 0;
BA_ "GenSigSwitchedByIgnition" SG_ 834 MO_Wassertemp_Schutz_Anf 0;
BA_ "GenSigSendType" SG_ 706 MO_ADR_Status 3;
BA_ "GenSigSwitchedByIgnition" SG_ 706 MO_ADR_Status 0;
BA_ "GenSigSendType" SG_ 706 MO_AGA_Sound_Texte 3;
BA_ "GenSigSwitchedByIgnition" SG_ 706 MO_AGA_Sound_Texte 0;
BA_ "GenSigSendType" SG_ 706 MO_Anz_Kuehlerluefter 3;
BA_ "GenSigSwitchedByIgnition" SG_ 706 MO_Anz_Kuehlerluefter 0;
BA_ "GenSigSendType" SG_ 706 MO_Anzeige_FMAus_Text 3;
BA_ "GenSigSwitchedByIgnition" SG_ 706 MO_Anzeige_FMAus_Text 0;
BA_ "GenSigSendType" SG_ 706 MO_Anzeige_StSt_Symbol 3;
BA_ "GenSigSwitchedByIgnition" SG_ 706 MO_Anzeige_StSt_Symbol 0;
BA_ "GenSigSendType" SG_ 706 MO_Anzeige_StSt_Text 3;
BA_ "GenSigSwitchedByIgnition" SG_ 706 MO_Anzeige_StSt_Text 0;
BA_ "GenSigSendType" SG_ 706 MO_Avus_Motorschutz 3;
BA_ "GenSigSwitchedByIgnition" SG_ 706 MO_Avus_Motorschutz 0;
BA_ "GenSigSendType" SG_ 706 MO_Fehler_MSpG 3;
BA_ "GenSigSwitchedByIgnition" SG_ 706 MO_Fehler_MSpG 0;
BA_ "GenSigSendType" SG_ 706 MO_im_Leerlauf 3;
BA_ "GenSigSwitchedByIgnition" SG_ 706 MO_im_Leerlauf 0;
BA_ "GenSigSendType" SG_ 706 MO_Oel_Temp_Radsatz_Warn 3;
BA_ "GenSigSwitchedByIgnition" SG_ 706 MO_Oel_Temp_Radsatz_Warn 0;
BA_ "GenSigSendType" SG_ 706 MO_OelMessung_Dauer 3;
BA_ "GenSigStartValue" SG_ 706 MO_OelMessung_Dauer 15;
BA_ "GenSigSwitchedByIgnition" SG_ 706 MO_OelMessung_Dauer 0;
BA_ "GenSigSendType" SG_ 706 MO_Red_Fahrleistung 3;
BA_ "GenSigSwitchedByIgnition" SG_ 706 MO_Red_Fahrleistung 0;
BA_ "GenSigSendType" SG_ 706 MO_Rekuperationsstufe 3;
BA_ "GenSigStartValue" SG_ 706 MO_Rekuperationsstufe 7;
BA_ "GenSigSwitchedByIgnition" SG_ 706 MO_Rekuperationsstufe 0;
BA_ "GenSigSendType" SG_ 706 PEA_Texte 3;
BA_ "GenSigSwitchedByIgnition" SG_ 706 PEA_Texte 0;
BA_ "GenSigSendType" SG_ 706 TSK_Einheit_vMax_FahrerInfo 3;
BA_ "GenSigSwitchedByIgnition" SG_ 706 TSK_Einheit_vMax_FahrerInfo 0;
BA_ "GenSigSendType" SG_ 706 TSK_Status_vMax_FahrerInfo 3;
BA_ "GenSigSwitchedByIgnition" SG_ 706 TSK_Status_vMax_FahrerInfo 0;
BA_ "GenSigSendType" SG_ 706 TSK_Ueberstimmt_vMax_FahrerInfo 3;
BA_ "GenSigSwitchedByIgnition" SG_ 706 TSK_Ueberstimmt_vMax_FahrerInfo 0;
BA_ "GenSigSendType" SG_ 706 TSK_vMax_FahrerInfo 3;
BA_ "GenSigSwitchedByIgnition" SG_ 706 TSK_vMax_FahrerInfo 0;
BA_ "GenSigSendType" SG_ 706 WIV_Enable_Oeldr_Motor 3;
BA_ "GenSigSwitchedByIgnition" SG_ 706 WIV_Enable_Oeldr_Motor 0;
BA_ "GenSigSendType" SG_ 2589283599 MO_CatHeatBar_LB 0;
BA_ "GenSigStartValue" SG_ 2589283599 MO_CatHeatBar_LB 126;
BA_ "GenSigSwitchedByIgnition" SG_ 2589283599 MO_CatHeatBar_LB 0;
BA_ "Fehlerwert" SG_ 2589283599 MO_CatHeatBar_LB 127;
BA_ "GenSigSendType" SG_ 2589283599 MO_Eboost_LB_active 3;
BA_ "GenSigSwitchedByIgnition" SG_ 2589283599 MO_Eboost_LB_active 0;
BA_ "GenSigSendType" SG_ 2589283599 MO_Eboost_LB_available 3;
BA_ "GenSigSwitchedByIgnition" SG_ 2589283599 MO_Eboost_LB_available 0;
BA_ "GenSigSendType" SG_ 2589283599 MO_Eboost_LB_driveraction 3;
BA_ "GenSigSwitchedByIgnition" SG_ 2589283599 MO_Eboost_LB_driveraction 0;
BA_ "GenSigSendType" SG_ 2589283599 MO_Eboost_LB_failure 3;
BA_ "GenSigSwitchedByIgnition" SG_ 2589283599 MO_Eboost_LB_failure 0;
BA_ "GenSigSendType" SG_ 2589283599 MO_Eboost_LB_LVLavailable 3;
BA_ "GenSigSwitchedByIgnition" SG_ 2589283599 MO_Eboost_LB_LVLavailable 0;
BA_ "GenSigSendType" SG_ 2589283599 MO_Eboost_LB_LVLselected 3;
BA_ "GenSigSwitchedByIgnition" SG_ 2589283599 MO_Eboost_LB_LVLselected 0;
BA_ "GenSigSendType" SG_ 2589283599 MO_Eboost_LB_possible 3;
BA_ "GenSigSwitchedByIgnition" SG_ 2589283599 MO_Eboost_LB_possible 0;
BA_ "GenSigSendType" SG_ 2589283599 MO_Kilometerstand_Wakeup 3;
BA_ "GenSigStartValue" SG_ 2589283599 MO_Kilometerstand_Wakeup 1048574;
BA_ "GenSigSwitchedByIgnition" SG_ 2589283599 MO_Kilometerstand_Wakeup 0;
BA_ "Fehlerwert" SG_ 2589283599 MO_Kilometerstand_Wakeup 1048575;
BA_ "GenSigSendType" SG_ 2589283599 MO_Nachlaufzeit_Kuehlerluefter_2 3;
BA_ "GenSigSwitchedByIgnition" SG_ 2589283599 MO_Nachlaufzeit_Kuehlerluefter_2 0;
BA_ "GenSigSendType" SG_ 2589283599 MO_Status_KL 3;
BA_ "GenSigSwitchedByIgnition" SG_ 2589283599 MO_Status_KL 0;
BA_ "GenSigSendType" SG_ 2589283599 MO_TME_KL_Anf_LB 0;
BA_ "GenSigSwitchedByIgnition" SG_ 2589283599 MO_TME_KL_Anf_LB 0;
BA_ "Fehlerwert" SG_ 2589283599 MO_TME_KL_Anf_LB 127;
BA_ "GenSigSendType" SG_ 1601 MO_Ansaugsystem 0;
BA_ "GenSigFuncType" SG_ 1601 MO_Ansaugsystem 8;
BA_ "GenSigSwitchedByIgnition" SG_ 1601 MO_Ansaugsystem 0;
BA_ "GenSigSendType" SG_ 1601 MO_Anzahl_Zyl 0;
BA_ "GenSigFuncType" SG_ 1601 MO_Anzahl_Zyl 8;
BA_ "GenSigSwitchedByIgnition" SG_ 1601 MO_Anzahl_Zyl 0;
BA_ "GenSigSendType" SG_ 1601 MO_Anzeige_StSt_gueltig 0;
BA_ "GenSigSwitchedByIgnition" SG_ 1601 MO_Anzeige_StSt_gueltig 0;
BA_ "GenSigSendType" SG_ 1601 MO_Code 0;
BA_ "GenSigSwitchedByIgnition" SG_ 1601 MO_Code 0;
BA_ "GenSigSendType" SG_ 1601 MO_DPF_verbaut 0;
BA_ "GenSigFuncType" SG_ 1601 MO_DPF_verbaut 8;
BA_ "GenSigSwitchedByIgnition" SG_ 1601 MO_DPF_verbaut 0;
BA_ "GenSigSendType" SG_ 1601 MO_Faktor_Momente_02 0;
BA_ "GenSigFuncType" SG_ 1601 MO_Faktor_Momente_02 8;
BA_ "GenSigSwitchedByIgnition" SG_ 1601 MO_Faktor_Momente_02 0;
BA_ "GenSigSendType" SG_ 1601 MO_Getriebe_Code 0;
BA_ "GenSigSwitchedByIgnition" SG_ 1601 MO_Getriebe_Code 0;
BA_ "GenSigSendType" SG_ 1601 MO_Hubraum 0;
BA_ "GenSigFuncType" SG_ 1601 MO_Hubraum 8;
BA_ "GenSigSwitchedByIgnition" SG_ 1601 MO_Hubraum 0;
BA_ "GenSigSendType" SG_ 1601 MO_Hybridfahrzeug 0;
BA_ "GenSigFuncType" SG_ 1601 MO_Hybridfahrzeug 8;
BA_ "GenSigSwitchedByIgnition" SG_ 1601 MO_Hybridfahrzeug 0;
BA_ "GenSigSendType" SG_ 1601 MO_Kraftstoffart 0;
BA_ "GenSigFuncType" SG_ 1601 MO_Kraftstoffart 8;
BA_ "GenSigSwitchedByIgnition" SG_ 1601 MO_Kraftstoffart 0;
BA_ "GenSigSendType" SG_ 1601 MO_Leistung 0;
BA_ "GenSigSwitchedByIgnition" SG_ 1601 MO_Leistung 0;
BA_ "GenSigSendType" SG_ 1601 MO_OBD_Typ 0;
BA_ "GenSigSwitchedByIgnition" SG_ 1601 MO_OBD_Typ 0;
BA_ "GenSigSendType" SG_ 1601 MO_StartStopp_Codiert 0;
BA_ "GenSigFuncType" SG_ 1601 MO_StartStopp_Codiert 8;
BA_ "GenSigSwitchedByIgnition" SG_ 1601 MO_StartStopp_Codiert 0;
BA_ "GenSigSendType" SG_ 1601 Motor_Code_01_BZ 0;
BA_ "GenSigFuncType" SG_ 1601 Motor_Code_01_BZ 1;
BA_ "GenSigSwitchedByIgnition" SG_ 1601 Motor_Code_01_BZ 0;
BA_ "GenSigSendType" SG_ 1601 Motor_Code_01_CRC 0;
BA_ "GenSigFuncType" SG_ 1601 Motor_Code_01_CRC 2;
BA_ "GenSigSwitchedByIgnition" SG_ 1601 Motor_Code_01_CRC 0;
BA_ "GenSigSendType" SG_ 1601 TSK_Codierung 0;
BA_ "GenSigStartValue" SG_ 1601 TSK_Codierung 7;
BA_ "GenSigSwitchedByIgnition" SG_ 1601 TSK_Codierung 0;
BA_ "GenSigSendType" SG_ 813 MO_akt_Betrieb 0;
BA_ "GenSigSwitchedByIgnition" SG_ 813 MO_akt_Betrieb 0;
BA_ "GenSigSendType" SG_ 813 MO_AnzeigeGasbetrieb 0;
BA_ "GenSigSwitchedByIgnition" SG_ 813 MO_AnzeigeGasbetrieb 0;
BA_ "GenSigSendType" SG_ 813 MO_CNG_LPG 0;
BA_ "GenSigSwitchedByIgnition" SG_ 813 MO_CNG_LPG 0;
BA_ "GenSigSwitchedByIgnition" SG_ 813 MO_CNG_Tankstopp 0;
BA_ "GenSigSwitchedByIgnition" SG_ 813 MO_CNG_Ueberlauf 0;
BA_ "GenSigSendType" SG_ 813 MO_Erdgasqualitaet 0;
BA_ "GenSigSwitchedByIgnition" SG_ 813 MO_Erdgasqualitaet 0;
BA_ "GenSigSwitchedByIgnition" SG_ 813 MO_Fuellstand_LPG 0;
BA_ "Fehlerwert" SG_ 813 MO_Fuellstand_LPG 1023;
BA_ "GenSigStartValue" SG_ 813 MO_Fuellungsgrad_CNG 254;
BA_ "GenSigSwitchedByIgnition" SG_ 813 MO_Fuellungsgrad_CNG 0;
BA_ "Fehlerwert" SG_ 813 MO_Fuellungsgrad_CNG 255;
BA_ "GenSigStartValue" SG_ 813 MO_Fuellungsgrad_LPG 254;
BA_ "GenSigSwitchedByIgnition" SG_ 813 MO_Fuellungsgrad_LPG 0;
BA_ "Fehlerwert" SG_ 813 MO_Fuellungsgrad_LPG 255;
BA_ "GenSigSwitchedByIgnition" SG_ 813 MO_LPG_Tankstopp 0;
BA_ "GenSigSwitchedByIgnition" SG_ 813 MO_LPG_Ueberlauf 0;
BA_ "GenSigSwitchedByIgnition" SG_ 813 MO_Tankmasse_CNG 0;
BA_ "Fehlerwert" SG_ 813 MO_Tankmasse_CNG 255;
BA_ "GenSigSwitchedByIgnition" SG_ 813 MO_Tankvolumen_LPG 0;
BA_ "Fehlerwert" SG_ 813 MO_Tankvolumen_LPG 255;
BA_ "GenSigSwitchedByIgnition" SG_ 813 MO_Verbrauch_CNG 0;
BA_ "GenSigSwitchedByIgnition" SG_ 813 MO_Verbrauch_LPG 0;
BA_ "GenSigSendType" SG_ 813 MO_Verbrauchsaequivalent 0;
BA_ "GenSigStartValue" SG_ 813 MO_Verbrauchsaequivalent 254;
BA_ "GenSigSwitchedByIgnition" SG_ 813 MO_Verbrauchsaequivalent 0;
BA_ "Fehlerwert" SG_ 813 MO_Verbrauchsaequivalent 255;
BA_ "GenSigSendType" SG_ 305 Ladezustand_02 0;
BA_ "GenSigStartValue" SG_ 305 Ladezustand_02 254;
BA_ "GenSigSwitchedByIgnition" SG_ 305 Ladezustand_02 0;
BA_ "Fehlerwert" SG_ 305 Ladezustand_02 255;
BA_ "GenSigSendType" SG_ 305 MO_ePerformance 0;
BA_ "GenSigSwitchedByIgnition" SG_ 305 MO_ePerformance 0;
BA_ "Fehlerwert" SG_ 305 MO_ePerformance 255;
BA_ "GenSigSendType" SG_ 305 MO_ePowermeter 0;
BA_ "GenSigSwitchedByIgnition" SG_ 305 MO_ePowermeter 0;
BA_ "GenSigSendType" SG_ 305 MO_Powermeter 0;
BA_ "GenSigStartValue" SG_ 305 MO_Powermeter 4093;
BA_ "GenSigSwitchedByIgnition" SG_ 305 MO_Powermeter 0;
BA_ "GenSigSendType" SG_ 305 MO_Powermeter_Elm 0;
BA_ "GenSigStartValue" SG_ 305 MO_Powermeter_Elm 128;
BA_ "GenSigSwitchedByIgnition" SG_ 305 MO_Powermeter_Elm 0;
BA_ "GenSigSendType" SG_ 305 MO_Powermeter_Elm_02 0;
BA_ "GenSigStartValue" SG_ 305 MO_Powermeter_Elm_02 4094;
BA_ "GenSigSwitchedByIgnition" SG_ 305 MO_Powermeter_Elm_02 0;
BA_ "GenSigSendType" SG_ 305 MO_Zust_Antrieb 0;
BA_ "GenSigSwitchedByIgnition" SG_ 305 MO_Zust_Antrieb 0;
BA_ "GenSigSendType" SG_ 305 MO_Zust_Betriebsstrategie 0;
BA_ "GenSigSwitchedByIgnition" SG_ 305 MO_Zust_Betriebsstrategie 0;
BA_ "GenSigSendType" SG_ 1376 MO_Gesamtst_Spgfreiheit 0;
BA_ "GenSigSwitchedByIgnition" SG_ 1376 MO_Gesamtst_Spgfreiheit 0;
BA_ "GenSigSendType" SG_ 1376 MO_HV_Spannungsfreiheit 0;
BA_ "GenSigSwitchedByIgnition" SG_ 1376 MO_HV_Spannungsfreiheit 0;
BA_ "GenSigSendType" SG_ 1376 MO_HYB_Status_Betriebsstrategie 0;
BA_ "GenSigSwitchedByIgnition" SG_ 1376 MO_HYB_Status_Betriebsstrategie 0;
BA_ "GenSigSendType" SG_ 1376 MO_Reku_Leistung 0;
BA_ "GenSigSwitchedByIgnition" SG_ 1376 MO_Reku_Leistung 0;
BA_ "GenSigSendType" SG_ 1376 MO_Tankbereitschaft_Status 0;
BA_ "GenSigSwitchedByIgnition" SG_ 1376 MO_Tankbereitschaft_Status 0;
BA_ "GenSigSendType" SG_ 1376 Motor_Hybrid_04_BZ 0;
BA_ "GenSigFuncType" SG_ 1376 Motor_Hybrid_04_BZ 1;
BA_ "GenSigSwitchedByIgnition" SG_ 1376 Motor_Hybrid_04_BZ 0;
BA_ "GenSigSendType" SG_ 1376 Motor_Hybrid_04_CRC 0;
BA_ "GenSigFuncType" SG_ 1376 Motor_Hybrid_04_CRC 2;
BA_ "GenSigSwitchedByIgnition" SG_ 1376 Motor_Hybrid_04_CRC 0;
BA_REL_ "GenSigTimeoutTime" BU_SG_REL_ CGS SG_ 958 Motor_14_CRC 1000;
BA_REL_ "GenSigTimeoutTime" BU_SG_REL_ CGS SG_ 958 Motor_14_BZ 1000;
BA_REL_ "GenSigTimeoutTime" BU_SG_REL_ CGS SG_ 958 MO_StartStopp_Wiederstart 1000;
BA_REL_ "GenSigTimeoutTime" BU_SG_REL_ CGS SG_ 958 MO_Kl_75 1000;
BA_REL_ "GenSigTimeoutTime" BU_SG_REL_ CGS SG_ 958 MO_Fahrer_bremst 1000;
BA_REL_ "GenSigTimeoutTime" BU_SG_REL_ CGS SG_ 958 MO_QBit_Fahrer_bremst 1000;
BA_REL_ "GenSigTimeoutTime" BU_SG_REL_ CGS SG_ 958 MO_BLS 1000;
BA_REL_ "GenSigTimeoutTime" BU_SG_REL_ CGS SG_ 958 MO_Konsistenz_Bremsped 1000;
BA_REL_ "GenSigTimeoutTime" BU_SG_REL_ CGS SG_ 958 MO_QBit_KL_75 1000;
BA_REL_ "GenSigTimeoutTime" BU_SG_REL_ HUD SG_ 812 MO_MAX_Wunschdrehzahl 2000;
BA_REL_ "GenSigTimeoutTime" BU_SG_REL_ HUD SG_ 1648 MO_obere_Drehzahlgrenze 5000;
BA_REL_ "GenSigTimeoutTime" BU_SG_REL_ HUD SG_ 815 PEA_Fortschrittsanzeige 500;
BA_REL_ "GenSigTimeoutTime" BU_SG_REL_ HUD SG_ 815 MO_Anzeige_Fahrbereitschaft 500;
BA_REL_ "GenSigTimeoutTime" BU_SG_REL_ HUD SG_ 815 MO_Boost_verfuegbar 500;
BA_REL_ "GenSigTimeoutTime" BU_SG_REL_ HUD SG_ 815 MO_Boost_aktiv 500;
BA_REL_ "GenSigTimeoutTime" BU_SG_REL_ HUD SG_ 815 PEA_Hinweis 500;
BA_REL_ "GenSigTimeoutTime" BU_SG_REL_ HUD SG_ 815 PEA_Ereignisanzeige 500;
BA_REL_ "GenSigTimeoutTime" BU_SG_REL_ HUD SG_ 815 PEA_Abschalttexte 500;
BA_REL_ "GenSigTimeoutTime" BU_SG_REL_ HUD SG_ 815 PEA_Zielgeschw_Einheit 500;
BA_REL_ "GenSigTimeoutTime" BU_SG_REL_ HUD SG_ 815 PEA_Zielgeschw 500;
BA_REL_ "GenSigTimeoutTime" BU_SG_REL_ HUD SG_ 967 MO_E_Texte 800;
BA_REL_ "GenSigTimeoutTime" BU_SG_REL_ HUD SG_ 967 MO_RedFahrleistung_Lampe 800;
BA_REL_ "GenSigTimeoutTime" BU_SG_REL_ HUD SG_ 327 MO_Hochschaltdrehz 500;
BA_REL_ "GenSigTimeoutTime" BU_SG_REL_ HUD SG_ 327 MO_Schaltblitz_Anz 500;
BA_REL_ "GenSigTimeoutTime" BU_SG_REL_ HUD SG_ 305 MO_Powermeter 500;
BA_REL_ "GenSigTimeoutTime" BU_SG_REL_ Kombi SG_ 1607 MO_ITM_Kuehlmittel_Temp 3200;
BA_REL_ "GenSigTimeoutTime" BU_SG_REL_ Kombi SG_ 1607 SCR_Text 3200;
BA_REL_ "GenSigTimeoutTime" BU_SG_REL_ Kombi SG_ 1607 SCR_verbaut 3200;
BA_REL_ "GenSigTimeoutTime" BU_SG_REL_ Kombi SG_ 1607 MO_Kraftstofffilter_Wasser 3200;
BA_REL_ "GenSigTimeoutTime" BU_SG_REL_ Kombi SG_ 1607 SCR_Inducement_Strategie 3200;
BA_REL_ "GenSigTimeoutTime" BU_SG_REL_ Kombi SG_ 1607 MO_MKB_MUX 3200;
BA_REL_ "GenSigTimeoutTime" BU_SG_REL_ Kombi SG_ 1607 MO_MKB_01 3200;
BA_REL_ "GenSigTimeoutTime" BU_SG_REL_ Kombi SG_ 1607 MO_MKB_02 3200;
BA_REL_ "GenSigTimeoutTime" BU_SG_REL_ Kombi SG_ 1607 MO_MKB_03 3200;
BA_REL_ "GenSigTimeoutTime" BU_SG_REL_ Kombi SG_ 1607 MO_MKB_04 3200;
BA_REL_ "GenSigTimeoutTime" BU_SG_REL_ Kombi SG_ 168 MO_Drehzahl_01 500;
BA_REL_ "GenSigTimeoutTime" BU_SG_REL_ Kombi SG_ 958 MO_StartStopp_Wiederstart 1000;
BA_REL_ "GenSigTimeoutTime" BU_SG_REL_ Kombi SG_ 958 MO_StartStopp_Motorstopp 1000;
BA_REL_ "GenSigTimeoutTime" BU_SG_REL_ Kombi SG_ 958 MO_Kl_75 1000;
BA_REL_ "GenSigTimeoutTime" BU_SG_REL_ Kombi SG_ 958 MO_Gangposition 1000;
BA_REL_ "GenSigTimeoutTime" BU_SG_REL_ Kombi SG_ 958 MO_HYB_Fahrbereitschaft 1000;
BA_REL_ "GenSigTimeoutTime" BU_SG_REL_ Kombi SG_ 958 MO_Ext_E_Fahrt_aktiv 1000;
BA_REL_ "GenSigTimeoutTime" BU_SG_REL_ Kombi SG_ 958 MO_Kuppl_schalter 1000;
BA_REL_ "GenSigTimeoutTime" BU_SG_REL_ Kombi SG_ 958 MO_Motor_laeuft 1000;
BA_REL_ "GenSigTimeoutTime" BU_SG_REL_ Kombi SG_ 958 MO_Text_Geschw_red 1000;
BA_REL_ "GenSigTimeoutTime" BU_SG_REL_ Kombi SG_ 958 MO_HYB_VM_aktiv 1000;
BA_REL_ "GenSigTimeoutTime" BU_SG_REL_ Kombi SG_ 1631 MO_Anzeige_Kaltleuchte 3200;
BA_REL_ "GenSigTimeoutTime" BU_SG_REL_ Kombi SG_ 1631 MO_Energieinhalt_BMS 3200;
BA_REL_ "GenSigTimeoutTime" BU_SG_REL_ Kombi SG_ 812 MO_Prio_MAX_Wunschdrehzahl 2000;
BA_REL_ "GenSigTimeoutTime" BU_SG_REL_ Kombi SG_ 812 MO_MAX_Wunschdrehzahl 2000;
BA_REL_ "GenSigTimeoutTime" BU_SG_REL_ Kombi SG_ 1648 MO_max_Ladedruck 5000;
BA_REL_ "GenSigTimeoutTime" BU_SG_REL_ Kombi SG_ 1648 MO_StartStopp_PopUp 5000;
BA_REL_ "GenSigTimeoutTime" BU_SG_REL_ Kombi SG_ 1648 MO_EPCL 5000;
BA_REL_ "GenSigTimeoutTime" BU_SG_REL_ Kombi SG_ 1648 MO_Zylabsch_Texte_02 5000;
BA_REL_ "GenSigTimeoutTime" BU_SG_REL_ Kombi SG_ 1648 MO_Fahrzeugtyp 5000;
BA_REL_ "GenSigTimeoutTime" BU_SG_REL_ Kombi SG_ 1648 MO_Ethanol_BS_Texte 5000;
BA_REL_ "GenSigTimeoutTime" BU_SG_REL_ Kombi SG_ 1648 MO_Drehzahl_Warnung 5000;
BA_REL_ "GenSigTimeoutTime" BU_SG_REL_ Kombi SG_ 1648 MO_obere_Drehzahlgrenze 5000;
BA_REL_ "GenSigTimeoutTime" BU_SG_REL_ Kombi SG_ 815 MO_Anzeige_Rekuperation 500;
BA_REL_ "GenSigTimeoutTime" BU_SG_REL_ Kombi SG_ 815 PEA_Fortschrittsanzeige 500;
BA_REL_ "GenSigTimeoutTime" BU_SG_REL_ Kombi SG_ 815 MO_Anzeige_Fahrbereitschaft 500;
BA_REL_ "GenSigTimeoutTime" BU_SG_REL_ Kombi SG_ 815 MO_Boost_verfuegbar 500;
BA_REL_ "GenSigTimeoutTime" BU_SG_REL_ Kombi SG_ 815 MO_Overboost 500;
BA_REL_ "GenSigTimeoutTime" BU_SG_REL_ Kombi SG_ 815 MO_Boost_aktiv 500;
BA_REL_ "GenSigTimeoutTime" BU_SG_REL_ Kombi SG_ 815 MO_Anzeige_Betriebsmodus 500;
BA_REL_ "GenSigTimeoutTime" BU_SG_REL_ Kombi SG_ 815 PEA_Hinweis 500;
BA_REL_ "GenSigTimeoutTime" BU_SG_REL_ Kombi SG_ 815 PEA_Ereignisanzeige 500;
BA_REL_ "GenSigTimeoutTime" BU_SG_REL_ Kombi SG_ 815 PEA_Ereignisanzeige_temporaer 500;
BA_REL_ "GenSigTimeoutTime" BU_SG_REL_ Kombi SG_ 815 PEA_Abschalttexte 500;
BA_REL_ "GenSigTimeoutTime" BU_SG_REL_ Kombi SG_ 815 PEA_Zielgeschw_Einheit 500;
BA_REL_ "GenSigTimeoutTime" BU_SG_REL_ Kombi SG_ 815 PEA_Zielgeschw 500;
BA_REL_ "GenSigTimeoutTime" BU_SG_REL_ Kombi SG_ 815 MO_Antriebsstrang_Warnung_HS 500;
BA_REL_ "GenSigTimeoutTime" BU_SG_REL_ Kombi SG_ 815 MO_Anzeige_Verbrauch_oE 500;
BA_REL_ "GenSigTimeoutTime" BU_SG_REL_ Kombi SG_ 1391 MO_Anzeige_Leistung_Max 5000;
BA_REL_ "GenSigTimeoutTime" BU_SG_REL_ Kombi SG_ 1391 MO_Anzeige_Drehmoment_Max 5000;
BA_REL_ "GenSigTimeoutTime" BU_SG_REL_ Kombi SG_ 967 MO_KJS_nicht_bereit 800;
BA_REL_ "GenSigTimeoutTime" BU_SG_REL_ Kombi SG_ 967 MO_ITM_Warnung_Pumpe 800;
BA_REL_ "GenSigTimeoutTime" BU_SG_REL_ Kombi SG_ 967 WIV_Oelmin_Warn 800;
BA_REL_ "GenSigTimeoutTime" BU_SG_REL_ Kombi SG_ 967 WIV_Sensorfehler 800;
BA_REL_ "GenSigTimeoutTime" BU_SG_REL_ Kombi SG_ 967 WIV_Schieflage 800;
BA_REL_ "GenSigTimeoutTime" BU_SG_REL_ Kombi SG_ 967 WIV_Oelstand 800;
BA_REL_ "GenSigTimeoutTime" BU_SG_REL_ Kombi SG_ 967 OLEV_Systemstoerung 800;
BA_REL_ "GenSigTimeoutTime" BU_SG_REL_ Kombi SG_ 967 MO_Oelwarnung_max 800;
BA_REL_ "GenSigTimeoutTime" BU_SG_REL_ Kombi SG_ 967 WIV_Oelsystem_aktiv 800;
BA_REL_ "GenSigTimeoutTime" BU_SG_REL_ Kombi SG_ 967 WIV_nicht_betriebswarm 800;
BA_REL_ "GenSigTimeoutTime" BU_SG_REL_ Kombi SG_ 967 WIV_Ueberfuell_Warn 800;
BA_REL_ "GenSigTimeoutTime" BU_SG_REL_ Kombi SG_ 967 MO_E_Warnungen 800;
BA_REL_ "GenSigTimeoutTime" BU_SG_REL_ Kombi SG_ 967 MO_Text_Motorstart 800;
BA_REL_ "GenSigTimeoutTime" BU_SG_REL_ Kombi SG_ 967 MO_E_Texte 800;
BA_REL_ "GenSigTimeoutTime" BU_SG_REL_ Kombi SG_ 967 MO_Text_Partikelfil_Reg 800;
BA_REL_ "GenSigTimeoutTime" BU_SG_REL_ Kombi SG_ 967 OLEV_Oelstand_nicht_vorhanden 800;
BA_REL_ "GenSigTimeoutTime" BU_SG_REL_ Kombi SG_ 967 WIV_Oelmenge 800;
BA_REL_ "GenSigTimeoutTime" BU_SG_REL_ Kombi SG_ 967 MO_OBD2_Lampe 800;
BA_REL_ "GenSigTimeoutTime" BU_SG_REL_ Kombi SG_ 967 MO_Heissleuchte 800;
BA_REL_ "GenSigTimeoutTime" BU_SG_REL_ Kombi SG_ 967 MO_Partikel_Lampe 800;
BA_REL_ "GenSigTimeoutTime" BU_SG_REL_ Kombi SG_ 967 MO_RedFahrleistung_Lampe 800;
BA_REL_ "GenSigTimeoutTime" BU_SG_REL_ Kombi SG_ 967 WIV_Oelstand_nicht_vorhanden 800;
BA_REL_ "GenSigTimeoutTime" BU_SG_REL_ Kombi SG_ 967 WIV_nachfuellanzeige_ein 800;
BA_REL_ "GenSigTimeoutTime" BU_SG_REL_ Kombi SG_ 967 WIV_Ueberfuell_deaktiv 800;
BA_REL_ "GenSigTimeoutTime" BU_SG_REL_ Kombi SG_ 967 WIV_Unterfuell_Warn 800;
BA_REL_ "GenSigTimeoutTime" BU_SG_REL_ Kombi SG_ 967 MO_Text_Tankdeckelwarn 800;
BA_REL_ "GenSigTimeoutTime" BU_SG_REL_ Kombi SG_ 967 MO_Vorglueh_Lampe 800;
BA_REL_ "GenSigTimeoutTime" BU_SG_REL_ Kombi SG_ 967 WIV_Oeldr_Warn_Motor 800;
BA_REL_ "GenSigTimeoutTime" BU_SG_REL_ Kombi SG_ 967 MO_E_Mode 800;
BA_REL_ "GenSigTimeoutTime" BU_SG_REL_ Kombi SG_ 327 MO_Hochschaltdrehz 500;
BA_REL_ "GenSigTimeoutTime" BU_SG_REL_ Kombi SG_ 327 MO_Anzeige_Verbr_Einheit 500;
BA_REL_ "GenSigTimeoutTime" BU_SG_REL_ Kombi SG_ 327 MO_Schaltblitz_Anz 500;
BA_REL_ "GenSigTimeoutTime" BU_SG_REL_ Kombi SG_ 327 MO_Anzeige_Drehmoment 500;
BA_REL_ "GenSigTimeoutTime" BU_SG_REL_ Kombi SG_ 327 MO_Anzeige_Leistung 500;
BA_REL_ "GenSigTimeoutTime" BU_SG_REL_ Kombi SG_ 1366 MO_Verbau_StartSys_Ritzelstarter 5000;
BA_REL_ "GenSigTimeoutTime" BU_SG_REL_ Kombi SG_ 1366 MO_Verbau_StartSys_EM_MV 5000;
BA_REL_ "GenSigTimeoutTime" BU_SG_REL_ Kombi SG_ 1366 MO_Verbau_StartSys_EM_HV 5000;
BA_REL_ "GenSigTimeoutTime" BU_SG_REL_ Kombi SG_ 1366 MO_Verbau_StartSys_RSG_NV 5000;
BA_REL_ "GenSigTimeoutTime" BU_SG_REL_ Kombi SG_ 1366 MO_Verbau_StartSys_Q_Diode 5000;
BA_REL_ "GenSigTimeoutTime" BU_SG_REL_ Kombi SG_ 1366 MO_Verbau_StartSys_RSG_MV 5000;
BA_REL_ "GenSigTimeoutTime" BU_SG_REL_ Kombi SG_ 1366 MO_Oelstand_Sens_roh 5000;
BA_REL_ "GenSigTimeoutTime" BU_SG_REL_ Kombi SG_ 283 MO_Freilauf_Status 5000;
BA_REL_ "GenSigTimeoutTime" BU_SG_REL_ Kombi SG_ 283 MO_Rennstart_verf 5000;
BA_REL_ "GenSigTimeoutTime" BU_SG_REL_ Kombi SG_ 2589283475 SCR_Zustand 5000;
BA_REL_ "GenSigTimeoutTime" BU_SG_REL_ Kombi SG_ 2589283475 SCR_Retriggersignal 5000;
BA_REL_ "GenSigTimeoutTime" BU_SG_REL_ Kombi SG_ 2589283475 SCR_Nachfuellmenge_min 5000;
BA_REL_ "GenSigTimeoutTime" BU_SG_REL_ Kombi SG_ 2589283475 SCR_Nachfuellmenge_max 5000;
BA_REL_ "GenSigTimeoutTime" BU_SG_REL_ Kombi SG_ 2589283475 SCR_Nachfuellmenge_Einheit 5000;
BA_REL_ "GenSigTimeoutTime" BU_SG_REL_ Kombi SG_ 2589283475 SCR_Einheit 5000;
BA_REL_ "GenSigTimeoutTime" BU_SG_REL_ Kombi SG_ 2589283475 SCR_Restreichweite 5000;
BA_REL_ "GenSigTimeoutTime" BU_SG_REL_ Kombi SG_ 706 MO_Anzeige_StSt_Text 4000;
BA_REL_ "GenSigTimeoutTime" BU_SG_REL_ Kombi SG_ 706 MO_Anzeige_StSt_Symbol 4000;
BA_REL_ "GenSigTimeoutTime" BU_SG_REL_ Kombi SG_ 706 MO_AGA_Sound_Texte 4000;
BA_REL_ "GenSigTimeoutTime" BU_SG_REL_ Kombi SG_ 706 MO_Fehler_MSpG 4000;
BA_REL_ "GenSigTimeoutTime" BU_SG_REL_ Kombi SG_ 706 PEA_Texte 4000;
BA_REL_ "GenSigTimeoutTime" BU_SG_REL_ Kombi SG_ 706 TSK_Ueberstimmt_vMax_FahrerInfo 4000;
BA_REL_ "GenSigTimeoutTime" BU_SG_REL_ Kombi SG_ 706 MO_Avus_Motorschutz 4000;
BA_REL_ "GenSigTimeoutTime" BU_SG_REL_ Kombi SG_ 706 MO_Rekuperationsstufe 4000;
BA_REL_ "GenSigTimeoutTime" BU_SG_REL_ Kombi SG_ 706 TSK_Einheit_vMax_FahrerInfo 4000;
BA_REL_ "GenSigTimeoutTime" BU_SG_REL_ Kombi SG_ 706 TSK_Status_vMax_FahrerInfo 4000;
BA_REL_ "GenSigTimeoutTime" BU_SG_REL_ Kombi SG_ 706 MO_Red_Fahrleistung 4000;
BA_REL_ "GenSigTimeoutTime" BU_SG_REL_ Kombi SG_ 706 MO_im_Leerlauf 4000;
BA_REL_ "GenSigTimeoutTime" BU_SG_REL_ Kombi SG_ 706 WIV_Enable_Oeldr_Motor 4000;
BA_REL_ "GenSigTimeoutTime" BU_SG_REL_ Kombi SG_ 706 MO_OelMessung_Dauer 4000;
BA_REL_ "GenSigTimeoutTime" BU_SG_REL_ Kombi SG_ 706 TSK_vMax_FahrerInfo 4000;
BA_REL_ "GenSigTimeoutTime" BU_SG_REL_ Kombi SG_ 1601 MO_Hybridfahrzeug 5000;
BA_REL_ "GenSigTimeoutTime" BU_SG_REL_ Kombi SG_ 1601 MO_StartStopp_Codiert 5000;
BA_REL_ "GenSigTimeoutTime" BU_SG_REL_ Kombi SG_ 1601 MO_Anzeige_StSt_gueltig 5000;
BA_REL_ "GenSigTimeoutTime" BU_SG_REL_ Kombi SG_ 1601 MO_Kraftstoffart 5000;
BA_REL_ "GenSigTimeoutTime" BU_SG_REL_ Kombi SG_ 813 MO_AnzeigeGasbetrieb 500;
BA_REL_ "GenSigTimeoutTime" BU_SG_REL_ Kombi SG_ 813 MO_akt_Betrieb 500;
BA_REL_ "GenSigTimeoutTime" BU_SG_REL_ Kombi SG_ 813 MO_Erdgasqualitaet 500;
BA_REL_ "GenSigTimeoutTime" BU_SG_REL_ Kombi SG_ 813 MO_Verbrauchsaequivalent 500;
BA_REL_ "GenSigTimeoutTime" BU_SG_REL_ Kombi SG_ 813 MO_CNG_LPG 500;
BA_REL_ "GenSigTimeoutTime" BU_SG_REL_ Kombi SG_ 813 MO_Fuellstand_LPG 500;
BA_REL_ "GenSigTimeoutTime" BU_SG_REL_ Kombi SG_ 813 MO_CNG_Tankstopp 500;
BA_REL_ "GenSigTimeoutTime" BU_SG_REL_ Kombi SG_ 813 MO_LPG_Tankstopp 500;
BA_REL_ "GenSigTimeoutTime" BU_SG_REL_ Kombi SG_ 813 MO_Tankmasse_CNG 500;
BA_REL_ "GenSigTimeoutTime" BU_SG_REL_ Kombi SG_ 813 MO_Tankvolumen_LPG 500;
BA_REL_ "GenSigTimeoutTime" BU_SG_REL_ Kombi SG_ 813 MO_Fuellungsgrad_CNG 500;
BA_REL_ "GenSigTimeoutTime" BU_SG_REL_ Kombi SG_ 813 MO_Fuellungsgrad_LPG 500;
BA_REL_ "GenSigTimeoutTime" BU_SG_REL_ Kombi SG_ 813 MO_CNG_Ueberlauf 500;
BA_REL_ "GenSigTimeoutTime" BU_SG_REL_ Kombi SG_ 813 MO_LPG_Ueberlauf 500;
BA_REL_ "GenSigTimeoutTime" BU_SG_REL_ Kombi SG_ 813 MO_Verbrauch_CNG 500;
BA_REL_ "GenSigTimeoutTime" BU_SG_REL_ Kombi SG_ 813 MO_Verbrauch_LPG 500;
BA_REL_ "GenSigTimeoutTime" BU_SG_REL_ Kombi SG_ 305 MO_ePowermeter 500;
BA_REL_ "GenSigTimeoutTime" BU_SG_REL_ Kombi SG_ 305 MO_ePerformance 500;
BA_REL_ "GenSigTimeoutTime" BU_SG_REL_ Kombi SG_ 305 MO_Zust_Antrieb 500;
BA_REL_ "GenSigTimeoutTime" BU_SG_REL_ Kombi SG_ 305 MO_Zust_Betriebsstrategie 500;
BA_REL_ "GenSigTimeoutTime" BU_SG_REL_ Kombi SG_ 305 Ladezustand_02 500;
BA_REL_ "GenSigTimeoutTime" BU_SG_REL_ Kombi SG_ 305 MO_Powermeter_Elm 500;
BA_REL_ "GenSigTimeoutTime" BU_SG_REL_ Kombi SG_ 305 MO_Powermeter_Elm_02 500;
BA_REL_ "GenSigTimeoutTime" BU_SG_REL_ Kombi SG_ 305 MO_Powermeter 500;
BA_REL_ "GenSigTimeoutTime" BU_SG_REL_ Kombi SG_ 1376 MO_Tankbereitschaft_Status 1600;
BA_REL_ "GenSigTimeoutTime" BU_SG_REL_ Kombi_LB SG_ 1607 MO_ITM_Kuehlmittel_Temp 3200;
BA_REL_ "GenSigTimeoutTime" BU_SG_REL_ Kombi_LB SG_ 1607 MO_Kraftstofffilter_Wasser 3200;
BA_REL_ "GenSigTimeoutTime" BU_SG_REL_ Kombi_LB SG_ 1607 MO_MKB_MUX 3200;
BA_REL_ "GenSigTimeoutTime" BU_SG_REL_ Kombi_LB SG_ 1607 MO_MKB_01 3200;
BA_REL_ "GenSigTimeoutTime" BU_SG_REL_ Kombi_LB SG_ 1607 MO_MKB_02 3200;
BA_REL_ "GenSigTimeoutTime" BU_SG_REL_ Kombi_LB SG_ 1607 MO_MKB_03 3200;
BA_REL_ "GenSigTimeoutTime" BU_SG_REL_ Kombi_LB SG_ 1607 MO_MKB_04 3200;
BA_REL_ "GenSigTimeoutTime" BU_SG_REL_ Kombi_LB SG_ 168 MO_Drehzahl_01 500;
BA_REL_ "GenSigTimeoutTime" BU_SG_REL_ Kombi_LB SG_ 958 MO_StartStopp_Wiederstart 1000;
BA_REL_ "GenSigTimeoutTime" BU_SG_REL_ Kombi_LB SG_ 958 MO_StartStopp_Motorstopp 1000;
BA_REL_ "GenSigTimeoutTime" BU_SG_REL_ Kombi_LB SG_ 958 MO_Kl_75 1000;
BA_REL_ "GenSigTimeoutTime" BU_SG_REL_ Kombi_LB SG_ 958 MO_HYB_Fahrbereitschaft 1000;
BA_REL_ "GenSigTimeoutTime" BU_SG_REL_ Kombi_LB SG_ 958 MO_Ext_E_Fahrt_aktiv 1000;
BA_REL_ "GenSigTimeoutTime" BU_SG_REL_ Kombi_LB SG_ 958 MO_Kuppl_schalter 1000;
BA_REL_ "GenSigTimeoutTime" BU_SG_REL_ Kombi_LB SG_ 958 MO_Motor_laeuft 1000;
BA_REL_ "GenSigTimeoutTime" BU_SG_REL_ Kombi_LB SG_ 958 MO_Text_Geschw_red 1000;
BA_REL_ "GenSigTimeoutTime" BU_SG_REL_ Kombi_LB SG_ 958 MO_HYB_VM_aktiv 1000;
BA_REL_ "GenSigTimeoutTime" BU_SG_REL_ Kombi_LB SG_ 1631 MO_Anzeige_Kaltleuchte 3200;
BA_REL_ "GenSigTimeoutTime" BU_SG_REL_ Kombi_LB SG_ 1631 MO_Energieinhalt_BMS 3200;
BA_REL_ "GenSigTimeoutTime" BU_SG_REL_ Kombi_LB SG_ 812 MO_Sperrung_FahrPr_BZS 2000;
BA_REL_ "GenSigTimeoutTime" BU_SG_REL_ Kombi_LB SG_ 812 MO_Prio_MAX_Wunschdrehzahl 2000;
BA_REL_ "GenSigTimeoutTime" BU_SG_REL_ Kombi_LB SG_ 812 MO_MAX_Wunschdrehzahl 2000;
BA_REL_ "GenSigTimeoutTime" BU_SG_REL_ Kombi_LB SG_ 1648 MO_StartStopp_PopUp 5000;
BA_REL_ "GenSigTimeoutTime" BU_SG_REL_ Kombi_LB SG_ 1648 MO_EPCL 5000;
BA_REL_ "GenSigTimeoutTime" BU_SG_REL_ Kombi_LB SG_ 1648 MO_Zylabsch_Texte_02 5000;
BA_REL_ "GenSigTimeoutTime" BU_SG_REL_ Kombi_LB SG_ 1648 MO_Fahrzeugtyp 5000;
BA_REL_ "GenSigTimeoutTime" BU_SG_REL_ Kombi_LB SG_ 1648 MO_Ethanol_BS_Texte 5000;
BA_REL_ "GenSigTimeoutTime" BU_SG_REL_ Kombi_LB SG_ 1648 MO_Drehzahl_Warnung 5000;
BA_REL_ "GenSigTimeoutTime" BU_SG_REL_ Kombi_LB SG_ 1648 MO_obere_Drehzahlgrenze 5000;
BA_REL_ "GenSigTimeoutTime" BU_SG_REL_ Kombi_LB SG_ 815 MO_Anzeige_Rekuperation 500;
BA_REL_ "GenSigTimeoutTime" BU_SG_REL_ Kombi_LB SG_ 815 PEA_Fortschrittsanzeige 500;
BA_REL_ "GenSigTimeoutTime" BU_SG_REL_ Kombi_LB SG_ 815 MO_Anzeige_Fahrbereitschaft 500;
BA_REL_ "GenSigTimeoutTime" BU_SG_REL_ Kombi_LB SG_ 815 MO_Boost_verfuegbar 500;
BA_REL_ "GenSigTimeoutTime" BU_SG_REL_ Kombi_LB SG_ 815 MO_Overboost 500;
BA_REL_ "GenSigTimeoutTime" BU_SG_REL_ Kombi_LB SG_ 815 MO_Boost_aktiv 500;
BA_REL_ "GenSigTimeoutTime" BU_SG_REL_ Kombi_LB SG_ 815 MO_Anzeige_Betriebsmodus 500;
BA_REL_ "GenSigTimeoutTime" BU_SG_REL_ Kombi_LB SG_ 815 PEA_Hinweis 500;
BA_REL_ "GenSigTimeoutTime" BU_SG_REL_ Kombi_LB SG_ 815 PEA_Ereignisanzeige 500;
BA_REL_ "GenSigTimeoutTime" BU_SG_REL_ Kombi_LB SG_ 815 PEA_Ereignisanzeige_temporaer 500;
BA_REL_ "GenSigTimeoutTime" BU_SG_REL_ Kombi_LB SG_ 815 PEA_Abschalttexte 500;
BA_REL_ "GenSigTimeoutTime" BU_SG_REL_ Kombi_LB SG_ 815 PEA_Zielgeschw_Einheit 500;
BA_REL_ "GenSigTimeoutTime" BU_SG_REL_ Kombi_LB SG_ 815 PEA_Zielgeschw 500;
BA_REL_ "GenSigTimeoutTime" BU_SG_REL_ Kombi_LB SG_ 815 MO_Antriebsstrang_Warnung_HS 500;
BA_REL_ "GenSigTimeoutTime" BU_SG_REL_ Kombi_LB SG_ 815 MO_Anzeige_Verbrauch_oE 500;
BA_REL_ "GenSigTimeoutTime" BU_SG_REL_ Kombi_LB SG_ 1391 MO_Anzeige_Leistung_Max 5000;
BA_REL_ "GenSigTimeoutTime" BU_SG_REL_ Kombi_LB SG_ 1391 MO_Anzeige_Drehmoment_Max 5000;
BA_REL_ "GenSigTimeoutTime" BU_SG_REL_ Kombi_LB SG_ 967 MO_KJS_nicht_bereit 800;
BA_REL_ "GenSigTimeoutTime" BU_SG_REL_ Kombi_LB SG_ 967 MO_ITM_Warnung_Pumpe 800;
BA_REL_ "GenSigTimeoutTime" BU_SG_REL_ Kombi_LB SG_ 967 WIV_Oelmin_Warn 800;
BA_REL_ "GenSigTimeoutTime" BU_SG_REL_ Kombi_LB SG_ 967 WIV_Sensorfehler 800;
BA_REL_ "GenSigTimeoutTime" BU_SG_REL_ Kombi_LB SG_ 967 WIV_Oelstand 800;
BA_REL_ "GenSigTimeoutTime" BU_SG_REL_ Kombi_LB SG_ 967 OLEV_Systemstoerung 800;
BA_REL_ "GenSigTimeoutTime" BU_SG_REL_ Kombi_LB SG_ 967 MO_Oelwarnung_max 800;
BA_REL_ "GenSigTimeoutTime" BU_SG_REL_ Kombi_LB SG_ 967 WIV_Oelsystem_aktiv 800;
BA_REL_ "GenSigTimeoutTime" BU_SG_REL_ Kombi_LB SG_ 967 WIV_Ueberfuell_Warn 800;
BA_REL_ "GenSigTimeoutTime" BU_SG_REL_ Kombi_LB SG_ 967 MO_E_Warnungen 800;
BA_REL_ "GenSigTimeoutTime" BU_SG_REL_ Kombi_LB SG_ 967 MO_Text_Motorstart 800;
BA_REL_ "GenSigTimeoutTime" BU_SG_REL_ Kombi_LB SG_ 967 MO_E_Texte 800;
BA_REL_ "GenSigTimeoutTime" BU_SG_REL_ Kombi_LB SG_ 967 MO_Text_Partikelfil_Reg 800;
BA_REL_ "GenSigTimeoutTime" BU_SG_REL_ Kombi_LB SG_ 967 OLEV_Oelstand_nicht_vorhanden 800;
BA_REL_ "GenSigTimeoutTime" BU_SG_REL_ Kombi_LB SG_ 967 WIV_Oelmenge 800;
BA_REL_ "GenSigTimeoutTime" BU_SG_REL_ Kombi_LB SG_ 967 MO_OBD2_Lampe 800;
BA_REL_ "GenSigTimeoutTime" BU_SG_REL_ Kombi_LB SG_ 967 MO_Heissleuchte 800;
BA_REL_ "GenSigTimeoutTime" BU_SG_REL_ Kombi_LB SG_ 967 MO_Partikel_Lampe 800;
BA_REL_ "GenSigTimeoutTime" BU_SG_REL_ Kombi_LB SG_ 967 MO_RedFahrleistung_Lampe 800;
BA_REL_ "GenSigTimeoutTime" BU_SG_REL_ Kombi_LB SG_ 967 WIV_Oelstand_nicht_vorhanden 800;
BA_REL_ "GenSigTimeoutTime" BU_SG_REL_ Kombi_LB SG_ 967 WIV_nachfuellanzeige_ein 800;
BA_REL_ "GenSigTimeoutTime" BU_SG_REL_ Kombi_LB SG_ 967 WIV_Ueberfuell_deaktiv 800;
BA_REL_ "GenSigTimeoutTime" BU_SG_REL_ Kombi_LB SG_ 967 WIV_Unterfuell_Warn 800;
BA_REL_ "GenSigTimeoutTime" BU_SG_REL_ Kombi_LB SG_ 967 MO_Text_Tankdeckelwarn 800;
BA_REL_ "GenSigTimeoutTime" BU_SG_REL_ Kombi_LB SG_ 967 MO_Vorglueh_Lampe 800;
BA_REL_ "GenSigTimeoutTime" BU_SG_REL_ Kombi_LB SG_ 967 WIV_Oeldr_Warn_Motor 800;
BA_REL_ "GenSigTimeoutTime" BU_SG_REL_ Kombi_LB SG_ 967 MO_E_Mode 800;
BA_REL_ "GenSigTimeoutTime" BU_SG_REL_ Kombi_LB SG_ 327 MO_Hochschaltdrehz 500;
BA_REL_ "GenSigTimeoutTime" BU_SG_REL_ Kombi_LB SG_ 327 MO_Anzeige_Verbr_Einheit 500;
BA_REL_ "GenSigTimeoutTime" BU_SG_REL_ Kombi_LB SG_ 327 MO_Schaltblitz_Anz 500;
BA_REL_ "GenSigTimeoutTime" BU_SG_REL_ Kombi_LB SG_ 327 MO_Anzeige_Drehmoment 500;
BA_REL_ "GenSigTimeoutTime" BU_SG_REL_ Kombi_LB SG_ 327 MO_Anzeige_Leistung 500;
BA_REL_ "GenSigTimeoutTime" BU_SG_REL_ Kombi_LB SG_ 1366 MO_Verbau_StartSys_Ritzelstarter 5000;
BA_REL_ "GenSigTimeoutTime" BU_SG_REL_ Kombi_LB SG_ 1366 MO_Verbau_StartSys_EM_MV 5000;
BA_REL_ "GenSigTimeoutTime" BU_SG_REL_ Kombi_LB SG_ 1366 MO_Verbau_StartSys_EM_HV 5000;
BA_REL_ "GenSigTimeoutTime" BU_SG_REL_ Kombi_LB SG_ 1366 MO_Verbau_StartSys_RSG_NV 5000;
BA_REL_ "GenSigTimeoutTime" BU_SG_REL_ Kombi_LB SG_ 1366 MO_Verbau_StartSys_Q_Diode 5000;
BA_REL_ "GenSigTimeoutTime" BU_SG_REL_ Kombi_LB SG_ 1366 MO_Verbau_StartSys_RSG_MV 5000;
BA_REL_ "GenSigTimeoutTime" BU_SG_REL_ Kombi_LB SG_ 283 MO_Freilauf_Status 5000;
BA_REL_ "GenSigTimeoutTime" BU_SG_REL_ Kombi_LB SG_ 2589283475 SCR_Zustand 5000;
BA_REL_ "GenSigTimeoutTime" BU_SG_REL_ Kombi_LB SG_ 834 MO_E_Texte_LB 800;
BA_REL_ "GenSigTimeoutTime" BU_SG_REL_ Kombi_LB SG_ 834 MO_Energyflow 800;
BA_REL_ "GenSigTimeoutTime" BU_SG_REL_ Kombi_LB SG_ 834 MO_Wassertemp_Schutz_Anf 800;
BA_REL_ "GenSigTimeoutTime" BU_SG_REL_ Kombi_LB SG_ 834 MO_Sperrung_FahrPr_BZS_LB 800;
BA_REL_ "GenSigTimeoutTime" BU_SG_REL_ Kombi_LB SG_ 834 MO_TorqueDistrib_Hi 800;
BA_REL_ "GenSigTimeoutTime" BU_SG_REL_ Kombi_LB SG_ 834 MO_TorqueDistrib_VL 800;
BA_REL_ "GenSigTimeoutTime" BU_SG_REL_ Kombi_LB SG_ 834 MO_TorqueDistrib_VR 800;
BA_REL_ "GenSigTimeoutTime" BU_SG_REL_ Kombi_LB SG_ 706 MO_Anzeige_StSt_Text 4000;
BA_REL_ "GenSigTimeoutTime" BU_SG_REL_ Kombi_LB SG_ 706 MO_Anzeige_StSt_Symbol 4000;
BA_REL_ "GenSigTimeoutTime" BU_SG_REL_ Kombi_LB SG_ 706 MO_AGA_Sound_Texte 4000;
BA_REL_ "GenSigTimeoutTime" BU_SG_REL_ Kombi_LB SG_ 706 PEA_Texte 4000;
BA_REL_ "GenSigTimeoutTime" BU_SG_REL_ Kombi_LB SG_ 706 TSK_Ueberstimmt_vMax_FahrerInfo 4000;
BA_REL_ "GenSigTimeoutTime" BU_SG_REL_ Kombi_LB SG_ 706 MO_Rekuperationsstufe 4000;
BA_REL_ "GenSigTimeoutTime" BU_SG_REL_ Kombi_LB SG_ 706 TSK_Einheit_vMax_FahrerInfo 4000;
BA_REL_ "GenSigTimeoutTime" BU_SG_REL_ Kombi_LB SG_ 706 TSK_Status_vMax_FahrerInfo 4000;
BA_REL_ "GenSigTimeoutTime" BU_SG_REL_ Kombi_LB SG_ 706 MO_Red_Fahrleistung 4000;
BA_REL_ "GenSigTimeoutTime" BU_SG_REL_ Kombi_LB SG_ 706 TSK_vMax_FahrerInfo 4000;
BA_REL_ "GenSigTimeoutTime" BU_SG_REL_ Kombi_LB SG_ 2589283599 MO_Kilometerstand_Wakeup 5000;
BA_REL_ "GenSigTimeoutTime" BU_SG_REL_ Kombi_LB SG_ 2589283599 MO_Eboost_LB_LVLavailable 5000;
BA_REL_ "GenSigTimeoutTime" BU_SG_REL_ Kombi_LB SG_ 2589283599 MO_Eboost_LB_possible 5000;
BA_REL_ "GenSigTimeoutTime" BU_SG_REL_ Kombi_LB SG_ 2589283599 MO_Eboost_LB_active 5000;
BA_REL_ "GenSigTimeoutTime" BU_SG_REL_ Kombi_LB SG_ 2589283599 MO_Eboost_LB_available 5000;
BA_REL_ "GenSigTimeoutTime" BU_SG_REL_ Kombi_LB SG_ 2589283599 MO_Eboost_LB_driveraction 5000;
BA_REL_ "GenSigTimeoutTime" BU_SG_REL_ Kombi_LB SG_ 2589283599 MO_Eboost_LB_failure 5000;
BA_REL_ "GenSigTimeoutTime" BU_SG_REL_ Kombi_LB SG_ 2589283599 MO_Eboost_LB_LVLselected 5000;
BA_REL_ "GenSigTimeoutTime" BU_SG_REL_ Kombi_LB SG_ 2589283599 MO_CatHeatBar_LB 5000;
BA_REL_ "GenSigTimeoutTime" BU_SG_REL_ Kombi_LB SG_ 1601 MO_Hybridfahrzeug 5000;
BA_REL_ "GenSigTimeoutTime" BU_SG_REL_ Kombi_LB SG_ 1601 MO_StartStopp_Codiert 5000;
BA_REL_ "GenSigTimeoutTime" BU_SG_REL_ Kombi_LB SG_ 1601 MO_Anzeige_StSt_gueltig 5000;
BA_REL_ "GenSigTimeoutTime" BU_SG_REL_ Kombi_LB SG_ 1601 MO_Kraftstoffart 5000;
BA_REL_ "GenSigTimeoutTime" BU_SG_REL_ Kombi_LB SG_ 813 MO_akt_Betrieb 500;
BA_REL_ "GenSigTimeoutTime" BU_SG_REL_ Kombi_LB SG_ 813 MO_Erdgasqualitaet 500;
BA_REL_ "GenSigTimeoutTime" BU_SG_REL_ Kombi_LB SG_ 813 MO_Verbrauchsaequivalent 500;
BA_REL_ "GenSigTimeoutTime" BU_SG_REL_ Kombi_LB SG_ 305 MO_ePowermeter 500;
BA_REL_ "GenSigTimeoutTime" BU_SG_REL_ Kombi_LB SG_ 305 MO_ePerformance 500;
BA_REL_ "GenSigTimeoutTime" BU_SG_REL_ Kombi_LB SG_ 305 MO_Zust_Antrieb 500;
BA_REL_ "GenSigTimeoutTime" BU_SG_REL_ Kombi_LB SG_ 305 MO_Zust_Betriebsstrategie 500;
BA_REL_ "GenSigTimeoutTime" BU_SG_REL_ Kombi_LB SG_ 305 Ladezustand_02 500;
BA_REL_ "GenSigTimeoutTime" BU_SG_REL_ Kombi_LB SG_ 305 MO_Powermeter_Elm 500;
BA_REL_ "GenSigTimeoutTime" BU_SG_REL_ Kombi_LB SG_ 305 MO_Powermeter_Elm_02 500;
BA_REL_ "GenSigTimeoutTime" BU_SG_REL_ Kombi_LB SG_ 305 MO_Powermeter 500;
BA_REL_ "GenSigTimeoutTime" BU_SG_REL_ Kombi_LB SG_ 1376 MO_Tankbereitschaft_Status 1600;
BA_REL_ "GenSigTimeoutTime" BU_SG_REL_ Kombi_PAG SG_ 1607 MO_ITM_Kuehlmittel_Temp 3200;
BA_REL_ "GenSigTimeoutTime" BU_SG_REL_ Kombi_PAG SG_ 1607 SCR_Text 3200;
BA_REL_ "GenSigTimeoutTime" BU_SG_REL_ Kombi_PAG SG_ 1607 SCR_verbaut 3200;
BA_REL_ "GenSigTimeoutTime" BU_SG_REL_ Kombi_PAG SG_ 1607 MO_Kraftstofffilter_Wasser 3200;
BA_REL_ "GenSigTimeoutTime" BU_SG_REL_ Kombi_PAG SG_ 1607 SCR_Inducement_Strategie 3200;
BA_REL_ "GenSigTimeoutTime" BU_SG_REL_ Kombi_PAG SG_ 1607 MO_MKB_MUX 3200;
BA_REL_ "GenSigTimeoutTime" BU_SG_REL_ Kombi_PAG SG_ 1607 MO_MKB_01 3200;
BA_REL_ "GenSigTimeoutTime" BU_SG_REL_ Kombi_PAG SG_ 1607 MO_MKB_02 3200;
BA_REL_ "GenSigTimeoutTime" BU_SG_REL_ Kombi_PAG SG_ 1607 MO_MKB_03 3200;
BA_REL_ "GenSigTimeoutTime" BU_SG_REL_ Kombi_PAG SG_ 1607 MO_MKB_04 3200;
BA_REL_ "GenSigTimeoutTime" BU_SG_REL_ Kombi_PAG SG_ 168 MO_Drehzahl_01 500;
BA_REL_ "GenSigTimeoutTime" BU_SG_REL_ Kombi_PAG SG_ 958 Motor_14_CRC 1000;
BA_REL_ "GenSigTimeoutTime" BU_SG_REL_ Kombi_PAG SG_ 958 Motor_14_BZ 1000;
BA_REL_ "GenSigTimeoutTime" BU_SG_REL_ Kombi_PAG SG_ 958 MO_StartStopp_Wiederstart 1000;
BA_REL_ "GenSigTimeoutTime" BU_SG_REL_ Kombi_PAG SG_ 958 MO_StartStopp_Motorstopp 1000;
BA_REL_ "GenSigTimeoutTime" BU_SG_REL_ Kombi_PAG SG_ 958 MO_Kl_75 1000;
BA_REL_ "GenSigTimeoutTime" BU_SG_REL_ Kombi_PAG SG_ 958 MO_Gangposition 1000;
BA_REL_ "GenSigTimeoutTime" BU_SG_REL_ Kombi_PAG SG_ 958 MO_HYB_Fahrbereitschaft 1000;
BA_REL_ "GenSigTimeoutTime" BU_SG_REL_ Kombi_PAG SG_ 958 MO_Ext_E_Fahrt_aktiv 1000;
BA_REL_ "GenSigTimeoutTime" BU_SG_REL_ Kombi_PAG SG_ 958 MO_Motor_laeuft 1000;
BA_REL_ "GenSigTimeoutTime" BU_SG_REL_ Kombi_PAG SG_ 958 MO_Text_Geschw_red 1000;
BA_REL_ "GenSigTimeoutTime" BU_SG_REL_ Kombi_PAG SG_ 958 MO_HYB_VM_aktiv 1000;
BA_REL_ "GenSigTimeoutTime" BU_SG_REL_ Kombi_PAG SG_ 1631 MO_Anzeige_Kaltleuchte 3200;
BA_REL_ "GenSigTimeoutTime" BU_SG_REL_ Kombi_PAG SG_ 1631 MO_Energieinhalt_BMS 3200;
BA_REL_ "GenSigTimeoutTime" BU_SG_REL_ Kombi_PAG SG_ 812 MO_MAX_Wunschdrehzahl 2000;
BA_REL_ "GenSigTimeoutTime" BU_SG_REL_ Kombi_PAG SG_ 1648 MO_max_Ladedruck 5000;
BA_REL_ "GenSigTimeoutTime" BU_SG_REL_ Kombi_PAG SG_ 1648 MO_StartStopp_PopUp 5000;
BA_REL_ "GenSigTimeoutTime" BU_SG_REL_ Kombi_PAG SG_ 1648 MO_EPCL 5000;
BA_REL_ "GenSigTimeoutTime" BU_SG_REL_ Kombi_PAG SG_ 1648 MO_Fahrzeugtyp 5000;
BA_REL_ "GenSigTimeoutTime" BU_SG_REL_ Kombi_PAG SG_ 1648 MO_Ethanol_BS_Texte 5000;
BA_REL_ "GenSigTimeoutTime" BU_SG_REL_ Kombi_PAG SG_ 1648 MO_Drehzahl_Warnung 5000;
BA_REL_ "GenSigTimeoutTime" BU_SG_REL_ Kombi_PAG SG_ 1648 MO_obere_Drehzahlgrenze 5000;
BA_REL_ "GenSigTimeoutTime" BU_SG_REL_ Kombi_PAG SG_ 815 MO_Anzeige_Fahrbereitschaft 500;
BA_REL_ "GenSigTimeoutTime" BU_SG_REL_ Kombi_PAG SG_ 815 MO_Boost_verfuegbar 500;
BA_REL_ "GenSigTimeoutTime" BU_SG_REL_ Kombi_PAG SG_ 815 MO_Overboost 500;
BA_REL_ "GenSigTimeoutTime" BU_SG_REL_ Kombi_PAG SG_ 815 MO_Boost_aktiv 500;
BA_REL_ "GenSigTimeoutTime" BU_SG_REL_ Kombi_PAG SG_ 815 MO_Anzeige_Betriebsmodus 500;
BA_REL_ "GenSigTimeoutTime" BU_SG_REL_ Kombi_PAG SG_ 815 PEA_Hinweis 500;
BA_REL_ "GenSigTimeoutTime" BU_SG_REL_ Kombi_PAG SG_ 815 PEA_Ereignisanzeige 500;
BA_REL_ "GenSigTimeoutTime" BU_SG_REL_ Kombi_PAG SG_ 815 PEA_Ereignisanzeige_temporaer 500;
BA_REL_ "GenSigTimeoutTime" BU_SG_REL_ Kombi_PAG SG_ 815 PEA_Abschalttexte 500;
BA_REL_ "GenSigTimeoutTime" BU_SG_REL_ Kombi_PAG SG_ 815 PEA_Zielgeschw_Einheit 500;
BA_REL_ "GenSigTimeoutTime" BU_SG_REL_ Kombi_PAG SG_ 815 PEA_Zielgeschw 500;
BA_REL_ "GenSigTimeoutTime" BU_SG_REL_ Kombi_PAG SG_ 815 MO_Antriebsstrang_Warnung_HS 500;
BA_REL_ "GenSigTimeoutTime" BU_SG_REL_ Kombi_PAG SG_ 815 MO_Anzeige_Verbrauch_oE 500;
BA_REL_ "GenSigTimeoutTime" BU_SG_REL_ Kombi_PAG SG_ 1391 MO_Anzeige_Aufheizfortschritt 5000;
BA_REL_ "GenSigTimeoutTime" BU_SG_REL_ Kombi_PAG SG_ 1391 MO_Anzeige_Leistung_Max 5000;
BA_REL_ "GenSigTimeoutTime" BU_SG_REL_ Kombi_PAG SG_ 1391 MO_Anzeige_Drehmoment_Max 5000;
BA_REL_ "GenSigTimeoutTime" BU_SG_REL_ Kombi_PAG SG_ 967 MO_KJS_nicht_bereit 800;
BA_REL_ "GenSigTimeoutTime" BU_SG_REL_ Kombi_PAG SG_ 967 MO_ITM_Warnung_Pumpe 800;
BA_REL_ "GenSigTimeoutTime" BU_SG_REL_ Kombi_PAG SG_ 967 WIV_Oelmin_Warn 800;
BA_REL_ "GenSigTimeoutTime" BU_SG_REL_ Kombi_PAG SG_ 967 WIV_Sensorfehler 800;
BA_REL_ "GenSigTimeoutTime" BU_SG_REL_ Kombi_PAG SG_ 967 WIV_Schieflage 800;
BA_REL_ "GenSigTimeoutTime" BU_SG_REL_ Kombi_PAG SG_ 967 WIV_Oelstand 800;
BA_REL_ "GenSigTimeoutTime" BU_SG_REL_ Kombi_PAG SG_ 967 OLEV_Systemstoerung 800;
BA_REL_ "GenSigTimeoutTime" BU_SG_REL_ Kombi_PAG SG_ 967 MO_Oelwarnung_max 800;
BA_REL_ "GenSigTimeoutTime" BU_SG_REL_ Kombi_PAG SG_ 967 WIV_Oelsystem_aktiv 800;
BA_REL_ "GenSigTimeoutTime" BU_SG_REL_ Kombi_PAG SG_ 967 WIV_nicht_betriebswarm 800;
BA_REL_ "GenSigTimeoutTime" BU_SG_REL_ Kombi_PAG SG_ 967 WIV_Ueberfuell_Warn 800;
BA_REL_ "GenSigTimeoutTime" BU_SG_REL_ Kombi_PAG SG_ 967 MO_E_Warnungen 800;
BA_REL_ "GenSigTimeoutTime" BU_SG_REL_ Kombi_PAG SG_ 967 MO_Text_Motorstart 800;
BA_REL_ "GenSigTimeoutTime" BU_SG_REL_ Kombi_PAG SG_ 967 MO_E_Texte 800;
BA_REL_ "GenSigTimeoutTime" BU_SG_REL_ Kombi_PAG SG_ 967 MO_Text_Partikelfil_Reg 800;
BA_REL_ "GenSigTimeoutTime" BU_SG_REL_ Kombi_PAG SG_ 967 OLEV_Oelstand_nicht_vorhanden 800;
BA_REL_ "GenSigTimeoutTime" BU_SG_REL_ Kombi_PAG SG_ 967 WIV_Oelmenge 800;
BA_REL_ "GenSigTimeoutTime" BU_SG_REL_ Kombi_PAG SG_ 967 MO_OBD2_Lampe 800;
BA_REL_ "GenSigTimeoutTime" BU_SG_REL_ Kombi_PAG SG_ 967 MO_Heissleuchte 800;
BA_REL_ "GenSigTimeoutTime" BU_SG_REL_ Kombi_PAG SG_ 967 MO_Partikel_Lampe 800;
BA_REL_ "GenSigTimeoutTime" BU_SG_REL_ Kombi_PAG SG_ 967 MO_RedFahrleistung_Lampe 800;
BA_REL_ "GenSigTimeoutTime" BU_SG_REL_ Kombi_PAG SG_ 967 WIV_Oelstand_nicht_vorhanden 800;
BA_REL_ "GenSigTimeoutTime" BU_SG_REL_ Kombi_PAG SG_ 967 WIV_nachfuellanzeige_ein 800;
BA_REL_ "GenSigTimeoutTime" BU_SG_REL_ Kombi_PAG SG_ 967 WIV_Ueberfuell_deaktiv 800;
BA_REL_ "GenSigTimeoutTime" BU_SG_REL_ Kombi_PAG SG_ 967 WIV_Unterfuell_Warn 800;
BA_REL_ "GenSigTimeoutTime" BU_SG_REL_ Kombi_PAG SG_ 967 MO_Vorglueh_Lampe 800;
BA_REL_ "GenSigTimeoutTime" BU_SG_REL_ Kombi_PAG SG_ 967 WIV_Oeldr_Warn_Motor 800;
BA_REL_ "GenSigTimeoutTime" BU_SG_REL_ Kombi_PAG SG_ 967 MO_E_Mode 800;
BA_REL_ "GenSigTimeoutTime" BU_SG_REL_ Kombi_PAG SG_ 327 MO_eATL_Status_Anzeige 500;
BA_REL_ "GenSigTimeoutTime" BU_SG_REL_ Kombi_PAG SG_ 327 MO_Anzeige_Kaltabfahrbegrenzung 500;
BA_REL_ "GenSigTimeoutTime" BU_SG_REL_ Kombi_PAG SG_ 327 MO_Schaltblitz_Anz 500;
BA_REL_ "GenSigTimeoutTime" BU_SG_REL_ Kombi_PAG SG_ 327 MO_Anzeige_Drehmoment 500;
BA_REL_ "GenSigTimeoutTime" BU_SG_REL_ Kombi_PAG SG_ 327 MO_Anzeige_Leistung 500;
BA_REL_ "GenSigTimeoutTime" BU_SG_REL_ Kombi_PAG SG_ 1366 MO_Verbau_StartSys_Ritzelstarter 5000;
BA_REL_ "GenSigTimeoutTime" BU_SG_REL_ Kombi_PAG SG_ 1366 MO_Verbau_StartSys_EM_MV 5000;
BA_REL_ "GenSigTimeoutTime" BU_SG_REL_ Kombi_PAG SG_ 1366 MO_Verbau_StartSys_EM_HV 5000;
BA_REL_ "GenSigTimeoutTime" BU_SG_REL_ Kombi_PAG SG_ 1366 MO_Verbau_StartSys_RSG_NV 5000;
BA_REL_ "GenSigTimeoutTime" BU_SG_REL_ Kombi_PAG SG_ 1366 MO_Verbau_StartSys_Q_Diode 5000;
BA_REL_ "GenSigTimeoutTime" BU_SG_REL_ Kombi_PAG SG_ 1366 MO_Verbau_StartSys_RSG_MV 5000;
BA_REL_ "GenSigTimeoutTime" BU_SG_REL_ Kombi_PAG SG_ 1366 MO_Oelstand_Sens_roh 5000;
BA_REL_ "GenSigTimeoutTime" BU_SG_REL_ Kombi_PAG SG_ 283 MO_Rennstart_verf 5000;
BA_REL_ "GenSigTimeoutTime" BU_SG_REL_ Kombi_PAG SG_ 2589283475 SCR_Zustand 5000;
BA_REL_ "GenSigTimeoutTime" BU_SG_REL_ Kombi_PAG SG_ 2589283475 SCR_Retriggersignal 5000;
BA_REL_ "GenSigTimeoutTime" BU_SG_REL_ Kombi_PAG SG_ 2589283475 SCR_Nachfuellmenge_min 5000;
BA_REL_ "GenSigTimeoutTime" BU_SG_REL_ Kombi_PAG SG_ 2589283475 SCR_Nachfuellmenge_max 5000;
BA_REL_ "GenSigTimeoutTime" BU_SG_REL_ Kombi_PAG SG_ 2589283475 SCR_Nachfuellmenge_Einheit 5000;
BA_REL_ "GenSigTimeoutTime" BU_SG_REL_ Kombi_PAG SG_ 2589283475 SCR_Tankvolumen 5000;
BA_REL_ "GenSigTimeoutTime" BU_SG_REL_ Kombi_PAG SG_ 2589283475 SCR_Einheit 5000;
BA_REL_ "GenSigTimeoutTime" BU_SG_REL_ Kombi_PAG SG_ 2589283475 SCR_Fuellstand 5000;
BA_REL_ "GenSigTimeoutTime" BU_SG_REL_ Kombi_PAG SG_ 2589283475 SCR_Restreichweite 5000;
BA_REL_ "GenSigTimeoutTime" BU_SG_REL_ Kombi_PAG SG_ 706 MO_Anzeige_StSt_Text 4000;
BA_REL_ "GenSigTimeoutTime" BU_SG_REL_ Kombi_PAG SG_ 706 MO_Anzeige_StSt_Symbol 4000;
BA_REL_ "GenSigTimeoutTime" BU_SG_REL_ Kombi_PAG SG_ 706 MO_Fehler_MSpG 4000;
BA_REL_ "GenSigTimeoutTime" BU_SG_REL_ Kombi_PAG SG_ 706 PEA_Texte 4000;
BA_REL_ "GenSigTimeoutTime" BU_SG_REL_ Kombi_PAG SG_ 706 TSK_Ueberstimmt_vMax_FahrerInfo 4000;
BA_REL_ "GenSigTimeoutTime" BU_SG_REL_ Kombi_PAG SG_ 706 MO_Avus_Motorschutz 4000;
BA_REL_ "GenSigTimeoutTime" BU_SG_REL_ Kombi_PAG SG_ 706 MO_Rekuperationsstufe 4000;
BA_REL_ "GenSigTimeoutTime" BU_SG_REL_ Kombi_PAG SG_ 706 TSK_Einheit_vMax_FahrerInfo 4000;
BA_REL_ "GenSigTimeoutTime" BU_SG_REL_ Kombi_PAG SG_ 706 TSK_Status_vMax_FahrerInfo 4000;
BA_REL_ "GenSigTimeoutTime" BU_SG_REL_ Kombi_PAG SG_ 706 MO_Red_Fahrleistung 4000;
BA_REL_ "GenSigTimeoutTime" BU_SG_REL_ Kombi_PAG SG_ 706 MO_Oel_Temp_Radsatz_Warn 4000;
BA_REL_ "GenSigTimeoutTime" BU_SG_REL_ Kombi_PAG SG_ 706 MO_im_Leerlauf 4000;
BA_REL_ "GenSigTimeoutTime" BU_SG_REL_ Kombi_PAG SG_ 706 WIV_Enable_Oeldr_Motor 4000;
BA_REL_ "GenSigTimeoutTime" BU_SG_REL_ Kombi_PAG SG_ 706 MO_OelMessung_Dauer 4000;
BA_REL_ "GenSigTimeoutTime" BU_SG_REL_ Kombi_PAG SG_ 706 TSK_vMax_FahrerInfo 4000;
BA_REL_ "GenSigTimeoutTime" BU_SG_REL_ Kombi_PAG SG_ 1601 MO_StartStopp_Codiert 5000;
BA_REL_ "GenSigTimeoutTime" BU_SG_REL_ Kombi_PAG SG_ 1601 MO_Anzeige_StSt_gueltig 5000;
BA_REL_ "GenSigTimeoutTime" BU_SG_REL_ Kombi_PAG SG_ 1601 MO_Kraftstoffart 5000;
BA_REL_ "GenSigTimeoutTime" BU_SG_REL_ Kombi_PAG SG_ 305 MO_ePowermeter 500;
BA_REL_ "GenSigTimeoutTime" BU_SG_REL_ Kombi_PAG SG_ 305 MO_ePerformance 500;
BA_REL_ "GenSigTimeoutTime" BU_SG_REL_ Kombi_PAG SG_ 305 MO_Zust_Antrieb 500;
BA_REL_ "GenSigTimeoutTime" BU_SG_REL_ Kombi_PAG SG_ 305 MO_Zust_Betriebsstrategie 500;
BA_REL_ "GenSigTimeoutTime" BU_SG_REL_ Kombi_PAG SG_ 305 Ladezustand_02 500;
BA_REL_ "GenSigTimeoutTime" BU_SG_REL_ Kombi_PAG SG_ 305 MO_Powermeter_Elm 500;
BA_REL_ "GenSigTimeoutTime" BU_SG_REL_ Kombi_PAG SG_ 305 MO_Powermeter_Elm_02 500;
BA_REL_ "GenSigTimeoutTime" BU_SG_REL_ Kombi_PAG SG_ 305 MO_Powermeter 500;
BA_REL_ "GenSigTimeoutTime" BU_SG_REL_ Kombi_PAG SG_ 1376 MO_Tankbereitschaft_Status 1600;
BA_REL_ "GenSigTimeoutTime" BU_SG_REL_ Waehlhebel_SB SG_ 958 MO_StartStopp_Wiederstart 1000;
BA_REL_ "GenSigTimeoutTime" BU_SG_REL_ Waehlhebel_SB SG_ 958 MO_Kl_75 1000;
BA_REL_ "GenSigTimeoutTime" BU_SG_REL_ Waehlhebel_SB SG_ 958 MO_QBit_KL_75 1000;
VAL_ 1607 MO_ITM_Kuehlmittel_Temp 0 "nicht_verbaut" 1 "Init" 2 "Fehler" ;
VAL_ 1607 MO_E85_Sensor 13 "nicht_verbaut" 14 "Init" 15 "Fehler" ;
VAL_ 1607 SCR_Anz_Motorstarts 0 "Anzahl_moeglicher_Restarts" 1 "Anzahl_moeglicher_Restarts" 2 "Anzahl_moeglicher_Restarts" 3 "Anzahl_moeglicher_Restarts" 4 "Anzahl_moeglicher_Restarts" 5 "Anzahl_moeglicher_Restarts" 6 "Anzahl_moeglicher_Restarts" 7 "Anzahl_moeglicher_Restarts" 8 "Anzahl_moeglicher_Restarts" 9 "Anzahl_moeglicher_Restarts" 10 "Anzahl_moeglicher_Restarts" 11 "Anzahl_moeglicher_Restarts" 12 "Anzahl_moeglicher_Restarts" 13 "Anzahl_moeglicher_Restarts" 14 "Fahrbarkeitseinschraenkung" 15 "keine_Einschraenkung" ;
VAL_ 1607 SCR_Reichweite 32767 "keine_Anzeige" ;
VAL_ 1607 MO_Ethanol_Spuelhinweis 0 "Kein_Hinweis" 1 "Spuelhinweis_aktiv" ;
VAL_ 1607 SCR_Warnstufe_1 0 "nicht_aktiv" 1 "Warnstufe_1_aktiv" ;
VAL_ 1607 SCR_Warnstufe_2 0 "nicht_aktiv" 1 "Warnstufe_2_aktiv" ;
VAL_ 1607 SCR_Text 0 "kein_Text" 1 "Warntext_1" 2 "Warntext_2" 3 "Hinweis_Fuellstand" 4 "Reserve" 5 "SysFehler_1" 6 "SysFehler_2" 7 "Hinweis_Systemfehler" ;
VAL_ 1607 SCR_Akustik 0 "keine_Akustik" 1 "Akustik_1" 2 "Akustik_2" 3 "Akustik_bei_Hinweis" ;
VAL_ 1607 SCR_verbaut 0 "kein_SCR" 1 "SCR_verbaut" ;
VAL_ 1607 MO_Kraftstofffilter_Wasser 0 "keine_Anzeige" 1 "Abscheidevolumen_erschoepft" ;
VAL_ 1607 SCR_Systemfehler 0 "Warnung_nicht_aktiv" 1 "Warnung_aktiv" ;
VAL_ 1607 SCR_Inducement_Strategie 0 "Restart_Strategie" 1 "Reduced_Drivability_Strategie" ;
VAL_ 1607 MO_CO2_Faktor 0 "nicht_verbaut" 4095 "Fehler" ;
VAL_ 1607 MO_MKB_MUX 0 "MKB_01" 1 "MKB_02" 2 "MKB_03" 3 "MKB_04" ;
VAL_ 1607 MO_MKB_01 0 "Minus" 1 "A" 2 "B" 3 "C" 4 "D" 5 "E" 6 "F" 7 "G" 8 "H" 9 "I" 10 "J" 11 "K" 12 "L" 13 "M" 14 "N" 15 "O" 16 "P" 17 "Q" 18 "R" 19 "S" 20 "T" 21 "U" 22 "V" 23 "W" 24 "X" 25 "Y" 26 "Z" 27 "Leerzeichen" 28 "Leerzeichen" 29 "Leerzeichen" 30 "Leerzeichen" 31 "Unterstrich" ;
VAL_ 1607 MO_MKB_02 0 "Minus" 1 "A" 2 "B" 3 "C" 4 "D" 5 "E" 6 "F" 7 "G" 8 "H" 9 "I" 10 "J" 11 "K" 12 "L" 13 "M" 14 "N" 15 "O" 16 "P" 17 "Q" 18 "R" 19 "S" 20 "T" 21 "U" 22 "V" 23 "W" 24 "X" 25 "Y" 26 "Z" 27 "Leerzeichen" 28 "Leerzeichen" 29 "Leerzeichen" 30 "Leerzeichen" 31 "Unterstrich" ;
VAL_ 1607 MO_MKB_03 0 "Minus" 1 "A" 2 "B" 3 "C" 4 "D" 5 "E" 6 "F" 7 "G" 8 "H" 9 "I" 10 "J" 11 "K" 12 "L" 13 "M" 14 "N" 15 "O" 16 "P" 17 "Q" 18 "R" 19 "S" 20 "T" 21 "U" 22 "V" 23 "W" 24 "X" 25 "Y" 26 "Z" 27 "Leerzeichen" 28 "Leerzeichen" 29 "Leerzeichen" 30 "Leerzeichen" 31 "Unterstrich" ;
VAL_ 1607 MO_MKB_04 0 "Minus" 1 "A" 2 "B" 3 "C" 4 "D" 5 "E" 6 "F" 7 "G" 8 "H" 9 "I" 10 "J" 11 "K" 12 "L" 13 "M" 14 "N" 15 "O" 16 "P" 17 "Q" 18 "R" 19 "S" 20 "T" 21 "U" 22 "V" 23 "W" 24 "X" 25 "Y" 26 "Z" 27 "Leerzeichen" 28 "Leerzeichen" 29 "Leerzeichen" 30 "Leerzeichen" 31 "Unterstrich" ;
VAL_ 168 MO_Mom_neg_verfuegbar 510 "Init" 511 "Fehler" ;
VAL_ 168 MO_Mom_Begr_stat 510 "Init" ;
VAL_ 168 MO_Mom_Begr_dyn 1022 "Init" ;
VAL_ 168 MO_QBit_Drehzahl_01 0 "gueltiger_Wert" 1 "Ersatz_Init_oder_Fehlerwert" ;
VAL_ 958 MO_StartStopp_Status 0 "System_in_diesem_KL15_Zyklus_nicht_verfuegbar" 1 "System_aktiv_keine_Freigabe_durch_StartStop_Koordinator" 2 "System_aktiv_alle_Freigaben_liegen_vor" 3 "System_aktiv_mindestens_eine_Freigabe_fehlt" ;
VAL_ 958 MO_StartStopp_Wiederstart 0 "Wiederstart_inaktiv" 1 "Wiederstart_aktiv" ;
VAL_ 958 MO_StartStopp_Motorstopp 0 "Motor_Stop_inaktiv" 1 "Motor_Stop_aktiv" ;
VAL_ 958 MO_Freig_Reku 0 "Rekuperations-Modus aus" 1 "Empfehlung Spannungsanhebung" 2 "Empfehlung Spannungsabsenkung" 3 "Rekuperationsmodus aktiv, Spannungsvariation nicht notwendig" ;
VAL_ 958 MO_Kl_75 0 "Aus" 1 "Ein" ;
VAL_ 958 MO_Kl_50 0 "aus" 1 "KL50_ein_Startausfuehrung_Fahrer" ;
VAL_ 958 MO_Gangposition 0 "Gang_N" 1 "Gang_1" 2 "Gang_2" 3 "Gang_3" 4 "Gang_4" 5 "Gang_5" 6 "Gang_6" 7 "Gang_7" 8 "Gang_8" 9 "Automat_P" 10 "Automat_Vorwaerts_S" 11 "Automat_Vorwaerts_D/E" 12 "Zwischenstellung" 13 "Gang_R" 14 "Istgang_nicht_definiert" 15 "Fehler" ;
VAL_ 958 MO_StartStopp_Fahrerwunsch 0 "Init" 1 "Stoppverbot_durch_Fahrer" 2 "Stoppfreigabe_durch_Fahrer" 3 "Stoppanforderung_durch_Fahrer" ;
VAL_ 958 MO_HYB_Fahrbereitschaft 0 "keine_Fahrbereitschaft" 1 "Fahrbereitschaft" ;
VAL_ 958 MO_Ext_E_Fahrt_aktiv 0 "Rueckmeldung_E_Taster_aus" 1 "Rueckmeldung_E_Taster_ein" ;
VAL_ 958 MO_Fahrer_bremst 0 "kein_Bremsen" 1 "Bremse_betaetigt" ;
VAL_ 958 MO_QBit_Fahrer_bremst 0 "gueltiger_Wert" 1 "Ersatz_Init_oder_Fehlerwert" ;
VAL_ 958 MO_BLS 0 "kein_Bremsen" 1 "Bremse_betaetigt" ;
VAL_ 958 MO_Konsistenz_Bremsped 0 "Bremspedalinformation_plausibel" 1 "Bremspedalinformation_unplausibel" ;
VAL_ 958 MO_KomFehler_ESP 0 "kein_Fehler" 1 "Fehler" ;
VAL_ 958 MO_Klima_Eingr 0 "kein Eingriff" 1 "Klimakompressor ausschalten" 2 "Klimakompressor Leistungsreduzierung" 3 "Klimakompressor aufgrund der Heissleuchtenvorwarnung ausschalten" ;
VAL_ 958 MO_Aussp_Anlass 0 "Anlasser_darf_angesteuert_werden" 1 "Anlasser_ausspuren__Ansteuerung_nicht_moeglich" ;
VAL_ 958 MO_Freig_Anlass 0 "Start_nicht_zulaessig" 1 "Startfreigabe" ;
VAL_ 958 MO_Kuppl_schalter 0 "Schalter_sagt_ausgekuppelt" 1 "Schalter_sagt_eingekuppelt" ;
VAL_ 958 MO_Interlock 0 "Interlockschalter_nicht_betaetigt" 1 "Interlockschalter_betaetigt" ;
VAL_ 958 MO_Motor_laeuft 0 "Motor_laeuft_nicht" 1 "Motor_laeuft_autark_und_stabil_und_darf_mechanisch_belastet_werden" ;
VAL_ 958 MO_Kickdown 0 "kein_Kickdown" 1 "Kickdown" ;
VAL_ 958 MO_QBit_KL_75 0 "gueltiger_Wert" 1 "Ersatz_Init_oder_Fehlerwert" ;
VAL_ 958 MO_EKlKomLeiRed 0 "keine_Leistungsbegr" 1 "Leistungsbegr_75" 2 "Leistungsbegr_50" 3 "Leistungsbegr_25" ;
VAL_ 958 MO_Handshake_STH 0 "keine EKP-Ansteuerung durch STH-Anforderung" 1 "EKP-Ansteuerung durch STH-Anforderung" ;
VAL_ 958 MO_BKV_Unterdruckwarnung 0 "Unterdruckhaushalt_iO" 1 "Unterdruckhaushalt_niO" ;
VAL_ 958 MO_Freigabe_Segeln 0 "Segelbetrieb_nicht_freigegeben" 1 "Segelbetrieb_freigegeben" ;
VAL_ 958 MO_PTC_Status 0 "nicht_unterstuetzt" 1 "Stufe_0" 2 "Stufe_1" 3 "Stufe_2" 4 "Stufe_3" 7 "PTC_am_BCM" ;
VAL_ 958 MO_QBit_Gangposition 0 "gueltiger_Wert" 1 "Ersatz_Init_oder_Fehlerwert" ;
VAL_ 958 MO_Signalquelle_Gangposition 0 "Sensorsignal" 1 "Modellsignal" ;
VAL_ 958 MO_Remotestart_Betrieb 0 "MSG_nicht_bereit_fuer_RS_Betrieb" 1 "MSG_bereit_fuer_oder_im_RS_Betrieb" ;
VAL_ 958 MO_Remotestart_moeglich 0 "Remotestart_nicht_moeglich" 1 "Remotestart_moeglich" ;
VAL_ 958 MO_Text_Geschw_red 0 "keine_Anzeige" 1 "Anzeige_Geschwindigkeitsred" ;
VAL_ 958 MO_FMAus_aktiv 0 "inaktiv" 1 "Segeln_mit_Motor_aus_aktiv" ;
VAL_ 958 MO_FMAus_Startvariante 0 "kein_Motorstart" 1 "Motorstart_elektrischer_Starter" 2 "GetriebeAnschleppstart" 3 "GetriebeNotAnschleppstart" ;
VAL_ 958 MO_BMS_NV_Anf_stuetzen 0 "nicht_notwendig" 1 "notwendig" ;
VAL_ 958 MO_Zylinderabschaltung 0 "Vollmotorbetrieb_VMB" 1 "Uebergang_HMB_in_VMB" 2 "Uebergang_VMB_in_HMB" 3 "Halbmotorbetrieb_HMB" ;
VAL_ 958 MO_HYB_VM_aktiv 0 "VM_nicht_aktiv" 1 "VM_aktiv" ;
VAL_ 958 MO_StartVorauss_erfuellt 0 "Signal_nicht_bedient" 1 "StartVorauss_nicht_ueberpruefbar" 2 "StartVorauss_nicht_erfuellt" 3 "StartVorauss_erfuellt" ;
VAL_ 1631 TSK_QBit_Steigung 0 "gueltiger_Wert" 1 "Ersatz_Init_oder_Fehlerwert" ;
VAL_ 1631 TSK_QBit_Fahrzeugmasse 0 "gueltiger_Wert" 1 "Ersatz_Init_oder_Fehlerwert" ;
VAL_ 1631 MO_SpannungsAnf_02 0 "keine_Anforderung" 1 "Anforderung_Stufe_1" 2 "Anforderung_Stufe_2" 3 "Anforderung_Stufe_3" ;
VAL_ 1631 MO_DPF_reg 0 "DPF_regeneriert_nicht" 1 "DPF_regeneriert" ;
VAL_ 1631 MO_Heizstrom_EKAT 127 "Fehler" ;
VAL_ 1631 MO_Heizstrom_SCR 63 "Fehler" ;
VAL_ 1631 MO_Anzeige_Kaltleuchte 0 "Lampe_aus" 1 "Lampe_an" ;
VAL_ 1631 MO_P_Generator_ungefiltert_Anf 0 "nicht_angefordert" 1 "angefordert" ;
VAL_ 1631 TSK_Getriebeinfo 0 "Handschalter" 1 "AL_AQ_Getriebe" 2 "DL_DQ_Getriebe" 3 "CVT_Getriebe" ;
VAL_ 1631 MO_Energieinhalt_BMS 4094 "Init" 4095 "Fehler" ;
VAL_ 1631 TSK_Fahrzeugmasse_02 255 "Fehler" ;
VAL_ 1631 TSK_Steigung_02 0 "Init_oder_nicht_verbaut" 255 "Fehler" ;
VAL_ 812 MO_Sperrung_FahrPr_BZS 0 "keine Sperrung" 1 "Sperrung BZS1" 2 "Sperrung BZS2" 4 "Sperrung BZS3" 8 "Sperrung BZS4" 16 "Sperrung BZS5" 32 "Sperrung BZS6" 64 "Sperrung BZS7" 128 "Sperrung BZS8" ;
VAL_ 812 MO_Rampenzeit_Generator_Anf 0 "0_sec" 1 "1_sec" 2 "2_sec" 3 "3_sec" 4 "4_sec" 5 "5_sec" 6 "6_sec" 7 "7_sec" 8 "8_sec" 9 "9_sec" 10 "reserviert" 11 "reserviert" 12 "reserviert" 13 "reserviert" 14 "reserviert" 15 "keine_Anforderung" ;
VAL_ 812 MO_Prio_MAX_Wunschdrehzahl 0 "Wunsch" 1 "Zwang" ;
VAL_ 812 MO_Prio_MIN_Wunschdrehzahl 0 "Wunsch" 1 "Zwang" ;
VAL_ 812 MO_Luftpfad_aktiv 0 "kein Eingriff oder nur Eingriff über Zündpfad" 1 "Eingriff über Luftpfad" ;
VAL_ 812 MO_v_Begrenz_Aktivierbar 0 "V-Begrenzung nicht möglich" 1 "V-Begrenzung möglich" ;
VAL_ 812 MO_Charisma_FahrPr 0 "keine_Funktion" 1 "Programm_1" 2 "Programm_2" 3 "Programm_3" 4 "Programm_4" 5 "Programm_5" 6 "Programm_6" 7 "Programm_7" 8 "Programm_8" 9 "Programm_9" 10 "Programm_10" 11 "Programm_11" 12 "Programm_12" 13 "Programm_13" 14 "Programm_14" 15 "Programm_15" ;
VAL_ 812 MO_Charisma_Status 0 "Init" 1 "verfuegbar" 2 "nicht_verfuegbar" 3 "asynchron_durch_Fahrerwunsch" ;
VAL_ 812 MO_StSt_Charisma_FahrPr 0 "keine_Funktion" 1 "Programm_1" 2 "Programm_2" 3 "Programm_3" 4 "Programm_4" 5 "Programm_5" 6 "Programm_6" 7 "Programm_7" 8 "Programm_8" 9 "Programm_9" 10 "Programm_10" 11 "Programm_11" 12 "Programm_12" 13 "Programm_13" 14 "Programm_14" 15 "Programm_15" ;
VAL_ 812 MO_StSt_Charisma_Status 0 "Init" 1 "verfuegbar" 2 "nicht_verfuegbar" 3 "asynchron_durch_Fahrerwunsch" ;
VAL_ 812 MO_BZS_Charisma_FahrPr 0 "keine_Funktion" 1 "Programm_1" 2 "Programm_2" 3 "Programm_3" 4 "Programm_4" 5 "Programm_5" 6 "Programm_6" 7 "Programm_7" 8 "Programm_8" 9 "Programm_9" 10 "Programm_10" 11 "Programm_11" 12 "Programm_12" 13 "Programm_13" 14 "Programm_14" 15 "Programm_15" ;
VAL_ 812 MO_BZS_Charisma_Status 0 "Init" 1 "verfuegbar" 2 "nicht_verfuegbar" 3 "asynchron_durch_Fahrerwunsch" ;
VAL_ 812 MO_NGS_Position 0 "Neutralposition_nicht_erkannt" 1 "Neutralposition_erkannt" ;
VAL_ 812 MO_NGS_Status 0 "nicht_verbaut" 1 "nicht_plausibilisiert" 2 "plausibilisiert" 3 "Fehler" ;
VAL_ 812 MO_v_Begrenzung_Niveau 0 "keine_Begrenzung_aktiv" 1 "Sicherheitsbegrenzung_1_aktiv" 2 "Sicherheitsbegrenzung_2_aktiv" 3 "Komfortbegrenzung_aktiv" ;
VAL_ 1648 MO_ANC_Kennfeld_Anf 0 "Kennfeld_1" 1 "Uebergang_Kennfeld_2_nach_1" 2 "Uebergang_Kennfeld_1_nach_2" 3 "Kennfeld_2" ;
VAL_ 1648 MO_Bremslicht_Reku 0 "Aus" 1 "Ein" ;
VAL_ 1648 MO_StartStopp_PopUp 0 "Statuswechsel_ohne_Taster (Init)" 1 "StSt_per_Taster_deaktiviert" 2 "StSt_per_Taster_aktiviert" 3 "nicht verwendet" ;
VAL_ 1648 MO1_Sperr_Info_WFS 0 "nicht_gesperrt" 1 "gesperrt" ;
VAL_ 1648 MO1_Freigabe_Info_WFS 0 "ungueltig" 1 "gueltig" ;
VAL_ 1648 MO_EPCL 0 "EPCL_aus_kein_Text" 1 "EPCL_gelb_Stoerung" 2 "EPCL_gelb_Leistungsbeschraenkung" 3 "EPCL_rot_Fzg_sicher_abstellen" ;
VAL_ 1648 MO_Zylabsch_Texte_02 0 "ein_ZAS_generell_keine_ZAS_Anzeigen" 1 "ZAS_im_VMB" 2 "ZAS_im_ASB_1_Zyl_aktiv" 3 "ZAS_im_ASB_2_Zyl_aktiv" 4 "ZAS_im_ASB_3_Zyl_aktiv" 5 "ZAS_im_ASB_4_Zyl_aktiv" 6 "ZAS_im_ASB_5_Zyl_aktiv" 7 "ZAS_im_ASB_6_Zyl_aktiv" 8 "ZAS_im_ASB_8_Zyl_aktiv" 9 "ZAS_im_ASB_12_Zyl_aktiv" 13 "Uebergangsbetrieb" 14 "keine_ZAS_Anzeige_ggf_Stopp_Schub_Betrieb" 15 "ZAS_Stoerungs_Anzeige" ;
VAL_ 1648 MO_Fahrzeugtyp 0 "Verbrenner_Fahrzeug" 1 "Hybrid" 2 "E_Fahrzeug" 3 "E_Fahrzeug_mit_Range_Extender" 4 "Brennstoffzellenfahrzeug" 5 "tbd" 6 "tbd" 7 "tbd" ;
VAL_ 1648 MO_Abstellzeit 254 "Init" 255 "reserviert" ;
VAL_ 1648 MO_Abstellzeit_Status 0 "Abstellzeit_nicht_berechnet" 1 "Abstellzeit_berechnet" 2 "Abstellzeit_Minimalwert" 3 "Abstellzeit_ungueltig" ;
VAL_ 1648 MO1_Freigabe_Verfallsinfo_WFS 0 "verfaellt_nicht" 1 "verfaellt" ;
VAL_ 1648 MO_Hybrid_StartStopp_LED 0 "LED_aus_und_Blinken_aus" 1 "LED_ein_und_Blinken_aus" 2 "LED_ein_und_Blinken_ein_50_percent" 3 "reserviert" ;
VAL_ 1648 MO_Fehler_Zylabsch 0 "kein_Fehler" 1 "Notlauf_Vollmotorbetrieb" 2 "Notlauf_mindestens_einem_abgesch_Zylinder" ;
VAL_ 1648 MO_Anzahl_Abgesch_Zyl 0 "Vollmotorbetrieb" 1 "1_Zylinder_abgeschaltet" 2 "2_Zylinder_abgeschaltet" 3 "3_Zylinder_abgeschaltet" 4 "4_Zylinder_abgeschaltet" 5 "5_Zylinder_abgeschaltet" 6 "6_Zylinder_abgeschaltet" 7 "8_Zylinder_abgeschaltet" ;
VAL_ 1648 MO_Zylabsch_Texte 0 "keine_Texte" 1 "Zylinderabschaltung_deaktivieren" 2 "Zylinderabschaltung_aktivieren" 3 "Zylinderabschaltung_unruhig" ;
VAL_ 1648 MO_Ethanol_BS_Texte 0 "kein_Text" 1 "E85_Warm_Up" 2 "FlexFuel_Warnung_Stufe_3" 3 "Warmfahrempfehlung_MQB__FlexFuel_Warnung_Stufe_1" 4 "FlexFuel_Warnung_Stufe_2" 5 "FlexFuel_Warnung_Stufe_4" 6 "E25_Warm_Up" ;
VAL_ 1648 MO_Drehzahl_Warnung 0 "keinen_Warnhinweis_anzeigen" 1 "Warnhinweis_anzeigen" ;
VAL_ 1648 MO_obere_Drehzahlgrenze 0 "Init" ;
VAL_ 815 MO_Anzeige_Rekuperation 0 "Init_und_nicht_verbaut" ;
VAL_ 815 PEA_Fortschrittsanzeige 127 "Neutralwert" ;
VAL_ 815 MO_Anzeige_Fahrbereitschaft 0 "OFF" 1 "READY" ;
VAL_ 815 MO_Boost_verfuegbar 0 "Init" 253 "Nicht_verbaut" 254 "Funktion_deaktiv" 255 "Fehler" ;
VAL_ 815 MO_Overboost 0 "inaktiv" 1 "aktiv" ;
VAL_ 815 MO_Boost_aktiv 0 "kein_Boost_aktiv" 1 "Boost_aktiv" ;
VAL_ 815 MO_Anzeige_Betriebsmodus 0 "Init_keine_Anzeige" 1 "EV" 2 "Auto" 3 "Hold" 4 "Charge" 5 "GTE" 6 "ECO" 7 "SPORT" 8 "Auto_praediktiv" 9 "Manuell_SOC_erhoehen" 10 "Manuell_SOC_halten" 11 "Manuell_SOC_verringern" ;
VAL_ 815 PEA_Hinweis 0 "keine_Anzeige" 1 "Anzeige_Fusssymbol_1" 2 "Anzeige_Fusssymbol_2" 3 "Anzeige_Auskuppeln" ;
VAL_ 815 PEA_Ereignisanzeige 0 "keine_Anzeige" 1 "Linkskurve_voraus" 2 "Rechtskurve_voraus" 3 "Kreuzung_voraus" 4 "Gefaelle_voraus" 5 "Kreisverkehr_voraus" 6 "Fahrzeug_voraus" 7 "Tempolimit_voraus" 8 "Ereignis_voraus" 9 "Autobahnabfahrt_voraus" 10 "Autobahnauffahrt_voraus" 11 "Abbiegung_links_voraus" 12 "Abbiegung_rechts_voraus" 13 "Ortseinfahrt_voraus" 14 "Autobahnabfahrt_links_voraus" ;
VAL_ 815 PEA_Ereignisanzeige_temporaer 0 "keine_Anzeige" 1 "Anzeige_temporaer" ;
VAL_ 815 PEA_Abschalttexte 0 "keine_Anzeige" 1 "PEA_ausserhalb_Einsatzgebiet" 2 "PEA_temporaer_nicht_verfuegbar" 3 "PEA_vom_Fahrer_deaktiviert" ;
VAL_ 815 PEA_Zielgeschw_Einheit 0 "km_h" 1 "mph" ;
VAL_ 815 PEA_Zielgeschw 0 "keine_Anzeige" 1 "Wert_5" 2 "Wert_10" 3 "Wert_15" 4 "Wert_20" 5 "Wert_25" 6 "Wert_30" 7 "Wert_35" 8 "Wert_40" 9 "Wert_45" 10 "50" 11 "Wert_55" 12 "Wert_60" 13 "Wert_65" 14 "Wert_70" 15 "Wert_75" 16 "Wert_80" 17 "Wert_85" 18 "Wert_90" 19 "Wert_95" 20 "Wert_100" 21 "Wert_105" 22 "Wert_110" 23 "Wert_115" 24 "Wert_120" 25 "Wert_125" 26 "Wert_130" 27 "Wert_140" 28 "Wert_150" 29 "Wert_160" ;
VAL_ 815 MO_Antriebsstrang_Warnung_HS 0 "Keine_Anzeige" 1 "Fehlereskalationsstufe_I" 2 "Fehlereskalationsstufe_II" 3 "Fehlereskalationsstufe_III" ;
VAL_ 1391 MO_Anzeige_Aufheizfortschritt 126 "Init" 127 "Fehler" ;
VAL_ 1391 MO_IstLeistung_EKAT 126 "Init" 127 "Fehler" ;
VAL_ 1391 MO_HYB_Drehzahl_VM 65280 "Fehler" ;
VAL_ 967 MO_Kuehlerluefter_MUX 0 "Kuehlerluefter_1" 1 "Kuehlerluefter_2" ;
VAL_ 967 MO_Kuehlerluefter_1 126 "Init" 127 "Fehler" ;
VAL_ 967 MO_Kuehlerluefter_2 126 "Init" 127 "Fehler" ;
VAL_ 967 MO_EFLEX_Lampe 0 "Lampe_aus" 1 "Lampe_ein" 2 "Lampe_blinkend" 3 "Lampe_blinkend_mit_Akustik" ;
VAL_ 967 MO_KJS_nicht_bereit 0 "kein_Fehler" 1 "Fehler" ;
VAL_ 967 MO_ITM_Warnung_Pumpe 0 "keine_Warnung" 1 "ITM_Warnung" ;
VAL_ 967 WIV_Anzeige_aktiv 0 "Anzeige aus" 1 "WIV Anzeige aktiv" ;
VAL_ 967 WIV_Oelmin_Warn 0 "in_Ordnung" 1 "Warnung" ;
VAL_ 967 WIV_Sensorfehler 0 "in_Ordnung" 1 "Sensor_defekt" ;
VAL_ 967 WIV_Schieflage 0 "Fahrzeug_gerade" 1 "Fahrzeug_in_Schieflage" ;
VAL_ 967 MO_Zustand_HWP 0 "HWP_nicht_schaltbar" 1 "HWP_foerdert_nicht" 2 "HWP_foerdert" 3 "reserviert" ;
VAL_ 967 OLEV_Systemstoerung 0 "Ölsystem i.O." 1 "Systemstörung Ölsystem" ;
VAL_ 967 MO_Oelwarnung_max 0 "keine_Warnung" 1 "Warnfall_aktiv" ;
VAL_ 967 WIV_Oelsystem_aktiv 0 "Anzeige_aus" 1 "Anzeige_aktiv" ;
VAL_ 967 WIV_nicht_betriebswarm 0 "Motor_warm" 1 "Motor_nicht_betriebswarm" ;
VAL_ 967 WIV_Ueberfuell_Warn 0 "in_Ordnung" 1 "Ueberfuellwarnung" ;
VAL_ 967 WIV_laufender_Motor 0 "Messung_moeglich" 1 "Messung_nicht_moeglich" ;
VAL_ 967 MO_E_Warnungen 0 "keine_Anzeige" 1 "Fehler_Elektrosystem_Anhalten" 2 "Fehler_Elektrosystem_Werkstatt" 3 "Elektrosystem_ueberhitzt_Stopp" 4 "Fehler_Hybridsystem_Anhalten" 5 "Fehler_Hybridsystem_Werkstatt" 6 "Fehler_Wasserstoffsystem_Anhalte" 7 "Fehler_Wasserstoffsystem_Werksta" 8 "reserviert_keine_Anzeige" 9 "reserviert_keine_Anzeige" 10 "reserviert_keine_Anzeige" 11 "reserviert_keine_Anzeige" 12 "reserviert_keine_Anzeige" 13 "reserviert_keine_Anzeige" 14 "reserviert_keine_Anzeige" 15 "reserviert_keine_Anzeige" ;
VAL_ 967 MO_Text_Motorstart 0 "keine_Anzeige" 1 "Motor_im_Stoppbetrieb" 2 "StartStopp_sicherheitsbedingt_deaktiviert" 3 "System_fordert_Wiederstart" 4 "Aufforderung_Motorstart" 5 "Motorlauf_noetig" 6 "Motorlaufwarnung" 9 "Unerwuenschter_Motorstillstand" 10 "Motorstart_nicht_moeglich" 11 "Fehler_Kupplungsschalter" 12 "Motor_startet" 13 "Kupplung_betaetigen" 14 "Waehlhebel_in_PN_Position" 15 "Bremse_treten" ;
VAL_ 967 MO_E_Texte 0 "keine_Anzeige" 1 "Batterie_fast_leer" 2 "Ladestecker_nicht_fahrbereit" 3 "VM_Betrieb_erforderlich" 4 "Batterie_laedt_Nicht_ausschalten" 5 "Bitte_Bremse_treten" 6 "manueller_Neustart_erforderlich" 7 "Stopp_Fahrzeug_nicht_abschleppen" 8 "kein_Neustart_Haube_nicht_oeffnen" 9 "Motorstart_im_naechsten_Zyklus" 10 "VM_erforderlich_EVMode_abwaehlen" 11 "laengerer_VMBetrieb_Bordbuch" 12 "Tank_leer_VM_nicht_verfuegbar" 13 "Bitte_warten_Motor_startet" 14 "kein_Start_Batterietemperatur" 15 "Ende_elektrische_Reichweite_erreicht" ;
VAL_ 967 WIV_Oeldyn_avl 0 "Oeldyn_nicht_vorhanden" 1 "Oeldyn_vorhanden" ;
VAL_ 967 OLEV_Oelstand_nicht_vorhanden 0 "Ölstand vorhanden" 1 "Ölstand nicht vorhanden" ;
VAL_ 967 MO_Systemlampe 0 "Lampe aus" 1 "Lampe ein" ;
VAL_ 967 MO_OBD2_Lampe 0 "Lampe aus" 1 "Lampe ein" ;
VAL_ 967 MO_Heissleuchte 0 "Lampe aus" 1 "Lampe ein" ;
VAL_ 967 MO_Partikel_Lampe 0 "Lampe aus" 1 "Lampe ein" ;
VAL_ 967 MO_RedFahrleistung_Lampe 0 "Lampe_aus" 1 "Lampe_ein" ;
VAL_ 967 WIV_Oelstand_nicht_vorhanden 0 "Ölstand vorhanden" 1 "Ölstand nicht vorhanden" ;
VAL_ 967 WIV_nachfuellanzeige_ein 0 "keine_Nachfuellanzeige" 1 "Nachfuellanzeige" ;
VAL_ 967 WIV_Ueberfuell_deaktiv 0 "Ueberfuellwarnung_am_Kombi_aktiv" 1 "Ueberfuellwarnung_am_Kombi_deaktiv" ;
VAL_ 967 WIV_Unterfuell_Warn 0 "in_Ordnung" 1 "Unterfuellwarnung" ;
VAL_ 967 MO_Tankdeckel_Lampe 0 "Lampe aus" 1 "Lampe ein" ;
VAL_ 967 MO_Text_Tankdeckelwarn 0 "kein_Text" 1 "Anzeige_Text_Tankdeckelwarnung_im_Kombi" ;
VAL_ 967 MO_Vorglueh_Lampe 0 "Lampe_aus" 1 "Lampe_ein" ;
VAL_ 967 WIV_Oeldr_Warn_Motor 0 "keine_Warnung" 1 "niedrige_Oeldruckstufe_nicht_erreicht" ;
VAL_ 967 MO_E_Mode 0 "keine_Anzeige" 1 "E_Mode_passiv" 2 "E_Mode_aktiv" 3 "E_Mode_inaktiv_nicht_verfuegbar" 4 "E_Mode_aktiv_nicht_verfuegbar" 5 "reserviert_keine_Anzeige" 6 "reserviert_keine_Anzeige" 7 "reserviert_keine_Anzeige" ;
VAL_ 327 MO_EM1_SumRadMomReku_Ist 255 "Fehler" ;
VAL_ 327 MO_eATL_Status_Anzeige 0 "Freilauf" 1 "Rekuperation" 2 "Boost" 3 "Fehler" ;
VAL_ 327 MO_Anzeige_Kaltabfahrbegrenzung 0 "nicht_aktiv" 1 "VoKo_VKM_aus" 2 "VoKo_VKM_an" 3 "VoKo_mit_Elektrisch_Fahren" 4 "Leistungsbegrenzung" 5 "Emissionsnotstart" 6 "Init" 7 "Reserved" ;
VAL_ 327 MO_Hochschaltdrehz 0 "keine_manuelle_Hochschaltung" 4095 "Fehler" ;
VAL_ 327 MO_Anzeige_Verbr_Einheit 0 "l_h" 1 "kg_h" ;
VAL_ 327 MO_Schaltblitz_Anz 101 "blinkende_Anzeige" 126 "Init_Funktion_nicht_aktiv" 127 "Fehler" ;
VAL_ 327 MO_Anzeige_Drehmoment 2046 "nicht_verbaut" 2047 "Fehler" ;
VAL_ 327 MO_Anzeige_Leistung 2046 "nicht_verbaut" 2047 "Fehler" ;
VAL_ 1366 MO_Fahrzeugabstellzeit_Status 0 "Abstellzeit_nicht_berechnet" 1 "Abstellzeit_berechnet" 2 "Abstellzeit_Minimalwert" 3 "Abstellzeit_ungültig" ;
VAL_ 1366 MO_HV_Auszeit_Status 0 "Abstellzeit_nicht_berechnet" 1 "Abstellzeit_berechnet" 2 "Abstellzeit_Minimalwert" 3 "Abstellzeit_ungültig" ;
VAL_ 1366 MO_Fahrzeugabstellzeit 254 "Init" 255 "Fehler" ;
VAL_ 1366 MO_HV_Auszeit 510 "Init" 511 "Fehler" ;
VAL_ 1366 MO_Verbau_StartSys_Ritzelstarter 0 "nicht_verbaut" 1 "verbaut" ;
VAL_ 1366 MO_Verbau_StartSys_EM_MV 0 "nicht_verbaut" 1 "verbaut" ;
VAL_ 1366 MO_Verbau_StartSys_EM_HV 0 "nicht_verbaut" 1 "verbaut" ;
VAL_ 1366 MO_Verbau_StartSys_RSG_NV 0 "nicht_verbaut" 1 "verbaut" ;
VAL_ 1366 MO_Verbau_StartSys_Q_Diode 0 "nicht_verbaut" 1 "verbaut" ;
VAL_ 1366 MO_Verbau_StartSys_RSG_MV 0 "nicht_verbaut" 1 "verbaut" ;
VAL_ 1366 FWS_QBit_Koeffizient_2 0 "gueltiger_Wert" 1 "Ersatz_Init_oder_Fehlerwert" ;
VAL_ 1366 FWS_Koeffizient_2 254 "Init" 255 "Fehler" ;
VAL_ 1366 MO_Ziel_SoC_Fremdladung 254 "Init" ;
VAL_ 283 MO_Fahrbereitschaft 0 "Fahrzykl_inaktiv__kein_Antrieb" 1 "Fahrzykl_aktiv__kein_Antrieb" 2 "Fahrzykl_aktiv__Antrieb_moeglich" ;
VAL_ 283 MO_Freilauf_Info 0 "Freilauf_freigegeben" 1 "Weiches_Veto_uebertippbar" 2 "Hartes_Veto_Abbruch" 3 "Freilauf_Anforderung" ;
VAL_ 283 MO_Krit_Heckobjekt 0 "Init_kein_relevantes_Objekt" 1 "Entfernung_grosser_Abstand" 2 "Annaeherung_grosser_Abstand" 3 "Entfernung_geringer_Abstand" 4 "Annaeherung_geringer_Abstand" 7 "Fehler" ;
VAL_ 283 MO_NGS_Gangpos 0 "nicht_bedient" 1 "1_3_oder_5" 2 "2_4_6_oder_R" 3 "R" 4 "Neutralposition" 5 "Zwischenposition" 6 "Sensor_temp_nicht_verfuegbar" 7 "Fehler" ;
VAL_ 283 MO_Freilauf_Status 0 "Freilauf_inaktiv_aber_moeglich" 1 "Freilauf_aktiv" 2 "Freilauf_nicht_moegl_1Verhinderer" 3 "Freilauf_nicht_moegl_gr_1Verhinderer" 7 "Fehler" ;
VAL_ 283 MO_EBoost_verf_praed 0 "Init_oder_nicht_verfuegbar" 1 "EBoost_kurzzeit_verfuegbar" 2 "EBoost_langzeit_verfuegbar" ;
VAL_ 283 MO_Heckspoiler_Anf 0 "nicht_angefordert" 1 "angefordert" ;
VAL_ 283 MO_eLaunch_verf 0 "Init" 1 "nicht_verfuegbar" 2 "verfuegbar" ;
VAL_ 283 MO_Positionierung_aktiv 0 "keine_Positionierung_aktiv" 1 "Positionierung_aktiv" ;
VAL_ 283 MO_Parken_WFS_Status 0 "Limitierung_Inaktiv" 1 "Limitierung_Aktiv" 2 "Abbruch" ;
VAL_ 283 MO_Status_Katheizen 0 "Katheizen_nicht_aktiv" 1 "Katheizen_aktiv" ;
VAL_ 283 MO_Status_MIN_Wunschdrehzahl 0 "keine_OBD_oder_CSERS_Anforderung" 1 "CSERS_Anforderung" 2 "OBD_Anforderung_ausserhalb_CSERS" 3 "reserviert" ;
VAL_ 283 MO_Rennstart_verf 0 "nicht_verfuegbar" 1 "verfuegbar" ;
VAL_ 283 MO_AIAD_MaxLeistung 255 "Init" ;
VAL_ 2589283475 SCR_Zustand 0 "Initialisierung" 1 "Normale_Funktion" 2 "Hinweis_Fuellstand" 3 "Warnstufe_1" 4 "Warnstufe_2" 5 "Systemfehler_1" 6 "Systemfehler_2" 7 "Schraeglage" 8 "Gefrorenes_Medium" 9 "Keine_RRW_Anzeige" 10 "AdBlue_pruefen_RRW_deaktiv" 11 "AdBlue_pruefen_RRW_aktiv" 12 "reserved" 13 "reserved" 14 "reserved" 15 "reserved" ;
VAL_ 2589283475 SCR_Retriggersignal 0 "Retrigger_nicht_aktiv" 1 "Retrigger_aktiv" ;
VAL_ 2589283475 SCR_Nachfuellmenge_min 127 "Initwert" ;
VAL_ 2589283475 SCR_Nachfuellmenge_max 255 "Initwert" ;
VAL_ 2589283475 SCR_Nachfuellmenge_Einheit 0 "Liter" 1 "Gallone (US)" 2 "Gallone (UK)" 3 "reserved" ;
VAL_ 2589283475 SCR_Einheit 0 "km" 1 "miles" ;
VAL_ 2589283475 SCR_Fuellstand 127 "Initwert" ;
VAL_ 834 MO_E_Texte_LB 0 "no_text" 1 "ICE_starting_shortly" 2 "acc_ped_release_mode_change" 3 "range_extender_requested" 4 "elec_traction_not_available" 5 "hybrid_traction_requested" 6 "reserved" 7 "reserved" ;
VAL_ 834 MO_Energyflow 0 "init" 1 "vehicle_idle" 2 "engine_idle" 3 "engine_start" 4 "idle_charge" 5 "RWD_RAcharging" 6 "RWD_RAdischarging" 7 "AWD_RAcharging" 8 "AWD_RAassisting" 9 "AWD_RAdischarging" 10 "EV_FWD" 11 "EV_RWD" 12 "EV_AWD" 13 "Regenerative_braking_FA" 14 "Regenerative_braking_RA" 15 "Regenerative_braking_FA_RA" 16 "EV_Regenerative_braking_FA" 17 "EV_Regenerative_braking_RA" 18 "EV_Regenerative_braking_FA_RA" 19 "Recuperation_FA" 20 "Recuperation_RA" 21 "Recuperation_FA_RA" 22 "EV_Recuperation_FA" 23 "EV_Recuperation_RA" 24 "EV_Recuperation_FA_RA" 25 "range_extender" 26 "reserved" 27 "reserved" 28 "reserved" 29 "reserved" 30 "reserved" 31 "reserved" ;
VAL_ 834 MO_Wassertemp_Schutz_Anf 0 "Init" 1 "Protection_status_1" 2 "Protection_status_2" 3 "Protection_status_3" 4 "Protection_status_4" 5 "reserved" 6 "reserved" 7 "reserved" ;
VAL_ 834 MO_Sperrung_FahrPr_BZS_LB 0 "keine_Sperrung" 1 "Sperrung_BZS1" 2 "Sperrung_BZS2" 4 "Sperrung_BZS3" 8 "Sperrung_BZS4" 16 "Sperrung_BZS5" 32 "Sperrung_BZS6" 64 "Sperrung_BZS7" 128 "Sperrung_BZS8" ;
VAL_ 834 MO_TorqueDistrib_Hi 255 "Fehler" ;
VAL_ 834 MO_TorqueDistrib_VL 255 "Fehler" ;
VAL_ 834 MO_TorqueDistrib_VR 255 "Fehler" ;
VAL_ 706 MO_Anzeige_StSt_Text 0 "keine_Anzeige" 1 "Systemfehler" 2 "Motor_manuell_starten" 3 "Rueckmeldung_durch_Fahrstufe_einlegen" 4 "Zuendungsabschaltwarnung_Timerstart" 5 "Zum_Motorstart_Bremse_treten" 6 "StSt_Aktivierung_nicht_moeglich_auf_Grund_Fahrprogramm" ;
VAL_ 706 MO_Anzeige_StSt_Symbol 0 "keine_Anzeige" 1 "StSt_aktiv" 2 "Motorlauf_noetig" 3 "Fahrer_temporaer_abwesend" 4 "Fahrer_vielleicht_anwesend" ;
VAL_ 706 MO_ADR_Status 0 "nicht_aktiv" 1 "ADR_angefordert" 2 "ADR_aktiv" 3 "ADR_Fehler" ;
VAL_ 706 MO_AGA_Sound_Texte 0 "keine_Anzeige" 1 "Sound_off" 2 "Sound_on" ;
VAL_ 706 MO_Anzeige_FMAus_Text 0 "keine_Anzeige" 1 "FMAus_Systemfehler" ;
VAL_ 706 MO_Fehler_MSpG 0 "i.O." 1 "Gebläse defekt oder Motorraumtemp. zu hoch" ;
VAL_ 706 PEA_Texte 0 "Keine_Anzeige" 1 "PEA_Fahreruebernahme_noetig" 2 "PEA_Reku_nicht_verfuegbar" ;
VAL_ 706 TSK_Ueberstimmt_vMax_FahrerInfo 0 "nicht_ueberstimmbar" 1 "ueberstimmbar" 2 "ueberstimmt" ;
VAL_ 706 MO_Avus_Motorschutz 0 "keine Warnung" 1 "Drehzahlwarnung Stufe 1" 2 "Drehzahlwarnung Stufe 2" 3 "Drehzahlwarnung Stufe 3" ;
VAL_ 706 MO_Rekuperationsstufe 0 "keine_Anzeige" 1 "Rekuperationsstufe_1" 2 "Rekuperationsstufe_2" 3 "Rekuperationsstufe_3" 4 "Rekuperationsstufe_4" 5 "Rekuperationsstufe_5" 6 "Rekuperationsstufe_auto" 7 "Init" ;
VAL_ 706 TSK_Einheit_vMax_FahrerInfo 0 "km_h" 1 "mph" ;
VAL_ 706 TSK_Status_vMax_FahrerInfo 0 "keine_Anzeige" 1 "Anzeige_im_Fahrzeugstatus" 2 "PopUp_ohne_Gong__Eintrag_FhzStat" 3 "PopUp_mit_Gong__Eintrag_FhzStat" ;
VAL_ 706 MO_Red_Fahrleistung 0 "keine_Anzeige" 1 "kleine_Red" 2 "mittlere_Red_temp" 3 "mittlere_Red" 4 "grosse_Red_temp" 5 "grosse_Red" ;
VAL_ 706 MO_Oel_Temp_Radsatz_Warn 0 "iO_Temperatur" 1 "Uebertemperatur_Warnung" ;
VAL_ 706 MO_Anz_Kuehlerluefter 0 "Kein_KuehlerluefterNachlauf" 1 "Text_Luefternachlauf_aktiv" 2 "Text_Luefternachlauf_DPF_aktiv" 3 "Platzhalter_weitere_Signale" 4 "Platzhalter_weitere_Signale" 5 "Platzhalter_weitere_Signale" 6 "Platzhalter_weitere_Signale" 7 "Platzhalter_weitere_Signale" ;
VAL_ 706 MO_im_Leerlauf 0 "nicht_im_Leerlauf" 1 "im_Leerlauf" ;
VAL_ 706 WIV_Enable_Oeldr_Motor 0 "Oeldruckauswertung_im_Kombi" 1 "Oeldruckauswertung_im_MSG" ;
VAL_ 706 MO_OelMessung_Dauer 15 "keine_Messung_aktiv" ;
VAL_ 706 TSK_vMax_FahrerInfo 0 "Init___kein_Wert" ;
VAL_ 2589283599 MO_TME_KL_Anf_LB 126 "Init" 127 "Fehler" ;
VAL_ 2589283599 MO_Kilometerstand_Wakeup 1048574 "Init" 1048575 "Fehler" ;
VAL_ 2589283599 MO_Status_KL 0 "Kein_fehler" 1 "Fehler_KL_3" 2 "Fehler_KL_4" 3 "Fehler_KL_3_und_KL_4" ;
VAL_ 2589283599 MO_Eboost_LB_LVLavailable 0 "init" 1 "LB_eboost_level_1_available" 2 "LB_eboost_level_1_2_available" 3 "LB_eboost_level_1_2_3_available" ;
VAL_ 2589283599 MO_Eboost_LB_possible 0 "LB_eboost_not_possible" 1 "LB_eboost_possible" ;
VAL_ 2589283599 MO_Eboost_LB_active 0 "LB_eboost_not_active" 1 "LB_eboost_active" ;
VAL_ 2589283599 MO_Eboost_LB_available 0 "LB_eboost_not_available" 1 "LB_eboost_available" ;
VAL_ 2589283599 MO_Eboost_LB_driveraction 0 "init" 1 "change_DM_PS" 2 "press_accelerator" 3 "ready" ;
VAL_ 2589283599 MO_Eboost_LB_failure 0 "no_failure" 1 "failure" ;
VAL_ 2589283599 MO_Eboost_LB_LVLselected 0 "init" 1 "LB_eboost_level_1_selected" 2 "LB_eboost_level_2_selected" 3 "LB_eboost_level_3_selected" ;
VAL_ 2589283599 MO_CatHeatBar_LB 126 "Init" 127 "Fehler" ;
VAL_ 1601 MO_Faktor_Momente_02 0 "nicht_belegt" ;
VAL_ 1601 MO_Hybridfahrzeug 0 "kein_Hybridfahrzeug" 1 "Mild_Hybrid" 2 "Full_Hybrid" 3 "PlugIn_Hybrid" ;
VAL_ 1601 MO_Getriebe_Code 0 "Init" 2 "DL501" 3 "DL800" 4 "VL381" 5 "DL382_Front" 6 "DL382_Allrad" 7 "DL702" 8 "AL552_Allrad" 9 "AL552_Front" 10 "AL651" 11 "AL551__AL951__AL1000_8A" 12 "PDK_PAG" 13 "AL551_Hybrid" 15 "Handschalter_konventionell" 16 "AQ250_160" 17 "AQ450" 18 "DQ200" 19 "DQ250" 20 "DQ500" 21 "SQ100" 22 "SQ200" 23 "DQ400E" 24 "DQ381" 25 "AL550" 26 "AQ300" 31 "DL800E" 32 "Single_Gear__ohne_GSG_WH_am_MSG" 33 "EQ550_2P" ;
VAL_ 1601 MO_StartStopp_Codiert 0 "Start_Stopp_nicht_verbaut" 1 "Start_Stopp_verbaut" ;
VAL_ 1601 MO_Anzeige_StSt_gueltig 0 "MO_Text_Motorstart_gueltig" 1 "Signale_MO_Anzeige_StSt_gueltig" ;
VAL_ 1601 MO_Anzahl_Zyl 0 "kein_Zylinder" 1 "1_Zylinder" 2 "2_Zylinder" 3 "3_Zylinder" 4 "4_Zylinder" 5 "5_Zylinder" 6 "6_Zylinder" 7 "7_Zylinder" 8 "8_Zylinder" 9 "9_Zylinder" 10 "10_Zylinder" 11 "11_Zylinder" 12 "12_Zylinder" 13 "15_Zylinder" 14 "16_Zylinder" 15 "18_Zylinder" ;
VAL_ 1601 MO_Kraftstoffart 0 "Diesel" 1 "Benzin_inkl_E25_E85" 2 "CNG" 3 "LPG" 4 "Wasserstoff" 5 "E100_Ethanol" 15 "kein_Verbrennungskraftstoff" ;
VAL_ 1601 MO_Ansaugsystem 0 "Turbo" 1 "Sauger" ;
VAL_ 1601 MO_OBD_Typ 0 "NoOBD_RdW" 1 "EOBD" 2 "US_OBD" 3 "reserviert" ;
VAL_ 1601 MO_DPF_verbaut 0 "kein_DPF_verbaut" 1 "DPF_verbaut" ;
VAL_ 1601 TSK_Codierung 0 "kein_Fahrgeschwindigkeitsregler" 1 "GRA" 2 "GRA_Plus" 3 "Basis_ACC" 4 "ACC_Follow_to_Stop" 5 "ACC_Stop_and_Go" 7 "Codierung_in_Plausibilisierungsphase" ;
VAL_ 813 MO_AnzeigeGasbetrieb 0 "keine_Textmeldung" 1 "Umschaltung_Gasbetrieb" 2 "Gasbetrieb" 3 "Umschaltung_Benzinbetrieb" 4 "Benzinbetrieb" 5 "Umschaltung_nicht_moeglich" 6 "Gasbetrieb_nicht_moeglich" 7 "Benzintank_leer" 8 "GAP_CNG_Betrieb_verhindert" ;
VAL_ 813 MO_akt_Betrieb 0 "Benzinbetrieb" 1 "Gasbetrieb" ;
VAL_ 813 MO_Erdgasqualitaet 0 "Anzeige_in_MFA_Rolle_nicht_auswaehlbar" 1 "Qualitaet_xxx" 2 "Qualitaet_100" 3 "Qualitaet_90" 4 "Qualitaet_80" 5 "Qualitaet_70" 6 "Qualitaet_xxx" 7 "Qualitaet_xxx" ;
VAL_ 813 MO_Verbrauchsaequivalent 0 "Funktion_nicht_unterstuetzt" 254 "Init_Adaption_nach_Betankung" 255 "Fehler" ;
VAL_ 813 MO_CNG_LPG 0 "CNG" 1 "LPG" ;
VAL_ 813 MO_Fuellstand_LPG 1022 "ungueltig" 1023 "Fehler" ;
VAL_ 813 MO_CNG_Tankstopp 0 "kein_Tankstopp" 1 "Tankstopp_erkannt" ;
VAL_ 813 MO_LPG_Tankstopp 0 "kein_Tankstopp" 1 "Tankstopp_erkannt" ;
VAL_ 813 MO_Tankmasse_CNG 0 "Init" 255 "Fehler" ;
VAL_ 813 MO_Tankvolumen_LPG 0 "Init" 255 "Fehler" ;
VAL_ 813 MO_Fuellungsgrad_CNG 254 "Init" 255 "Fehler" ;
VAL_ 813 MO_Fuellungsgrad_LPG 254 "Init_ungueltig" 255 "Fehler" ;
VAL_ 813 MO_CNG_Ueberlauf 0 "kein_Ueberlauf" 1 "mind_1_Ueberlauf" ;
VAL_ 813 MO_LPG_Ueberlauf 0 "kein_Ueberlauf" 1 "mind_1_Ueberlauf" ;
VAL_ 305 MO_ePowermeter 0 "Init_keine_Anzeige" 254 "Funktion_deaktiv_Anzeige_ausgegraut" 255 "Fehler_keine_Anzeige" ;
VAL_ 305 MO_ePerformance 0 "Init" 254 "Funktion_deaktiv_Anz_ausgegraut" 255 "Fehler" ;
VAL_ 305 MO_Zust_Antrieb 0 "VM bzw. Brennstoffz. aktiv" 1 "EM aktiv" 2 "VM bzw. Brennstoffz. u. EM aktiv" 3 "Segeln oder Reku aktiv" ;
VAL_ 305 MO_Zust_Betriebsstrategie 0 "Kein Hybrid" 1 "Depleting" 2 "Soft-Depleting " 3 "Sustaining" 4 "Increasing" 5 "Fremdgesteuert" ;
VAL_ 305 Ladezustand_02 254 "Init" 255 "Fehler" ;
VAL_ 305 MO_Powermeter_Elm_02 0 "nicht_verbaut" 4094 "Init" ;
VAL_ 305 MO_Powermeter 4093 "Off" ;
VAL_ 1376 MO_HV_Spannungsfreiheit 0 "HV_System_nicht_spannungsfrei" 1 "frei" 2 "frei" 3 "HV_System_spannungsfrei" ;
VAL_ 1376 MO_Gesamtst_Spgfreiheit 0 "Init" 1 "HV_Komponente_spannungsfrei" 2 "HV_Komp_nicht_spannungsfrei" 3 "Fehler_nicht_spannungsfrei" ;
VAL_ 1376 MO_Tankbereitschaft_Status 0 "keine_Aktion_Init" 1 "Tankbereitschaft_wird_hergestellt" 2 "Tankbereitschaft_ist_hergestellt" 3 "Tankbereitschaft_kann_nicht_hergestellt_werden" 4 "Tanksystem_Systemfehler" 5 "Tankklappe_pruefen_schliessen" 6 "Tankvorgang_abgebrochen" ;
VAL_ 1376 MO_HYB_Status_Betriebsstrategie 0 "Init" 1 "Aktiv" 2 "Passiv_VKM_Ein" 3 "Passiv_VKM_Aus__HV_Verbraucher_Aus" 4 "Passiv_VKM_Aus__HV_Verbraucher_Ein" ;
